VERSION "dbc-export 1 2025.20.8"

NS_ :

BS_:

BU_: ADSP APB APP APS APSB BB BMS CC CMP CMPD CP DAS DI DIF DIR DPB EPAS3P EPAS3S EPASTP EPASTS EPBL EPBR ESP EVSE FC GTW HCML HCMR HVP IBST ICR IDB LS OCS1P PARK PCS PM PMF PMR PNCD PTC RADC RCM RCM2 RCM3 RCU SCCM SCM SCS SDCR TAS TCU TPMS TRCM UI UIS UMC USM VC VCFRONT VCLEFT VCRIGHT VCSEC VEH

BO_ 1294 CP_alertLog: 8 CP
 SG_ CP_alertID M : 0|15@1+ (1,0) [0|32767] "" Vector__XXX
 SG_ CP_alertType : 15|1@1+ (1,0) [0|1] "" Vector__XXX
 SG_ CP_a004_proximityV m4 : 16|16@1+ (0.0001,0) [0|6.5535] "" Vector__XXX
 SG_ CP_a004_cc1Voltage m4 : 32|14@1+ (0.001,0) [0|16.383] "" Vector__XXX
 SG_ CP_a004_cc2Voltage m4 : 48|14@1+ (0.001,0) [0|16.383] "" Vector__XXX
 SG_ CP_a005_cc1Voltage m5 : 16|11@1+ (0.00649731326848,0) [0|13.3000002606] "" Vector__XXX
 SG_ CP_a005_cc2Voltage m5 : 27|9@1+ (0.009784736,0) [0|5.000000096] "" Vector__XXX
 SG_ CP_a005_gbdcState m5 : 36|4@1+ (1,0) [0|15] "" Vector__XXX
 SG_ CP_a005_packCurrent m5 : 40|12@1+ (0.0976801,0) [0|400.0000095] "" Vector__XXX
 SG_ CP_a005_evseCurrent m5 : 52|10@1+ (0.391006857157,0) [0|400.000014872] "" Vector__XXX
 SG_ CP_a005_superchargerConnected m5 : 62|1@1+ (1,0) [0|1] "" Vector__XXX
 SG_ CP_a005_latchEngaged m5 : 63|1@1+ (1,0) [0|1] "" Vector__XXX
 SG_ CP_a006_BMS_FC_limits_MIA m6 : 16|1@1+ (1,0) [0|1] "" Vector__XXX
 SG_ CP_a006_BMS_chargeStatus_MIA m6 : 17|1@1+ (1,0) [0|1] "" Vector__XXX
 SG_ CP_a006_BMS_dcChargeLimits_MIA m6 : 18|1@1+ (1,0) [0|1] "" Vector__XXX
 SG_ CP_a006_BMS_hvPackStatus_MIA m6 : 19|1@1+ (1,0) [0|1] "" Vector__XXX
 SG_ CP_a006_BMS_kwhCounter_MIA m6 : 20|1@1+ (1,0) [0|1] "" Vector__XXX
 SG_ CP_a006_BMS_socStatus_MIA m6 : 21|1@1+ (1,0) [0|1] "" Vector__XXX
 SG_ CP_a008_data1 m8 : 16|16@1+ (1,0) [0|65535] "" Vector__XXX
 SG_ CP_a008_data2 m8 : 32|16@1+ (1,0) [0|65535] "" Vector__XXX
 SG_ CP_a008_FlashWarning m8 : 48|1@1+ (1,0) [0|1] "" Vector__XXX
 SG_ CP_a008_RAMconst_Warning m8 : 49|1@1+ (1,0) [0|1] "" Vector__XXX
 SG_ CP_a008_RAMconst_Fault m8 : 50|1@1+ (1,0) [0|1] "" Vector__XXX
 SG_ CP_a008_AllMemory_warnings m8 : 51|1@1+ (1,0) [0|1] "" Vector__XXX
 SG_ CP_a008_StackAlert m8 : 52|1@1+ (1,0) [0|1] "" Vector__XXX
 SG_ CP_a008_stackUsed m8 : 56|7@1+ (1,0) [0|127] "" Vector__XXX
 SG_ CP_a009_cover1OpenCounts m9 : 16|12@1+ (0.025,0) [0|102.375] "" Vector__XXX
 SG_ CP_a009_cover2OpenCounts m9 : 28|12@1+ (0.025,0) [0|102.375] "" Vector__XXX
 SG_ CP_a009_cover1State m9 : 40|3@1+ (1,0) [0|7] "" Vector__XXX
 SG_ CP_a009_cover2State m9 : 43|3@1+ (1,0) [0|7] "" Vector__XXX
 SG_ CP_a010_periodValid m10 : 16|1@1+ (1,0) [0|1] "" Vector__XXX
 SG_ CP_a010_widthValid m10 : 17|1@1+ (1,0) [0|1] "" Vector__XXX
 SG_ CP_a010_voltageValid m10 : 18|1@1+ (1,0) [0|1] "" Vector__XXX
 SG_ CP_a010_pilotHigh m10 : 19|12@1- (0.008,0) [-16.384|16.376] "" Vector__XXX
 SG_ CP_a010_pilotLow m10 : 32|12@1- (0.008,0) [-16.384|16.376] "" Vector__XXX
 SG_ CP_a010_evseAccept m10 : 44|1@1+ (1,0) [0|1] "" Vector__XXX
 SG_ CP_a010_pilotPWMdetected m10 : 45|1@1+ (1,0) [0|1] "" Vector__XXX
 SG_ CP_a011_eepromErrorType m11 : 16|3@1+ (1,0) [0|7] "" Vector__XXX
 SG_ CP_a015_apsVoltageOV m15 : 16|8@1+ (0.07128516,0) [0|18.1777158] "" Vector__XXX
 SG_ CP_a016_apsVoltageUV m16 : 16|8@1+ (0.07128516,0) [0|18.1777158] "" Vector__XXX
 SG_ CP_a017_5V_VoltageOV m17 : 16|8@1+ (0.02352539,0) [0|5.99897445] "" Vector__XXX
 SG_ CP_a018_5V_VoltageUV m18 : 16|8@1+ (0.02352539,0) [0|5.99897445] "" Vector__XXX
 SG_ CP_a023_stopChargeReason m23 : 16|4@1+ (1,0) [0|15] "" Vector__XXX
 SG_ CP_a023_failureReason m23 : 20|2@1+ (1,0) [0|3] "" Vector__XXX
 SG_ CP_a023_chargeAttempts m23 : 24|3@1+ (1,0) [0|7] "" Vector__XXX
 SG_ CP_a028_canEnable m28 : 16|1@1+ (1,0) [0|1] "" Vector__XXX
 SG_ CP_a028_hardlineEnable m28 : 17|1@1+ (1,0) [0|1] "" Vector__XXX
 SG_ CP_a029_CP_pilot m29 : 16|3@1+ (1,0) [0|7] "" Vector__XXX
 SG_ CP_a029_CP_proximity m29 : 19|2@1+ (1,0) [0|3] "" Vector__XXX
 SG_ CP_a029_CP_chargeDoorOpen m29 : 21|1@1+ (1,0) [0|1] "" Vector__XXX
 SG_ CP_a031_apsVoltage m31 : 16|8@1+ (0.07156863,0) [0|18.25000065] "" Vector__XXX
 SG_ CP_a031_doorCountsFiltered m31 : 24|12@1+ (0.025,0) [0|102.375] "" Vector__XXX
 SG_ CP_a031_inductiveSensorFiltered m31 : 36|18@1+ (82.77924,0) [0|21699998.3113] "" Vector__XXX
 SG_ CP_a031_hallSensorFiltered m31 : 54|10@1+ (0.00488748773932,0) [0|4.99989995732] "" Vector__XXX
 SG_ CP_a032_apsVoltage m32 : 16|8@1+ (0.07156863,0) [0|18.25000065] "" Vector__XXX
 SG_ CP_a032_doorCountsFiltered m32 : 24|12@1+ (0.025,0) [0|102.375] "" Vector__XXX
 SG_ CP_a032_inductiveSensorFiltered m32 : 36|18@1+ (82.77924,0) [0|21699998.3113] "" Vector__XXX
 SG_ CP_a032_hallSensorFiltered m32 : 54|10@1+ (0.00488748773932,0) [0|4.99989995732] "" Vector__XXX
 SG_ CP_a035_latchState m35 : 16|2@1+ (1,0) [0|3] "" Vector__XXX
 SG_ CP_a035_stateLeverMovedFrom m35 : 18|2@1+ (1,0) [0|3] "" Vector__XXX
 SG_ CP_a035_latchOffset m35 : 24|16@1- (0.003051851,0) [-100.003053568|100.000001717] "" Vector__XXX
 SG_ CP_a035_inletID m35 : 40|2@1+ (1,0) [0|3] "" Vector__XXX
 SG_ CP_a036_latchCountsFiltered m36 : 16|16@1+ (0.00152590218931,0) [0|99.9999999764] "" Vector__XXX
 SG_ CP_a036_latchState m36 : 32|2@1+ (1,0) [0|3] "" Vector__XXX
 SG_ CP_a036_CHG_InsertEnable m36 : 34|1@1+ (1,0) [0|1] "" Vector__XXX
 SG_ CP_a036_CP_latchEnableCmd m36 : 35|1@1+ (1,0) [0|1] "" Vector__XXX
 SG_ CP_a036_CP_apsVoltage m36 : 40|8@1+ (0.07156863,0) [0|18.25000065] "" Vector__XXX
 SG_ CP_a036_inletID m36 : 48|2@1+ (1,0) [0|3] "" Vector__XXX
 SG_ CP_a037_latchCountsFiltered m37 : 16|16@1+ (0.00152590218931,0) [0|99.9999999764] "" Vector__XXX
 SG_ CP_a037_latchState m37 : 32|2@1+ (1,0) [0|3] "" Vector__XXX
 SG_ CP_a037_CHG_InsertEnable m37 : 34|1@1+ (1,0) [0|1] "" Vector__XXX
 SG_ CP_a037_CP_latchEnableCmd m37 : 35|1@1+ (1,0) [0|1] "" Vector__XXX
 SG_ CP_a037_CP_apsVoltage m37 : 40|8@1+ (0.07156863,0) [0|18.25000065] "" Vector__XXX
 SG_ CP_a037_inletID m37 : 48|2@1+ (1,0) [0|3] "" Vector__XXX
 SG_ CP_a038_latchCountsFiltered m38 : 16|16@1+ (0.00152590218931,0) [0|99.9999999764] "" Vector__XXX
 SG_ CP_a038_latchState m38 : 32|2@1+ (1,0) [0|3] "" Vector__XXX
 SG_ CP_a038_CHG_InsertEnable m38 : 34|1@1+ (1,0) [0|1] "" Vector__XXX
 SG_ CP_a038_CP_latchEnableCmd m38 : 35|1@1+ (1,0) [0|1] "" Vector__XXX
 SG_ CP_a038_CP_apsVoltage m38 : 40|8@1+ (0.07156863,0) [0|18.25000065] "" Vector__XXX
 SG_ CP_a038_inletID m38 : 48|2@1+ (1,0) [0|3] "" Vector__XXX
 SG_ CP_a041_doorCounts m41 : 16|16@1+ (0.002,0) [0|131.07] "" Vector__XXX
 SG_ CP_a041_inductiveSensorFiltered m41 : 32|18@1+ (82.77924,0) [0|21699998.3113] "" Vector__XXX
 SG_ CP_a041_hallSensorFiltered m41 : 50|10@1+ (0.00488748773932,0) [0|4.99989995732] "" Vector__XXX
 SG_ CP_a042_doorCounts m42 : 16|16@1+ (0.002,0) [0|131.07] "" Vector__XXX
 SG_ CP_a042_inductiveSensorFiltered m42 : 32|18@1+ (82.77924,0) [0|21699998.3113] "" Vector__XXX
 SG_ CP_a042_hallSensorFiltered m42 : 50|10@1+ (0.00488748773932,0) [0|4.99989995732] "" Vector__XXX
 SG_ CP_a043_driftFlag m43 : 16|1@1+ (1,0) [0|1] "" Vector__XXX
 SG_ CP_a043_wrongDirectionFlag m43 : 17|1@1+ (1,0) [0|1] "" Vector__XXX
 SG_ CP_a043_outOfRangeFlag m43 : 18|1@1+ (1,0) [0|1] "" Vector__XXX
 SG_ CP_a043_doorPotFiltered m43 : 19|12@1+ (0.025,0) [0|102.375] "" Vector__XXX
 SG_ CP_a043_doorVelocity m43 : 32|12@1- (0.5,0) [-1024|1023.5] "" Vector__XXX
 SG_ CP_a043_idleDoorPot m43 : 44|12@1+ (0.025,0) [0|102.375] "" Vector__XXX
 SG_ CP_a044_HVP_cpControl_MIA m44 : 16|1@1+ (1,0) [0|1] "" Vector__XXX
 SG_ CP_a045_VCSEC_authentication_MIA m45 : 16|1@1+ (1,0) [0|1] "" Vector__XXX
 SG_ CP_a045_VCSEC_requests_MIA m45 : 17|1@1+ (1,0) [0|1] "" Vector__XXX
 SG_ CP_a046_FC_status_flag m46 : 16|1@1+ (1,0) [0|1] "" Vector__XXX
 SG_ CP_a046_FC_limits_flag m46 : 17|1@1+ (1,0) [0|1] "" Vector__XXX
 SG_ CP_a046_FC_maxLimits_flag m46 : 18|1@1+ (1,0) [0|1] "" Vector__XXX
 SG_ CP_a046_FC_statusHighPower_flag m46 : 19|1@1+ (1,0) [0|1] "" Vector__XXX
 SG_ CP_a046_FC_limitsHighPower_flag m46 : 20|1@1+ (1,0) [0|1] "" Vector__XXX
 SG_ CP_a046_FC_maxLimitsHighPower m46 : 21|1@1+ (1,0) [0|1] "" Vector__XXX
 SG_ CP_a046_CC_chgStatus_flag m46 : 22|1@1+ (1,0) [0|1] "" Vector__XXX
 SG_ CP_a047_okToUseHighPower_MIA m47 : 16|1@1+ (1,0) [0|1] "" Vector__XXX
 SG_ CP_a047_LVPowerState_MIA m47 : 17|1@1+ (1,0) [0|1] "" Vector__XXX
 SG_ CP_a047_sensors_MIA m47 : 18|1@1+ (1,0) [0|1] "" Vector__XXX
 SG_ CP_a047_vehNm_MIA m47 : 19|1@1+ (1,0) [0|1] "" Vector__XXX
 SG_ CP_a048_UI_chargeRequest_MIA m48 : 16|1@1+ (1,0) [0|1] "" Vector__XXX
 SG_ CP_a048_UI_range_MIA m48 : 17|1@1+ (1,0) [0|1] "" Vector__XXX
 SG_ CP_a048_UI_status_MIA m48 : 18|1@1+ (1,0) [0|1] "" Vector__XXX
 SG_ CP_a048_UI_vehicleModes_MIA m48 : 19|1@1+ (1,0) [0|1] "" Vector__XXX
 SG_ CP_a048_UI_hvacRequest_MIA m48 : 20|1@1+ (1,0) [0|1] "" Vector__XXX
 SG_ CP_a048_VEH_billing_MIA m48 : 21|1@1+ (1,0) [0|1] "" Vector__XXX
 SG_ CP_a049_proximity m49 : 16|2@1+ (1,0) [0|3] "" Vector__XXX
 SG_ CP_a050_latch1NotConnected m50 : 16|1@1+ (1,0) [0|1] "" Vector__XXX
 SG_ CP_a050_latch2NotConnected m50 : 17|1@1+ (1,0) [0|1] "" Vector__XXX
 SG_ CP_a051_doorCountsFiltered m51 : 16|12@1+ (0.025,0) [0|102.375] "" Vector__XXX
 SG_ CP_a054_latchCountsFiltered m54 : 16|16@1+ (0.00152590218931,0) [0|99.9999999764] "" Vector__XXX
 SG_ CP_a054_latchState m54 : 32|2@1+ (1,0) [0|3] "" Vector__XXX
 SG_ CP_a054_CHG_InsertEnable m54 : 34|1@1+ (1,0) [0|1] "" Vector__XXX
 SG_ CP_a054_CP_latchEnableCmd m54 : 35|1@1+ (1,0) [0|1] "" Vector__XXX
 SG_ CP_a054_CP_apsVoltage m54 : 40|8@1+ (0.07156863,0) [0|18.25000065] "" Vector__XXX
 SG_ CP_a054_CP_proximity m54 : 48|2@1+ (1,0) [0|3] "" Vector__XXX
 SG_ CP_a054_inletID m54 : 50|2@1+ (1,0) [0|3] "" Vector__XXX
 SG_ CP_a056_latchState m56 : 16|2@1+ (1,0) [0|3] "" Vector__XXX
 SG_ CP_a056_CHG_InsertEnable m56 : 18|1@1+ (1,0) [0|1] "" Vector__XXX
 SG_ CP_a056_CP_latchEnableCmd m56 : 19|1@1+ (1,0) [0|1] "" Vector__XXX
 SG_ CP_a056_CP_proximity m56 : 20|2@1+ (1,0) [0|3] "" Vector__XXX
 SG_ CP_a056_packCurrent m56 : 24|16@1- (0.1,0) [-3276.8|3276.7] "" Vector__XXX
 SG_ CP_a058_CP_pilot m58 : 16|3@1+ (1,0) [0|7] "" Vector__XXX
 SG_ CP_a058_CC_pilot m58 : 19|2@1+ (1,0) [0|3] "" Vector__XXX
 SG_ CP_a058_FC_status m58 : 24|4@1+ (1,0) [0|15] "" Vector__XXX
 SG_ CP_a058_latchState m58 : 28|2@1+ (1,0) [0|3] "" Vector__XXX
 SG_ CP_a058_CP_proximity m58 : 30|2@1+ (1,0) [0|3] "" Vector__XXX
 SG_ CP_a058_acNumRetries m58 : 32|1@1+ (1,0) [0|1] "" Vector__XXX
 SG_ CP_a058_acRetryTimeoutS m58 : 33|15@1+ (1,0) [0|32767] "" Vector__XXX
 SG_ CP_a060_PCS_chgStatus_MIA m60 : 16|1@1+ (1,0) [0|1] "" Vector__XXX
 SG_ CP_a060_PCS_chgLineStatus_MIA m60 : 17|1@1+ (1,0) [0|1] "" Vector__XXX
 SG_ CP_a061_controlState m61 : 16|4@1+ (1,0) [0|15] "" Vector__XXX
 SG_ CP_a061_lastControlState m61 : 20|4@1+ (1,0) [0|15] "" Vector__XXX
 SG_ CP_a061_chipState m61 : 24|3@1+ (1,0) [0|7] "" Vector__XXX
 SG_ CP_a061_timeMsInControlState m61 : 32|16@1+ (1,0) [0|65535] "" Vector__XXX
 SG_ CP_a062_FC_status m62 : 16|4@1+ (1,0) [0|15] "" Vector__XXX
 SG_ CP_a062_FC_type m62 : 20|3@1+ (1,0) [0|7] "" Vector__XXX
 SG_ CP_a063_FC_status m63 : 16|4@1+ (1,0) [0|15] "" Vector__XXX
 SG_ CP_a063_FC_type m63 : 20|3@1+ (1,0) [0|7] "" Vector__XXX
 SG_ CP_a066_pilotHigh m66 : 16|12@1- (0.008,0) [-16.384|16.376] "" Vector__XXX
 SG_ CP_a066_pilotLow m66 : 28|12@1- (0.008,0) [-16.384|16.376] "" Vector__XXX
 SG_ CP_a066_proximity m66 : 40|2@1+ (1,0) [0|3] "" Vector__XXX
 SG_ CP_a067_cc1Voltage m67 : 16|14@1+ (0.001,0) [0|16.383] "" Vector__XXX
 SG_ CP_a067_cc2Voltage m67 : 32|14@1+ (0.001,0) [0|16.383] "" Vector__XXX
 SG_ CP_a068_doorCountsFiltered m68 : 16|12@1+ (0.025,0) [0|102.375] "" Vector__XXX
 SG_ CP_a068_doorClosed m68 : 28|1@1+ (1,0) [0|1] "" Vector__XXX
 SG_ CP_a068_inductiveSensorFiltered m68 : 29|18@1+ (82.77924,0) [0|21699998.3113] "" Vector__XXX
 SG_ CP_a068_hallSensorFiltered m68 : 48|10@1+ (0.00488748773932,0) [0|4.99989995732] "" Vector__XXX
 SG_ CP_a068_doorPresent m68 : 58|1@1+ (1,0) [0|1] "" Vector__XXX
 SG_ CP_a069_inductiveSensor_raw m69 : 16|28@1+ (1,0) [0|268435455] "" Vector__XXX
 SG_ CP_a069_inductiveErrorAmplitude m69 : 44|1@1+ (1,0) [0|1] "" Vector__XXX
 SG_ CP_a069_inductiveErrorWatchdog m69 : 45|1@1+ (1,0) [0|1] "" Vector__XXX
 SG_ CP_a069_inductiveErrorOverRange m69 : 46|1@1+ (1,0) [0|1] "" Vector__XXX
 SG_ CP_a069_inductiveErrorUnderRange m69 : 47|1@1+ (1,0) [0|1] "" Vector__XXX
 SG_ CP_a070_i2cIBCR m70 : 16|8@1+ (1,0) [0|255] "" Vector__XXX
 SG_ CP_a070_i2cIBSR m70 : 24|8@1+ (1,0) [0|255] "" Vector__XXX
 SG_ CP_a071_expectedMessage m71 : 16|4@1+ (1,0) [0|15] "" Vector__XXX
 SG_ CP_a072_currentMessage m72 : 16|4@1+ (1,0) [0|15] "" Vector__XXX
 SG_ CP_a072_readyToChargeExpired m72 : 20|1@1+ (1,0) [0|1] "" Vector__XXX
 SG_ CP_a072_commsSetupExpired m72 : 21|1@1+ (1,0) [0|1] "" Vector__XXX
 SG_ CP_a072_cableCheckExpired m72 : 22|1@1+ (1,0) [0|1] "" Vector__XXX
 SG_ CP_a072_preChargeExpired m72 : 23|1@1+ (1,0) [0|1] "" Vector__XXX
 SG_ CP_a073_ccsManagerState m73 : 16|3@1+ (1,0) [0|7] "" Vector__XXX
 SG_ CP_a073_ccsDcState m73 : 19|4@1+ (1,0) [0|15] "" Vector__XXX
 SG_ CP_a073_ccsShutdownReason m73 : 24|4@1+ (1,0) [0|15] "" Vector__XXX
 SG_ CP_a073_comboHandleNotPresent m73 : 28|1@1+ (1,0) [0|1] "" Vector__XXX
 SG_ CP_a073_commsFault m73 : 29|1@1+ (1,0) [0|1] "" Vector__XXX
 SG_ CP_a073_bmsShutdownRequested m73 : 30|1@1+ (1,0) [0|1] "" Vector__XXX
 SG_ CP_a073_evseShutdownRequested m73 : 31|1@1+ (1,0) [0|1] "" Vector__XXX
 SG_ CP_a073_cpInternalStopChgRequest m73 : 32|1@1+ (1,0) [0|1] "" Vector__XXX
 SG_ CP_a073_v2gCommsEstablished m73 : 33|1@1+ (1,0) [0|1] "" Vector__XXX
 SG_ CP_a073_emergencyShutdown m73 : 34|1@1+ (1,0) [0|1] "" Vector__XXX
 SG_ CP_a073_servicesNotSupported m73 : 35|1@1+ (1,0) [0|1] "" Vector__XXX
 SG_ CP_a073_ccs1AdapterBtnPress m73 : 36|1@1+ (1,0) [0|1] "" Vector__XXX
 SG_ CP_a074_slacState m74 : 16|4@1+ (1,0) [0|15] "" Vector__XXX
 SG_ CP_a074_slacErrorCode m74 : 20|4@1+ (1,0) [0|15] "" Vector__XXX
 SG_ CP_a074_sdpNoDiscoveryResponse m74 : 24|1@1+ (1,0) [0|1] "" Vector__XXX
 SG_ CP_a074_evseMeasuredAtten m74 : 32|8@1+ (1,0) [0|255] "" Vector__XXX
 SG_ CP_a075_evccState m75 : 16|3@1+ (1,0) [0|7] "" Vector__XXX
 SG_ CP_a075_currentMessage m75 : 19|4@1+ (1,0) [0|15] "" Vector__XXX
 SG_ CP_a075_exiUnpackFailed m75 : 23|1@1+ (1,0) [0|1] "" Vector__XXX
 SG_ CP_a075_failedResponseCode m75 : 24|1@1+ (1,0) [0|1] "" Vector__XXX
 SG_ CP_a075_evseMeasuredAtten m75 : 32|8@1+ (1,0) [0|255] "" Vector__XXX
 SG_ CP_a075_evseEmergencyChgEnd m75 : 40|1@1+ (1,0) [0|1] "" Vector__XXX
 SG_ CP_a075_initFailureType m75 : 41|2@1+ (1,0) [0|3] "" Vector__XXX
 SG_ CP_a077_mac1Invalid m77 : 16|1@1+ (1,0) [0|1] "" Vector__XXX
 SG_ CP_a077_mac2Invalid m77 : 17|1@1+ (1,0) [0|1] "" Vector__XXX
 SG_ CP_a077_macsMatching m77 : 18|1@1+ (1,0) [0|1] "" Vector__XXX
 SG_ CP_a078_VC_tempAmbientFiltered m78 : 16|8@1+ (0.5,-40) [-40|87.5] "" Vector__XXX
 SG_ CP_a078_pinTemperature1 m78 : 24|8@1+ (0.8039216,-55) [-55|150.000008] "" Vector__XXX
 SG_ CP_a078_pinTemperature2 m78 : 32|8@1+ (0.8039216,-55) [-55|150.000008] "" Vector__XXX
 SG_ CP_a078_pinTemperature3 m78 : 40|8@1+ (0.8039216,-55) [-55|150.000008] "" Vector__XXX
 SG_ CP_a079_VC_tempAmbientFiltered m79 : 16|8@1+ (0.5,-40) [-40|87.5] "" Vector__XXX
 SG_ CP_a079_pinTemperature1 m79 : 24|8@1+ (0.8039216,-55) [-55|150.000008] "" Vector__XXX
 SG_ CP_a079_pinTemperature2 m79 : 32|8@1+ (0.8039216,-55) [-55|150.000008] "" Vector__XXX
 SG_ CP_a079_pinTemperature3 m79 : 40|8@1+ (0.8039216,-55) [-55|150.000008] "" Vector__XXX
 SG_ CP_a084_proximityV m84 : 16|16@1+ (0.0001,0) [0|6.5535] "" Vector__XXX
 SG_ CP_a084_cc1Voltage m84 : 32|14@1+ (0.001,0) [0|16.383] "" Vector__XXX
 SG_ CP_a084_cc2Voltage m84 : 48|14@1+ (0.001,0) [0|16.383] "" Vector__XXX
 SG_ CP_a085_absoluteTempFault m85 : 16|1@1+ (1,0) [0|1] "" Vector__XXX
 SG_ CP_a085_dcPinTemp m85 : 24|8@1+ (0.8039216,-55) [-55|150.000008] "" Vector__XXX
 SG_ CP_a086_dcPinTemp m86 : 16|8@1+ (0.8039216,-55) [-55|150.000008] "" Vector__XXX
 SG_ CP_a089_gtwPlcSupportType m89 : 16|2@1+ (1,0) [0|3] "" Vector__XXX
 SG_ CP_a089_plcModemPopulated m89 : 18|1@1+ (1,0) [0|1] "" Vector__XXX
 SG_ CP_a090_evseIsoStatus m90 : 16|3@1+ (1,0) [0|7] "" Vector__XXX
 SG_ CP_a090_ccsDcState m90 : 19|4@1+ (1,0) [0|15] "" Vector__XXX
 SG_ CP_a091_fcType m91 : 16|3@1+ (1,0) [0|7] "" Vector__XXX
 SG_ CP_a093_appLoadingNumRetries m93 : 16|3@1+ (1,0) [0|7] "" Vector__XXX
 SG_ CP_a093_interruptCauseRegError m93 : 19|1@1+ (1,0) [0|1] "" Vector__XXX
 SG_ CP_a094_faultResetCount m94 : 16|8@1+ (1,0) [0|255] "" Vector__XXX
 SG_ CP_a095_packCurrent m95 : 16|13@1- (1,0) [-4096|4095] "" Vector__XXX
 SG_ CP_a095_dcOutputCurrent m95 : 32|13@1- (1,0) [-4096|4095] "" Vector__XXX
 SG_ CP_a095_ambientTemp m95 : 48|8@1+ (0.8039216,-55) [-55|150.000008] "" Vector__XXX
 SG_ CP_a095_fcType m95 : 56|3@1+ (1,0) [0|7] "" Vector__XXX
 SG_ CP_a095_fcBrand m95 : 59|1@1+ (1,0) [0|1] "" Vector__XXX
 SG_ CP_a099_proximity m99 : 16|2@1+ (1,0) [0|3] "" Vector__XXX
 SG_ CP_a099_pilot m99 : 18|3@1+ (1,0) [0|7] "" Vector__XXX
 SG_ CP_a103_proximityV m103 : 16|16@1+ (0.0001,0) [0|6.5535] "" Vector__XXX
 SG_ CP_a109_thermistorId m109 : 16|3@1+ (1,0) [0|7] "" Vector__XXX
 SG_ CP_a109_thermistorTemp m109 : 24|8@1+ (0.8039216,-55) [-55|150.000008] "" Vector__XXX
 SG_ CP_a110_thermistorId m110 : 16|3@1+ (1,0) [0|7] "" Vector__XXX
 SG_ CP_a110_thermistorTemp m110 : 24|8@1+ (0.8039216,-55) [-55|150.000008] "" Vector__XXX
 SG_ CP_a110_thermalVelocity m110 : 32|10@1- (0.15748,0) [-80.62976|80.47228] "" Vector__XXX
 SG_ CP_a111_heaterTemperature m111 : 16|8@1+ (0.8039216,-55) [-55|150.000008] "" Vector__XXX
 SG_ CP_a111_VC_tempAmbientFiltered m111 : 24|8@1+ (0.5,-40) [-40|87.5] "" Vector__XXX
 SG_ CP_a112_heaterTemperature m112 : 16|8@1+ (0.8039216,-55) [-55|150.000008] "" Vector__XXX
 SG_ CP_a113_heaterTemperature m113 : 16|8@1+ (0.8039216,-55) [-55|150.000008] "" Vector__XXX
 SG_ CP_a113_heaterCurrent m113 : 24|12@1+ (0.0025,0) [0|10.2375] "" Vector__XXX
 SG_ CP_a116_hvCoverDetected m116 : 16|1@1+ (1,0) [0|1] "" Vector__XXX
 SG_ CP_a116_heaterDetected m116 : 17|1@1+ (1,0) [0|1] "" Vector__XXX
 SG_ CP_a116_temperatureSensorMismatc m116 : 18|1@1+ (1,0) [0|1] "" Vector__XXX
 SG_ CP_a116_thermistorsOpenCircuit m116 : 19|1@1+ (1,0) [0|1] "" Vector__XXX
 SG_ CP_a117_heaterTemperature m117 : 16|8@1+ (0.8039216,-55) [-55|150.000008] "" Vector__XXX
 SG_ CP_a117_averageError m117 : 24|8@1+ (0.8039216,-55) [-55|150.000008] "" Vector__XXX
 SG_ CP_a120_oldProximtyV m120 : 16|10@1+ (0.00488758552819,0) [0|4.99999999534] "" Vector__XXX
 SG_ CP_a120_newProximtyV m120 : 26|10@1+ (0.00488758552819,0) [0|4.99999999534] "" Vector__XXX
 SG_ CP_a120_chargeVoltage m120 : 36|10@1+ (1.171875,0) [0|1198.828125] "" Vector__XXX
 SG_ CP_a120_chargeCurrent m120 : 46|10@1+ (1.7578125,0) [0|1798.2421875] "" Vector__XXX
 SG_ CP_a120_dcPinTemp m120 : 56|8@1+ (0.8039216,-55) [-55|150.000008] "" Vector__XXX
 SG_ CP_a121_CP_status_MIA m121 : 16|1@1+ (1,0) [0|1] "" Vector__XXX
 SG_ CP_a124_ivledState m124 : 16|2@1+ (1,0) [0|3] "" Vector__XXX
 SG_ CP_a124_ivledVoltage m124 : 24|8@1+ (0.01968504,0) [0|5.0196852] "" Vector__XXX
 SG_ CP_a125_okToUseHighPower m125 : 16|1@1+ (1,0) [0|1] "" Vector__XXX
 SG_ CP_a127_HVLINK_cpControl_MIA m127 : 16|1@1+ (1,0) [0|1] "" Vector__XXX
 SG_ CP_a129_bldcDriverState m129 : 16|2@1+ (1,0) [0|3] "" Vector__XXX
 SG_ CP_a130_retryCount m130 : 16|8@1+ (1,0) [0|255] "" Vector__XXX
 SG_ CP_a131_chargeProtocol m131 : 16|3@1+ (1,0) [0|7] "" Vector__XXX
 SG_ CP_a135_sdpErr m135 : 16|3@1+ (1,0) [0|7] "" Vector__XXX
 SG_ CP_a135_pilotState m135 : 19|3@1+ (1,0) [0|7] "" Vector__XXX
 SG_ CP_a135_evseMeasuredAtten m135 : 24|8@1+ (1,0) [0|255] "" Vector__XXX
 SG_ CP_a138_FC_type m138 : 16|3@1+ (1,0) [0|7] "" Vector__XXX
 SG_ CP_a138_latchState m138 : 19|2@1+ (1,0) [0|3] "" Vector__XXX
 SG_ CP_a138_CP_proximity m138 : 21|2@1+ (1,0) [0|3] "" Vector__XXX
 SG_ CP_a139_latchState m139 : 16|2@1+ (1,0) [0|3] "" Vector__XXX
 SG_ CP_a139_CP_proximity m139 : 18|2@1+ (1,0) [0|3] "" Vector__XXX
 SG_ CP_a140_latchState m140 : 16|2@1+ (1,0) [0|3] "" Vector__XXX
 SG_ CP_a140_CP_proximity m140 : 18|2@1+ (1,0) [0|3] "" Vector__XXX
 SG_ CP_a141_latchState m141 : 16|2@1+ (1,0) [0|3] "" Vector__XXX
 SG_ CP_a141_CP_proximity m141 : 18|2@1+ (1,0) [0|3] "" Vector__XXX
 SG_ CP_a142_cc1Voltage m142 : 16|14@1+ (0.001,0) [0|16.383] "" Vector__XXX
 SG_ CP_a142_cc2Voltage m142 : 32|14@1+ (0.001,0) [0|16.383] "" Vector__XXX
 SG_ CP_a143_versionDetected m143 : 16|3@1+ (1,0) [0|7] "" Vector__XXX
 SG_ CP_a146_v2gMessage m146 : 16|4@1+ (1,0) [0|15] "" Vector__XXX
 SG_ CP_a151_pilotHighMin m151 : 16|12@1+ (0.00354090356268,0) [0|14.5000000892] "" Vector__XXX
 SG_ CP_a151_pilotHighMax m151 : 28|12@1+ (0.00354090356268,0) [0|14.5000000892] "" Vector__XXX
 SG_ CP_a151_pilotLowMin m151 : 40|12@1- (0.0105031756684,-5.745237) [-27.2557407689|15.7547635932] "" Vector__XXX
 SG_ CP_a151_pilotLowMax m151 : 52|12@1- (0.0105031756684,-5.745237) [-27.2557407689|15.7547635932] "" Vector__XXX
 SG_ CP_a152_swcanHighMismatchCount m152 : 16|5@1+ (1,0) [0|31] "" Vector__XXX
 SG_ CP_a152_swcanLowMismatchCount m152 : 21|5@1+ (1,0) [0|31] "" Vector__XXX
 SG_ CP_a152_maxPilotSwcanHigh m152 : 26|9@1+ (0.0283757336438,0) [0|14.499999892] "" Vector__XXX
 SG_ CP_a152_minPilotSwcanHigh m152 : 35|9@1+ (0.0283757336438,0) [0|14.499999892] "" Vector__XXX
 SG_ CP_a152_maxPilotSwcanLow m152 : 44|9@1+ (0.0283757336438,0) [0|14.499999892] "" Vector__XXX
 SG_ CP_a152_minPilotSwcanLow m152 : 53|9@1+ (0.0283757336438,0) [0|14.499999892] "" Vector__XXX
 SG_ CP_a153_acPinTempVelocity m153 : 16|10@1- (0.15748,0) [-80.62976|80.47228] "" Vector__XXX
 SG_ CP_a153_acPinTemp1 m153 : 26|8@1+ (0.8039216,-55) [-55|150.000008] "" Vector__XXX
 SG_ CP_a153_acPinTemp2 m153 : 34|8@1+ (0.8039216,-55) [-55|150.000008] "" Vector__XXX
 SG_ CP_a153_ambientTemp m153 : 42|8@1+ (0.8039216,-55) [-55|150.000008] "" Vector__XXX
 SG_ CP_a153_pcsLineChargeCurrent m153 : 50|9@1+ (0.1,0) [0|51.1] "" Vector__XXX
 SG_ CP_a154_acPinTempVelocity m154 : 16|10@1- (0.15748,0) [-80.62976|80.47228] "" Vector__XXX
 SG_ CP_a154_acPinTemp1 m154 : 26|8@1+ (0.8039216,-55) [-55|150.000008] "" Vector__XXX
 SG_ CP_a154_acPinTemp2 m154 : 34|8@1+ (0.8039216,-55) [-55|150.000008] "" Vector__XXX
 SG_ CP_a154_ambientTemp m154 : 42|8@1+ (0.8039216,-55) [-55|150.000008] "" Vector__XXX
 SG_ CP_a154_pcsLineChargeCurrent m154 : 50|9@1+ (0.1,0) [0|51.1] "" Vector__XXX
 SG_ CP_a155_hallSensorVoltage m155 : 16|10@1+ (0.00488758552819,0) [0|4.99999999534] "" Vector__XXX
 SG_ CP_a161_pilotHighMin m161 : 16|12@1+ (0.00354090356268,0) [0|14.5000000892] "" Vector__XXX
 SG_ CP_a161_pilotHighMax m161 : 28|12@1+ (0.00354090356268,0) [0|14.5000000892] "" Vector__XXX
 SG_ CP_a161_pilotLowMin m161 : 40|12@1- (0.0105031756684,-5.745237) [-27.2557407689|15.7547635932] "" Vector__XXX
 SG_ CP_a161_pilotLowMax m161 : 52|12@1- (0.0105031756684,-5.745237) [-27.2557407689|15.7547635932] "" Vector__XXX
 SG_ CP_a162_swcanHighMismatchCount m162 : 16|5@1+ (1,0) [0|31] "" Vector__XXX
 SG_ CP_a162_swcanLowMismatchCount m162 : 21|5@1+ (1,0) [0|31] "" Vector__XXX
 SG_ CP_a162_maxPilotSwcanHigh m162 : 26|9@1+ (0.0283757336438,0) [0|14.499999892] "" Vector__XXX
 SG_ CP_a162_minPilotSwcanHigh m162 : 35|9@1+ (0.0283757336438,0) [0|14.499999892] "" Vector__XXX
 SG_ CP_a162_maxPilotSwcanLow m162 : 44|9@1+ (0.0283757336438,0) [0|14.499999892] "" Vector__XXX
 SG_ CP_a162_minPilotSwcanLow m162 : 53|9@1+ (0.0283757336438,0) [0|14.499999892] "" Vector__XXX
 SG_ CP_a163_cover1OpenCounts m163 : 16|12@1+ (0.025,0) [0|102.375] "" Vector__XXX
 SG_ CP_a163_cover2OpenCounts m163 : 28|12@1+ (0.025,0) [0|102.375] "" Vector__XXX
 SG_ CP_a163_cover1State m163 : 40|3@1+ (1,0) [0|7] "" Vector__XXX
 SG_ CP_a163_cover2State m163 : 43|3@1+ (1,0) [0|7] "" Vector__XXX
 SG_ CP_a164_VC_tempAmbientFiltered m164 : 16|8@1+ (0.5,-40) [-40|87.5] "" Vector__XXX
 SG_ CP_a164_minInternalPinTemp m164 : 24|8@1+ (0.8039216,-55) [-55|150.000008] "" Vector__XXX
 SG_ CP_a173_cover1OpenCounts m173 : 16|12@1+ (0.025,0) [0|102.375] "" Vector__XXX
 SG_ CP_a173_cover2OpenCounts m173 : 28|12@1+ (0.025,0) [0|102.375] "" Vector__XXX
 SG_ CP_a173_cover1State m173 : 40|3@1+ (1,0) [0|7] "" Vector__XXX
 SG_ CP_a173_cover2State m173 : 43|3@1+ (1,0) [0|7] "" Vector__XXX

BO_ 798 CP_alertMatrix: 8 CP
 SG_ CP_matrixIndex M : 0|4@1+ (1,0) [0|15] "" Vector__XXX
 SG_ CP_a001_canRx m0 : 4|1@1+ (1,0) [0|1] "" Vector__XXX
 SG_ CP_a002_canTx m0 : 5|1@1+ (1,0) [0|1] "" Vector__XXX
 SG_ CP_a003_canError m0 : 6|1@1+ (1,0) [0|1] "" Vector__XXX
 SG_ CP_a004_proximityRationality m0 : 7|1@1+ (1,0) [0|1] "" Vector__XXX
 SG_ CP_a005_gbdcLiveDisconnect m0 : 8|1@1+ (1,0) [0|1] "" Vector__XXX
 SG_ CP_a006_lostCommsBMS m0 : 9|1@1+ (1,0) [0|1] "" Vector__XXX
 SG_ CP_a007_watchdog m0 : 10|1@1+ (1,0) [0|1] "" Vector__XXX
 SG_ CP_a008_memoryError m0 : 11|1@1+ (1,0) [0|1] "" Vector__XXX
 SG_ CP_a009_coverOpenAllChgBlocked m0 : 12|1@1+ (1,0) [0|1] "" Vector__XXX
 SG_ CP_a010_pilotRationality m0 : 13|1@1+ (1,0) [0|1] "" Vector__XXX
 SG_ CP_a011_eeprom m0 : 14|1@1+ (1,0) [0|1] "" Vector__XXX
 SG_ CP_a012_ledDriver m0 : 15|1@1+ (1,0) [0|1] "" Vector__XXX
 SG_ CP_a013_lostCommsGTW m0 : 16|1@1+ (1,0) [0|1] "" Vector__XXX
 SG_ CP_a014_lostCommsCHG m0 : 17|1@1+ (1,0) [0|1] "" Vector__XXX
 SG_ CP_a015_apsVov m0 : 18|1@1+ (1,0) [0|1] "" Vector__XXX
 SG_ CP_a016_apsVuv m0 : 19|1@1+ (1,0) [0|1] "" Vector__XXX
 SG_ CP_a017_fiveVov m0 : 20|1@1+ (1,0) [0|1] "" Vector__XXX
 SG_ CP_a018_fiveVuv m0 : 21|1@1+ (1,0) [0|1] "" Vector__XXX
 SG_ CP_a019_threeVov m0 : 22|1@1+ (1,0) [0|1] "" Vector__XXX
 SG_ CP_a020_threeVuv m0 : 23|1@1+ (1,0) [0|1] "" Vector__XXX
 SG_ CP_a021_zeroVov m0 : 24|1@1+ (1,0) [0|1] "" Vector__XXX
 SG_ CP_a022_zeroVuv m0 : 25|1@1+ (1,0) [0|1] "" Vector__XXX
 SG_ CP_a023_gbdcSessionFailed m0 : 26|1@1+ (1,0) [0|1] "" Vector__XXX
 SG_ CP_a024_ledsUC m0 : 27|1@1+ (1,0) [0|1] "" Vector__XXX
 SG_ CP_a025_ledsOC m0 : 28|1@1+ (1,0) [0|1] "" Vector__XXX
 SG_ CP_a026_networkManagement m0 : 29|1@1+ (1,0) [0|1] "" Vector__XXX
 SG_ CP_a027_doorSensorOutOfSpec m0 : 30|1@1+ (1,0) [0|1] "" Vector__XXX
 SG_ CP_a028_insertEnableMismatch m0 : 31|1@1+ (1,0) [0|1] "" Vector__XXX
 SG_ CP_a029_doorClosedProxPilot m0 : 32|1@1+ (1,0) [0|1] "" Vector__XXX
 SG_ CP_a030_busOff m0 : 33|1@1+ (1,0) [0|1] "" Vector__XXX
 SG_ CP_a031_doorClosedCommandedOpen m0 : 34|1@1+ (1,0) [0|1] "" Vector__XXX
 SG_ CP_a032_doorOpenExpectedClosed m0 : 35|1@1+ (1,0) [0|1] "" Vector__XXX
 SG_ CP_a033_spiOpen m0 : 36|1@1+ (1,0) [0|1] "" Vector__XXX
 SG_ CP_a034_calibrationIncomplete m0 : 37|1@1+ (1,0) [0|1] "" Vector__XXX
 SG_ CP_a035_latchMovement_1 m0 : 38|1@1+ (1,0) [0|1] "" Vector__XXX
 SG_ CP_a036_latchNotDisengaged m0 : 39|1@1+ (1,0) [0|1] "" Vector__XXX
 SG_ CP_a037_latchNotEngaged m0 : 40|1@1+ (1,0) [0|1] "" Vector__XXX
 SG_ CP_a038_latchNotBlocking m0 : 41|1@1+ (1,0) [0|1] "" Vector__XXX
 SG_ CP_a039_latchMovement_2 m0 : 42|1@1+ (1,0) [0|1] "" Vector__XXX
 SG_ CP_a040_doNotUse m0 : 43|1@1+ (1,0) [0|1] "" Vector__XXX
 SG_ CP_a041_doorSensorUnplugged m0 : 44|1@1+ (1,0) [0|1] "" Vector__XXX
 SG_ CP_a042_doorAssemblyBroken m0 : 45|1@1+ (1,0) [0|1] "" Vector__XXX
 SG_ CP_a043_doorPotIrrational m0 : 46|1@1+ (1,0) [0|1] "" Vector__XXX
 SG_ CP_a044_lostCommsHVP m0 : 47|1@1+ (1,0) [0|1] "" Vector__XXX
 SG_ CP_a045_lostCommsVCSEC m0 : 48|1@1+ (1,0) [0|1] "" Vector__XXX
 SG_ CP_a046_lostCommsEVSE m0 : 49|1@1+ (1,0) [0|1] "" Vector__XXX
 SG_ CP_a047_lostCommsVCFRONT m0 : 50|1@1+ (1,0) [0|1] "" Vector__XXX
 SG_ CP_a048_lostCommsUI m0 : 51|1@1+ (1,0) [0|1] "" Vector__XXX
 SG_ CP_a049_multipleCablesDetected m0 : 52|1@1+ (1,0) [0|1] "" Vector__XXX
 SG_ CP_a050_latchNotConnected m0 : 53|1@1+ (1,0) [0|1] "" Vector__XXX
 SG_ CP_a051_doorInductiveSensorMIA m0 : 54|1@1+ (1,0) [0|1] "" Vector__XXX
 SG_ CP_a052_chademoNotSupported m0 : 55|1@1+ (1,0) [0|1] "" Vector__XXX
 SG_ CP_a053_proxLatchedNoPilot m0 : 56|1@1+ (1,0) [0|1] "" Vector__XXX
 SG_ CP_a054_cableNotSecured m0 : 57|1@1+ (1,0) [0|1] "" Vector__XXX
 SG_ CP_a055_chargeStoppedNoPilot m0 : 58|1@1+ (1,0) [0|1] "" Vector__XXX
 SG_ CP_a056_proxDisconnected m0 : 59|1@1+ (1,0) [0|1] "" Vector__XXX
 SG_ CP_a057_ccs1AdapterBtnPress m0 : 60|1@1+ (1,0) [0|1] "" Vector__XXX
 SG_ CP_a058_acChargeRetryPending m0 : 61|1@1+ (1,0) [0|1] "" Vector__XXX
 SG_ CP_a059_swcanError m0 : 62|1@1+ (1,0) [0|1] "" Vector__XXX
 SG_ CP_a060_lostCommsPCS m0 : 63|1@1+ (1,0) [0|1] "" Vector__XXX
 SG_ CP_a061_uhfReceiverMIA m1 : 4|1@1+ (1,0) [0|1] "" Vector__XXX
 SG_ CP_a062_scOutOfService m1 : 5|1@1+ (1,0) [0|1] "" Vector__XXX
 SG_ CP_a063_scUpdateInProgress m1 : 6|1@1+ (1,0) [0|1] "" Vector__XXX
 SG_ CP_a064_superchargingBlocked m1 : 7|1@1+ (1,0) [0|1] "" Vector__XXX
 SG_ CP_a065_selfTestFailed m1 : 8|1@1+ (1,0) [0|1] "" Vector__XXX
 SG_ CP_a066_proxLatchedIdlePilot m1 : 9|1@1+ (1,0) [0|1] "" Vector__XXX
 SG_ CP_a067_gbdcConnFault m1 : 10|1@1+ (1,0) [0|1] "" Vector__XXX
 SG_ CP_a068_doorSensorMismatch m1 : 11|1@1+ (1,0) [0|1] "" Vector__XXX
 SG_ CP_a069_doorInductiveSensorError m1 : 12|1@1+ (1,0) [0|1] "" Vector__XXX
 SG_ CP_a070_doorInductiveSensorReset m1 : 13|1@1+ (1,0) [0|1] "" Vector__XXX
 SG_ CP_a071_exiDecodeFailure m1 : 14|1@1+ (1,0) [0|1] "" Vector__XXX
 SG_ CP_a072_v2gEvccTimeout m1 : 15|1@1+ (1,0) [0|1] "" Vector__XXX
 SG_ CP_a073_iecComboShutdown m1 : 16|1@1+ (1,0) [0|1] "" Vector__XXX
 SG_ CP_a074_failedToEstablishV2gComm m1 : 17|1@1+ (1,0) [0|1] "" Vector__XXX
 SG_ CP_a075_v2gCommsFailure m1 : 18|1@1+ (1,0) [0|1] "" Vector__XXX
 SG_ CP_a076_LDC1612errorWatchdog m1 : 19|1@1+ (1,0) [0|1] "" Vector__XXX
 SG_ CP_a077_invalidMacAddress m1 : 20|1@1+ (1,0) [0|1] "" Vector__XXX
 SG_ CP_a078_latchNotDisengagedCold m1 : 21|1@1+ (1,0) [0|1] "" Vector__XXX
 SG_ CP_a079_cableNotSecuredCold m1 : 22|1@1+ (1,0) [0|1] "" Vector__XXX
 SG_ CP_a080_taskStackOverflow m1 : 23|1@1+ (1,0) [0|1] "" Vector__XXX
 SG_ CP_a081_swException m1 : 24|1@1+ (1,0) [0|1] "" Vector__XXX
 SG_ CP_a082_powerOnReset m1 : 25|1@1+ (1,0) [0|1] "" Vector__XXX
 SG_ CP_a083_watchdogTraceData m1 : 26|1@1+ (1,0) [0|1] "" Vector__XXX
 SG_ CP_a084_proxPeDisconnected_gb m1 : 27|1@1+ (1,0) [0|1] "" Vector__XXX
 SG_ CP_a085_dcPinTempFaulted m1 : 28|1@1+ (1,0) [0|1] "" Vector__XXX
 SG_ CP_a086_dcPinTempIrrational m1 : 29|1@1+ (1,0) [0|1] "" Vector__XXX
 SG_ CP_a087_dcTempModelFault m1 : 30|1@1+ (1,0) [0|1] "" Vector__XXX
 SG_ CP_a088_dcTempModelDeviation m1 : 31|1@1+ (1,0) [0|1] "" Vector__XXX
 SG_ CP_a089_plcConfigMismatch m1 : 32|1@1+ (1,0) [0|1] "" Vector__XXX
 SG_ CP_a090_ccsEvseLowIso m1 : 33|1@1+ (1,0) [0|1] "" Vector__XXX
 SG_ CP_a091_wrongSuperchargerHandle m1 : 34|1@1+ (1,0) [0|1] "" Vector__XXX
 SG_ CP_a092_modemAppLoadFailed m1 : 35|1@1+ (1,0) [0|1] "" Vector__XXX
 SG_ CP_a093_modemLoadedWithReset m1 : 36|1@1+ (1,0) [0|1] "" Vector__XXX
 SG_ CP_a094_inductiveResetSuccessful m1 : 37|1@1+ (1,0) [0|1] "" Vector__XXX
 SG_ CP_a095_thermalDcLimitActive m1 : 38|1@1+ (1,0) [0|1] "" Vector__XXX
 SG_ CP_a096_pilotWake m1 : 39|1@1+ (1,0) [0|1] "" Vector__XXX
 SG_ CP_a097_modeTransitionFailure m1 : 40|1@1+ (1,0) [0|1] "" Vector__XXX
 SG_ CP_a098_proximityWake m1 : 41|1@1+ (1,0) [0|1] "" Vector__XXX
 SG_ CP_a099_cableStateUnknown m1 : 42|1@1+ (1,0) [0|1] "" Vector__XXX
 SG_ CP_a100_inletHarnessIdIrrational m1 : 43|1@1+ (1,0) [0|1] "" Vector__XXX
 SG_ CP_a101_wcFoldbackActive m1 : 44|1@1+ (1,0) [0|1] "" Vector__XXX
 SG_ CP_a102_wcOvertempFault m1 : 45|1@1+ (1,0) [0|1] "" Vector__XXX
 SG_ CP_a103_proximityPeDisconnected m1 : 46|1@1+ (1,0) [0|1] "" Vector__XXX
 SG_ CP_a104_uhfResetSuccessful m1 : 47|1@1+ (1,0) [0|1] "" Vector__XXX
 SG_ CP_a105_hwUnableToSleep m1 : 48|1@1+ (1,0) [0|1] "" Vector__XXX
 SG_ CP_a106_uhfReceiverReset m1 : 49|1@1+ (1,0) [0|1] "" Vector__XXX
 SG_ CP_a107_chademoFoldbackActive m1 : 50|1@1+ (1,0) [0|1] "" Vector__XXX
 SG_ CP_a108_chademoOvertempFault m1 : 51|1@1+ (1,0) [0|1] "" Vector__XXX
 SG_ CP_a109_thermistorIrrational m1 : 52|1@1+ (1,0) [0|1] "" Vector__XXX
 SG_ CP_a110_thermalVelocityHigh m1 : 53|1@1+ (1,0) [0|1] "" Vector__XXX
 SG_ CP_a111_inletHeaterUnableToHeat m1 : 54|1@1+ (1,0) [0|1] "" Vector__XXX
 SG_ CP_a112_inletHeaterIrrationalTem m1 : 55|1@1+ (1,0) [0|1] "" Vector__XXX
 SG_ CP_a113_inletHeaterShortCircuit m1 : 56|1@1+ (1,0) [0|1] "" Vector__XXX
 SG_ CP_a114_ccsEvseFailed m1 : 57|1@1+ (1,0) [0|1] "" Vector__XXX
 SG_ CP_a115_unexpectedTcan1145State m1 : 58|1@1+ (1,0) [0|1] "" Vector__XXX
 SG_ CP_a116_misconfigurationDetected m1 : 59|1@1+ (1,0) [0|1] "" Vector__XXX
 SG_ CP_a117_inletHeaterUnableToRegul m1 : 60|1@1+ (1,0) [0|1] "" Vector__XXX
 SG_ CP_a118_iecComboLockUp m1 : 61|1@1+ (1,0) [0|1] "" Vector__XXX
 SG_ CP_a119_plcTransmitFailure m1 : 62|1@1+ (1,0) [0|1] "" Vector__XXX
 SG_ CP_a120_comboAdapterFoldback m1 : 63|1@1+ (1,0) [0|1] "" Vector__XXX
 SG_ CP_a121_PLCRLY_lostCommsCP m2 : 4|1@1+ (1,0) [0|1] "" Vector__XXX
 SG_ CP_a122_plcModemFailure m2 : 5|1@1+ (1,0) [0|1] "" Vector__XXX
 SG_ CP_a123_latchPotIrrational m2 : 6|1@1+ (1,0) [0|1] "" Vector__XXX
 SG_ CP_a124_ivledFault m2 : 7|1@1+ (1,0) [0|1] "" Vector__XXX
 SG_ CP_a125_unexpectedLVJuiceState m2 : 8|1@1+ (1,0) [0|1] "" Vector__XXX
 SG_ CP_a126_wakeOnUhfFault m2 : 9|1@1+ (1,0) [0|1] "" Vector__XXX
 SG_ CP_a127_lostCommsHVLINK m2 : 10|1@1+ (1,0) [0|1] "" Vector__XXX
 SG_ CP_a128_lostCommsVC m2 : 11|1@1+ (1,0) [0|1] "" Vector__XXX
 SG_ CP_a129_bldcDriverCommsFailed m2 : 12|1@1+ (1,0) [0|1] "" Vector__XXX
 SG_ CP_a130_bldcDriverCommsRecovered m2 : 13|1@1+ (1,0) [0|1] "" Vector__XXX
 SG_ CP_a131_evseCommTimeout m2 : 14|1@1+ (1,0) [0|1] "" Vector__XXX
 SG_ CP_a132_contractAuthTimeout m2 : 15|1@1+ (1,0) [0|1] "" Vector__XXX
 SG_ CP_a133_proxNeverLatched m2 : 16|1@1+ (1,0) [0|1] "" Vector__XXX
 SG_ CP_a134_plcModemNotExpected m2 : 17|1@1+ (1,0) [0|1] "" Vector__XXX
 SG_ CP_a135_sdpAttemptsFailed m2 : 18|1@1+ (1,0) [0|1] "" Vector__XXX
 SG_ CP_a136_sdpSideReqFailed m2 : 19|1@1+ (1,0) [0|1] "" Vector__XXX
 SG_ CP_a137_plcForwardError m2 : 20|1@1+ (1,0) [0|1] "" Vector__XXX
 SG_ CP_a138_swcanCommsAcEvseFaulted m2 : 21|1@1+ (1,0) [0|1] "" Vector__XXX
 SG_ CP_a139_pilotFaulted m2 : 22|1@1+ (1,0) [0|1] "" Vector__XXX
 SG_ CP_a140_superchargerFaulted m2 : 23|1@1+ (1,0) [0|1] "" Vector__XXX
 SG_ CP_a141_chademoAdapterFault m2 : 24|1@1+ (1,0) [0|1] "" Vector__XXX
 SG_ CP_a142_gbdcScConnFault m2 : 25|1@1+ (1,0) [0|1] "" Vector__XXX
 SG_ CP_a143_unsupportedChargeAdapter m2 : 26|1@1+ (1,0) [0|1] "" Vector__XXX
 SG_ CP_a144_nvmInitFailed m2 : 27|1@1+ (1,0) [0|1] "" Vector__XXX
 SG_ CP_a145_modemAppLoadFailedNA m2 : 28|1@1+ (1,0) [0|1] "" Vector__XXX
 SG_ CP_a146_ccsEvseMalfunction m2 : 29|1@1+ (1,0) [0|1] "" Vector__XXX
 SG_ CP_a147_inductiveRecoveredMia m2 : 30|1@1+ (1,0) [0|1] "" Vector__XXX
 SG_ CP_a148_bldcTachFeedbackMia m2 : 31|1@1+ (1,0) [0|1] "" Vector__XXX
 SG_ CP_a149_pilotPeriodInvalid m2 : 32|1@1+ (1,0) [0|1] "" Vector__XXX
 SG_ CP_a150_railToggleTimeout m2 : 33|1@1+ (1,0) [0|1] "" Vector__XXX
 SG_ CP_a151_badPilotDiodeDetected m2 : 34|1@1+ (1,0) [0|1] "" Vector__XXX
 SG_ CP_a152_pilotEdgeDetectionFailed m2 : 35|1@1+ (1,0) [0|1] "" Vector__XXX
 SG_ CP_a153_thermalAcLimitActive m2 : 36|1@1+ (1,0) [0|1] "" Vector__XXX
 SG_ CP_a154_acChargingStoppedOT m2 : 37|1@1+ (1,0) [0|1] "" Vector__XXX
 SG_ CP_a155_hallPresenceRationality m2 : 38|1@1+ (1,0) [0|1] "" Vector__XXX
 SG_ CP_a156_gbdcPrechargingConcern m2 : 39|1@1+ (1,0) [0|1] "" Vector__XXX
 SG_ CP_a157_doorOpenRateLimiter m2 : 40|1@1+ (1,0) [0|1] "" Vector__XXX
 SG_ CP_a158_doorCloseRateLimiter m2 : 41|1@1+ (1,0) [0|1] "" Vector__XXX
 SG_ CP_a159_swcanHealthCheckFailed m2 : 42|1@1+ (1,0) [0|1] "" Vector__XXX
 SG_ CP_a160_latchDisengageInDcCharge m2 : 43|1@1+ (1,0) [0|1] "" Vector__XXX
 SG_ CP_a161_badPilotDiodeDetectedCN m2 : 44|1@1+ (1,0) [0|1] "" Vector__XXX
 SG_ CP_a162_pilotEdgeDetectionFailed m2 : 45|1@1+ (1,0) [0|1] "" Vector__XXX
 SG_ CP_a163_coverOpenDcChgBlocked m2 : 46|1@1+ (1,0) [0|1] "" Vector__XXX
 SG_ CP_a164_latchRedisengageRequeste m2 : 47|1@1+ (1,0) [0|1] "" Vector__XXX
 SG_ CP_a165_proxWiggleDetected m2 : 48|1@1+ (1,0) [0|1] "" Vector__XXX
 SG_ CP_a166_faultLineMismatchDetecte m2 : 49|1@1+ (1,0) [0|1] "" Vector__XXX
 SG_ CP_a167_doorIdIrrational m2 : 50|1@1+ (1,0) [0|1] "" Vector__XXX
 SG_ CP_a172_triggerOdin m2 : 55|1@1+ (1,0) [0|1] "" Vector__XXX
 SG_ CP_a173_coverOpenAcChgBlocked m2 : 56|1@1+ (1,0) [0|1] "" Vector__XXX
 SG_ CP_a174_fwdedMsgLoadWarning m2 : 57|1@1+ (1,0) [0|1] "" Vector__XXX
 SG_ CP_a175_fwdedMsgDropped m2 : 58|1@1+ (1,0) [0|1] "" Vector__XXX
 SG_ CP_a177_incompatibleV2lDeviceDet m2 : 60|1@1+ (1,0) [0|1] "" Vector__XXX
 SG_ CP_a179_evseCommsTlsError m2 : 62|1@1+ (1,0) [0|1] "" Vector__XXX
 SG_ CP_a182_pncdCommsError m3 : 5|1@1+ (1,0) [0|1] "" Vector__XXX
 SG_ CP_a183_certManagerError m3 : 6|1@1+ (1,0) [0|1] "" Vector__XXX
 SG_ CP_a184_certChangeEvent m3 : 7|1@1+ (1,0) [0|1] "" Vector__XXX
 SG_ CP_a185_pncAuthRejection m3 : 8|1@1+ (1,0) [0|1] "" Vector__XXX
 SG_ CP_a186_spiDmaFailure m3 : 9|1@1+ (1,0) [0|1] "" Vector__XXX
 SG_ CP_a187_highStackUsage m3 : 10|1@1+ (1,0) [0|1] "" Vector__XXX

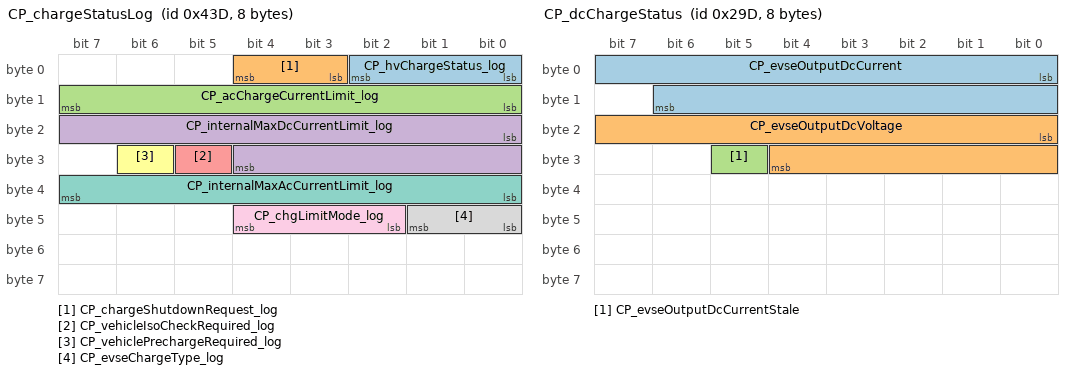
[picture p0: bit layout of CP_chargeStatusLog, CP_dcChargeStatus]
BO_ 1085 CP_chargeStatusLog: 8 CP
 SG_ CP_hvChargeStatus_log : 0|3@1+ (1,0) [0|7] "" Vector__XXX
 SG_ CP_chargeShutdownRequest_log : 3|2@1+ (1,0) [0|3] "" Vector__XXX
 SG_ CP_acChargeCurrentLimit_log : 8|8@1+ (0.5,0) [0|127.5] "" Vector__XXX
 SG_ CP_internalMaxDcCurrentLimit_log : 16|13@1+ (0.25,0) [0|2047.75] "" Vector__XXX
 SG_ CP_vehicleIsoCheckRequired_log : 29|1@1+ (1,0) [0|1] "" Vector__XXX
 SG_ CP_vehiclePrechargeRequired_log : 30|1@1+ (1,0) [0|1] "" Vector__XXX
 SG_ CP_internalMaxAcCurrentLimit_log : 32|8@1+ (0.5,0) [0|127.5] "" Vector__XXX
 SG_ CP_evseChargeType_log : 40|2@1+ (1,0) [0|3] "" Vector__XXX
 SG_ CP_chgLimitMode_log : 42|3@1+ (1,0) [0|7] "" Vector__XXX

BO_ 669 CP_dcChargeStatus: 8 CP
 SG_ CP_evseOutputDcCurrent : 0|15@1- (0.125,0) [-2048|2047.875] "A" Vector__XXX
 SG_ CP_evseOutputDcVoltage : 16|13@1+ (0.07324219,0) [0|599.92675822] "V" Vector__XXX
 SG_ CP_evseOutputDcCurrentStale : 29|1@1+ (1,0) [0|1] "" Vector__XXX

BO_ 541 CP_evseStatus: 8 CP
 SG_ CP_evseAccept : 0|1@1+ (1,0) [0|1] "" Vector__XXX
 SG_ CP_evseRequest : 1|1@1+ (1,0) [0|1] "" Vector__XXX
 SG_ CP_proximity : 2|2@1+ (1,0) [0|3] "" Vector__XXX
 SG_ CP_pilot : 4|3@1+ (1,0) [0|7] "" Vector__XXX
 SG_ CP_digitalCommsEstablished : 7|1@1+ (1,0) [0|1] "" Vector__XXX
 SG_ CP_pilotCurrent : 8|8@1+ (0.5,0) [0|127.5] "A" Vector__XXX
 SG_ CP_cableType : 16|3@1+ (1,0) [0|7] "" Vector__XXX
 SG_ CP_iecPilotState : 19|4@1+ (1,0) [0|15] "" Vector__XXX
 SG_ CP_plcSupported : 23|1@1+ (1,0) [0|1] "" Vector__XXX
 SG_ CP_cableCurrentLimit : 24|7@1+ (1,0) [0|127] "A" Vector__XXX
 SG_ CP_teslaSwcanState : 34|4@1+ (1,0) [0|15] "" Vector__XXX
 SG_ CP_evseChargeType_UI : 38|2@1+ (1,0) [0|3] "" Vector__XXX
 SG_ CP_gbState : 40|4@1+ (1,0) [0|15] "" Vector__XXX
 SG_ CP_gbdcStopChargeReason : 44|4@1+ (1,0) [0|15] "" Vector__XXX
 SG_ CP_gbdcFailureReason : 48|2@1+ (1,0) [0|3] "" Vector__XXX
 SG_ CP_gbdcChargeAttempts : 50|2@1+ (1,0) [0|3] "" Vector__XXX
 SG_ CP_acChargeState : 52|3@1+ (1,0) [0|7] "" Vector__XXX
 SG_ CP_teslaDcState : 56|4@1+ (1,0) [0|15] "" Vector__XXX

BO_ 1342 CP_info: 8 CP
 SG_ CP_infoIndex M : 0|8@1+ (1,0) [0|255] "" Vector__XXX
 SG_ CP_buildType m10 : 8|3@1+ (1,0) [0|7] "" Vector__XXX
 SG_ CP_buildConfigId m10 : 16|16@1+ (1,0) [0|65535] "" Vector__XXX
 SG_ CP_hardwareId m10 : 32|16@1+ (1,0) [0|65535] "" Vector__XXX
 SG_ CP_componentId m10 : 48|16@1+ (1,0) [0|65535] "" Vector__XXX
 SG_ CP_pcbaId m11 : 16|8@1+ (1,0) [0|255] "" Vector__XXX
 SG_ CP_assemblyId m11 : 24|8@1+ (1,0) [0|255] "" Vector__XXX
 SG_ CP_usageId m11 : 32|16@1+ (1,0) [0|65535] "" Vector__XXX
 SG_ CP_subUsageId m11 : 48|16@1+ (1,0) [0|65535] "" Vector__XXX
 SG_ CP_platformType m13 : 8|8@1+ (1,0) [0|255] "" Vector__XXX
 SG_ CP_appCrc m13 : 32|32@1+ (1,0) [0|4294967295] "" Vector__XXX
 SG_ CP_appGitHash m17 : 8|56@1+ (1,0) [0|7.20575940379e+16] "" Vector__XXX
 SG_ CP_bootGitHash m18 : 8|56@1+ (1,0) [0|7.20575940379e+16] "" Vector__XXX
 SG_ CP_bootUdsProtoVersion m20 : 8|8@1+ (1,0) [0|255] "" Vector__XXX
 SG_ CP_bootCrc m20 : 32|32@1+ (1,0) [0|4294967295] "" Vector__XXX

BO_ 1885 CP_loggingFast: 8 CP
 SG_ CP_loggingFastSelect M : 0|4@1+ (1,0) [0|15] "" Vector__XXX
 SG_ CP_inductiveSensor_raw m0 : 4|28@1+ (1,0) [0|268435455] "" Vector__XXX
 SG_ CP_doorOpenActuationTime m0 : 32|14@1+ (1,0) [0|16383] "ms" Vector__XXX
 SG_ CP_doorCloseActuationTime m0 : 46|14@1+ (1,0) [0|16383] "ms" Vector__XXX
 SG_ CP_chargeCableSecured m0 : 60|1@1+ (1,0) [0|1] "" Vector__XXX
 SG_ CP_chargeCablePresent m0 : 61|1@1+ (1,0) [0|1] "" Vector__XXX
 SG_ CP_latchCheckAvailable m0 : 62|1@1+ (1,0) [0|1] "" Vector__XXX
 SG_ CP_UHF_controlState m2 : 4|4@1+ (1,0) [0|15] "" Vector__XXX
 SG_ CP_proximityV m2 : 8|16@1+ (0.0001,0) [0|6.5535] "V" Vector__XXX
 SG_ CP_proximityV_GBCC1 m2 : 24|14@1+ (0.001,0) [0|13.3] "V" Vector__XXX
 SG_ CP_proximityV_GBCC2 m2 : 38|14@1+ (0.001,0) [0|13.3] "V" Vector__XXX
 SG_ CP_doorPot m2 : 52|12@1+ (0.025,0) [0|100] "%" Vector__XXX
 SG_ CP_doorPresenceHallSensorV m3 : 4|12@1+ (0.001221,0) [0|4.999995] "" Vector__XXX
 SG_ CP_doorOpenRequest m3 : 16|4@1+ (1,0) [0|15] "" Vector__XXX
 SG_ CP_doorOpenEndOfDriveReason m3 : 20|3@1+ (1,0) [0|7] "" Vector__XXX
 SG_ CP_coverClosed m3 : 23|1@1+ (1,0) [0|1] "" Vector__XXX
 SG_ CP_doorCloseEndOfDriveReason m3 : 24|3@1+ (1,0) [0|7] "" Vector__XXX
 SG_ CP_doorCloseRequest m3 : 27|5@1+ (1,0) [0|31] "" Vector__XXX
 SG_ CP_latchDisengagingTime m3 : 32|10@1+ (1,0) [0|1023] "ms" Vector__XXX
 SG_ CP_latchEngagingTime m3 : 42|10@1+ (1,0) [0|1023] "ms" Vector__XXX
 SG_ CP_latchDisengagingStopReason m3 : 52|3@1+ (1,0) [0|7] "" Vector__XXX
 SG_ CP_latchEngagingStopReason m3 : 56|3@1+ (1,0) [0|7] "" Vector__XXX
 SG_ CP_doorIdDetectionState m3 : 59|2@1+ (1,0) [0|3] "" Vector__XXX
 SG_ CP_doorIdDetectedBin m3 : 61|2@1+ (1,0) [0|3] "" Vector__XXX

BO_ 2042 CP_loggingSlow: 8 CP
 SG_ CP_loggingSlowSelect M : 0|4@1+ (1,0) [0|15] "" Vector__XXX
 SG_ CP_UHF_chipState m3 : 4|3@1+ (1,0) [0|7] "" Vector__XXX
 SG_ CP_UHF_rssi m3 : 8|8@1+ (1,0) [0|255] "" Vector__XXX
 SG_ CP_UHF_rxOverflow m3 : 16|1@1+ (1,0) [0|1] "" Vector__XXX
 SG_ CP_UHF_rxNumBytes m3 : 17|8@1+ (1,0) [0|255] "" Vector__XXX
 SG_ CP_UHF_selfTestRssi m3 : 25|8@1+ (1,0) [0|255] "" Vector__XXX
 SG_ CP_latchI m3 : 33|12@1+ (0.0025,0) [0|10.2375] "A" Vector__XXX
 SG_ CP_inlet1HarnessIdState m3 : 45|2@1+ (1,0) [0|3] "" Vector__XXX
 SG_ CP_inlet1HarnessIdValue m3 : 47|3@1+ (1,0) [0|7] "" Vector__XXX
 SG_ CP_inlet2HarnessIdState m3 : 50|2@1+ (1,0) [0|3] "" Vector__XXX
 SG_ CP_inlet2HarnessIdValue m3 : 52|3@1+ (1,0) [0|7] "" Vector__XXX
 SG_ CP_inletHeaterState m3 : 55|2@1+ (1,0) [0|3] "" Vector__XXX
 SG_ CP_inletHeaterDuty m3 : 57|7@1+ (1,0) [0|100] "%" Vector__XXX
 SG_ CP_nvm_dataValid m5 : 4|1@1+ (1,0) [0|1] "" Vector__XXX
 SG_ CP_nvm_doorOpenCycles m5 : 8|16@1+ (1,0) [0|65535] "" Vector__XXX
 SG_ CP_nvm_doorCloseCycles m5 : 24|16@1+ (1,0) [0|65535] "" Vector__XXX
 SG_ CP_nvm_doorOpen m5 : 40|1@1+ (1,0) [0|1] "" Vector__XXX
 SG_ CP_nvm_doorPresent m5 : 41|1@1+ (1,0) [0|1] "" Vector__XXX
 SG_ CP_nvm_doorPresentValid m5 : 42|1@1+ (1,0) [0|1] "" Vector__XXX
 SG_ CP_nvm_badPilotDiodeDetected m5 : 43|1@1+ (1,0) [0|1] "" Vector__XXX
 SG_ CP_nvm_pilotDiodeFaultCount m5 : 44|3@1+ (1,0) [0|7] "" Vector__XXX
 SG_ CP_doorOpenLimiterMaxCount m5 : 47|4@1+ (1,0) [0|15] "counts" Vector__XXX
 SG_ CP_doorOpenLimiterMaxRequestType m5 : 51|4@1+ (1,0) [0|15] "" Vector__XXX
 SG_ CP_doorCloseLimiterMaxCount m5 : 55|4@1+ (1,0) [0|15] "counts" Vector__XXX
 SG_ CP_doorCloseLimiterMaxRequestTyp m5 : 59|5@1+ (1,0) [0|31] "" Vector__XXX

BO_ 528 CP_status: 8 CP
 SG_ CP_type : 0|2@1+ (1,0) [0|3] "" Vector__XXX
 SG_ CP_insertEnableLine : 2|1@1+ (1,0) [0|1] "" Vector__XXX
 SG_ CP_latchState : 3|2@1+ (1,0) [0|3] "" Vector__XXX
 SG_ CP_permanentPowerRequest : 5|1@1+ (1,0) [0|1] "" Vector__XXX
 SG_ CP_chargeDoorOpen : 6|1@1+ (1,0) [0|1] "" Vector__XXX
 SG_ CP_doorControlState : 8|3@1+ (1,0) [0|7] "" Vector__XXX
 SG_ CP_doorButtonPressed : 11|1@1+ (1,0) [0|1] "" Vector__XXX
 SG_ CP_swcanRelayClosed : 12|1@1+ (1,0) [0|1] "" Vector__XXX
 SG_ CP_inhibitOta : 13|1@1+ (1,0) [0|1] "" Vector__XXX
 SG_ CP_chargeCableState : 14|2@1+ (1,0) [0|3] "" Vector__XXX
 SG_ CP_latchControlState : 16|3@1+ (1,0) [0|7] "" Vector__XXX
 SG_ CP_ledColor : 19|4@1+ (1,0) [0|15] "" Vector__XXX
 SG_ CP_UHF_handleFound : 23|1@1+ (1,0) [0|1] "" Vector__XXX
 SG_ CP_faultLineSensed : 24|1@1+ (1,0) [0|1] "" Vector__XXX
 SG_ CP_doorPresenceState : 25|3@1+ (1,0) [0|7] "" Vector__XXX
 SG_ CP_inductiveSensorState : 28|3@1+ (1,0) [0|7] "" Vector__XXX
 SG_ CP_chargeDoorOpenUI : 31|1@1+ (1,0) [0|1] "" Vector__XXX
 SG_ CP_vehicleUnlockRequest : 32|1@1+ (1,0) [0|1] "" Vector__XXX
 SG_ CP_coldWeatherMode : 33|1@1+ (1,0) [0|1] "" Vector__XXX
 SG_ CP_hvInletExposed : 34|1@1+ (1,0) [0|1] "" Vector__XXX
 SG_ CP_latchEngaged : 35|1@1+ (1,0) [0|1] "" Vector__XXX
 SG_ CP_inletHeaterUiState : 40|3@1+ (1,0) [0|7] "" Vector__XXX

BO_ 893 CP_thermalStatus: 8 CP
 SG_ CP_thermalStatusSelect M : 0|1@1+ (1,0) [0|1] "" Vector__XXX
 SG_ CP_pinTemperature1 m1 : 8|8@1+ (0.8039216,-55) [-55|149.99] "C" Vector__XXX
 SG_ CP_pinTemperature2 m1 : 16|8@1+ (0.8039216,-55) [-55|149.99] "C" Vector__XXX
 SG_ CP_pinTemperature3 m1 : 24|8@1+ (0.8039216,-55) [-55|149.99] "C" Vector__XXX

BO_ 1465 DAS_alertLog: 8 DAS
 SG_ DAS_alertID M : 0|15@1+ (1,0) [0|32767] "" Vector__XXX
 SG_ DAS_alertState : 15|1@1+ (1,0) [0|1] "" Vector__XXX
 SG_ DAS_sw073_escalateLDWs m73 : 16|1@1+ (1,0) [0|1] "" Vector__XXX
 SG_ DAS_sw073_silentEscalatedLDW m73 : 17|1@1+ (1,0) [0|1] "" Vector__XXX
 SG_ DAS_sw073_escalateLDWreason m73 : 18|3@1+ (1,0) [0|7] "" Vector__XXX
 SG_ DAS_sw073_rawMobileyeLDW m73 : 21|2@1+ (1,0) [0|3] "" Vector__XXX
 SG_ DAS_sw073_freespaceLDW m73 : 24|2@1+ (1,0) [0|3] "" Vector__XXX
 SG_ DAS_sw073_freespaceLeftC0 m73 : 26|7@1+ (0.2,-12.8) [-12.8|12.6] "" Vector__XXX
 SG_ DAS_sw073_freespaceRightC0 m73 : 33|7@1+ (0.2,-12.8) [-12.8|12.6] "" Vector__XXX
 SG_ DAS_sw073_freespaceLeftC1 m73 : 40|8@1+ (0.0016,-0.2) [-0.2|0.208] "" Vector__XXX
 SG_ DAS_sw073_freespaceRightC1 m73 : 48|8@1+ (0.0016,-0.2) [-0.2|0.208] "" Vector__XXX
 SG_ DAS_sw073_freespaceLeftFarZ m73 : 56|4@1+ (4,0) [0|60] "" Vector__XXX
 SG_ DAS_sw073_freespaceRightFarZ m73 : 60|4@1+ (4,0) [0|60] "" Vector__XXX
 SG_ DAS_sw230_sensor1Blocked m230 : 16|1@1+ (1,0) [0|1] "" Vector__XXX
 SG_ DAS_sw230_sensor2Blocked m230 : 17|1@1+ (1,0) [0|1] "" Vector__XXX
 SG_ DAS_sw230_sensor3Blocked m230 : 18|1@1+ (1,0) [0|1] "" Vector__XXX
 SG_ DAS_sw230_sensor4Blocked m230 : 19|1@1+ (1,0) [0|1] "" Vector__XXX
 SG_ DAS_sw230_sensor5Blocked m230 : 20|1@1+ (1,0) [0|1] "" Vector__XXX
 SG_ DAS_sw230_sensor6Blocked m230 : 21|1@1+ (1,0) [0|1] "" Vector__XXX
 SG_ DAS_sw230_sensor7Blocked m230 : 22|1@1+ (1,0) [0|1] "" Vector__XXX
 SG_ DAS_sw230_sensor8Blocked m230 : 23|1@1+ (1,0) [0|1] "" Vector__XXX
 SG_ DAS_sw230_sensor9Blocked m230 : 24|1@1+ (1,0) [0|1] "" Vector__XXX
 SG_ DAS_sw230_sensor10Blocked m230 : 25|1@1+ (1,0) [0|1] "" Vector__XXX
 SG_ DAS_sw230_sensor11Blocked m230 : 26|1@1+ (1,0) [0|1] "" Vector__XXX
 SG_ DAS_sw230_sensor12Blocked m230 : 27|1@1+ (1,0) [0|1] "" Vector__XXX

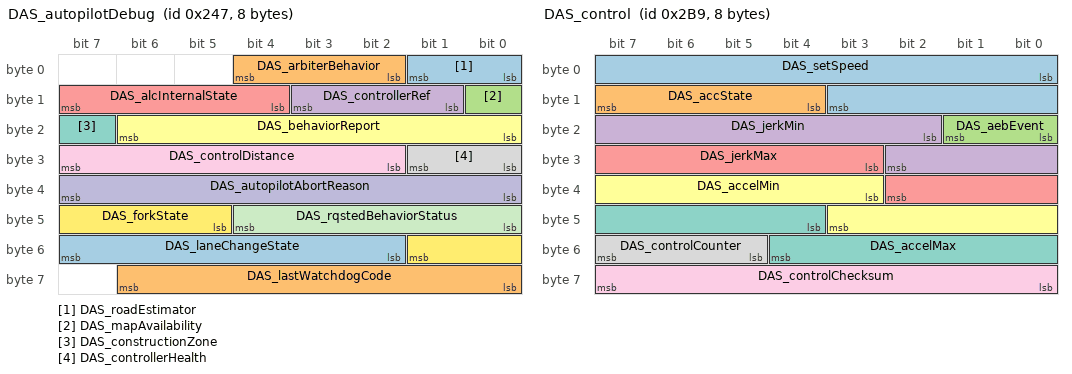
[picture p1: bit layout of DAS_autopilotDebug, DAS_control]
BO_ 583 DAS_autopilotDebug: 8 DAS
 SG_ DAS_roadEstimator : 0|2@1+ (1,0) [0|3] "" Vector__XXX
 SG_ DAS_arbiterBehavior : 2|3@1+ (1,0) [0|7] "" Vector__XXX
 SG_ DAS_mapAvailability : 8|1@1+ (1,0) [0|1] "" Vector__XXX
 SG_ DAS_controllerRef : 9|3@1+ (1,0) [0|7] "" Vector__XXX
 SG_ DAS_alcInternalState : 12|4@1+ (1,0) [0|15] "" Vector__XXX
 SG_ DAS_behaviorReport : 16|7@1+ (1,0) [0|127] "" Vector__XXX
 SG_ DAS_constructionZone : 23|1@1+ (1,0) [0|1] "" Vector__XXX
 SG_ DAS_controllerHealth : 24|2@1+ (1,0) [0|3] "" Vector__XXX
 SG_ DAS_controlDistance : 26|6@1+ (2,0) [0|126] "m" Vector__XXX
 SG_ DAS_autopilotAbortReason : 32|8@1+ (1,0) [0|255] "" Vector__XXX
 SG_ DAS_rqstedBehaviorStatus : 40|5@1+ (1,0) [0|31] "" Vector__XXX
 SG_ DAS_forkState : 45|5@1+ (1,0) [0|31] "" Vector__XXX
 SG_ DAS_laneChangeState : 50|6@1+ (1,0) [0|63] "" Vector__XXX
 SG_ DAS_lastWatchdogCode : 56|7@1+ (1,0) [0|127] "" Vector__XXX

BO_ 1001 DAS_bodyControls: 8 DAS
 SG_ DAS_headlightRequest : 0|2@1+ (1,0) [0|3] "" Vector__XXX
 SG_ DAS_hazardLightRequest : 2|2@1+ (1,0) [0|3] "" Vector__XXX
 SG_ DAS_wiperSpeed : 4|4@1+ (1,0) [0|15] "" Vector__XXX
 SG_ DAS_turnIndicatorRequest : 8|3@1+ (1,0) [0|7] "" Vector__XXX
 SG_ DAS_highLowBeamDecision : 11|2@1+ (1,0) [0|3] "" Vector__XXX
 SG_ DAS_heaterRequest : 13|2@1+ (1,0) [0|3] "" Vector__XXX
 SG_ DAS_highLowBeamOffReason : 15|3@1+ (1,0) [0|7] "" Vector__XXX
 SG_ DAS_forwardCamHeaterDutyCycle : 18|4@1+ (0.06666667,0) [0|1] "-" Vector__XXX
 SG_ DAS_dynamicBrakeLightRequest : 22|1@1+ (1,0) [0|1] "" Vector__XXX
 SG_ DAS_radarHeaterRequest : 23|1@1+ (1,0) [0|1] "" Vector__XXX
 SG_ DAS_ahlbOverride : 24|1@1+ (1,0) [0|1] "" Vector__XXX
 SG_ DAS_mirrorFoldRequest : 25|2@1+ (1,0) [0|3] "" Vector__XXX
 SG_ DAS_wiperWashRequest : 27|1@1+ (1,0) [0|1] "" Vector__XXX
 SG_ DAS_ulcConfirmationRequestActive : 28|1@1+ (1,0) [0|1] "" Vector__XXX
 SG_ DAS_overrideWiperSetting : 29|1@1+ (1,0) [0|1] "" Vector__XXX
 SG_ DAS_autoWiperState : 30|3@1+ (1,0) [0|7] "" Vector__XXX
 SG_ DAS_turnIndicatorRequestReason : 33|5@1+ (1,0) [0|31] "" Vector__XXX
 SG_ DAS_forwardRadarPowerRequest : 38|1@1+ (1,0) [0|1] "" Vector__XXX
 SG_ DAS_driverDomeLightRequest : 39|1@1+ (1,0) [0|1] "" Vector__XXX
 SG_ DAS_drivePowerStateRequest : 43|1@1+ (1,0) [0|1] "" Vector__XXX
 SG_ DAS_enableIcrDataCollection : 44|1@1+ (1,0) [0|1] "" Vector__XXX
 SG_ DAS_rPillarCamHeaterDutyCycle : 45|4@1+ (0.06666667,0) [0|1] "-" Vector__XXX
 SG_ DAS_adaptiveHighBeamIsFaulted : 49|1@1+ (1,0) [0|1] "" Vector__XXX
 SG_ DAS_restrictDoorReleaseLeft : 50|1@1+ (1,0) [0|1] "" Vector__XXX
 SG_ DAS_restrictDoorReleaseRight : 51|1@1+ (1,0) [0|1] "" Vector__XXX
 SG_ DAS_bodyControlsCounter : 52|4@1+ (1,0) [0|15] "" Vector__XXX
 SG_ DAS_bodyControlsChecksum : 56|8@1+ (1,0) [0|255] "" Vector__XXX

BO_ 1497 DAS_carLog: 8 DAS
 SG_ DAS_carLogMultiplexer M : 0|4@1+ (1,0) [0|15] "" Vector__XXX
 SG_ DAS_radarTarget5_dx m1 : 4|12@1+ (0.0625,0) [0|255.9375] "m" Vector__XXX
 SG_ DAS_radarTarget1_dx m1 : 24|12@1+ (0.0625,0) [0|255.9375] "m" Vector__XXX
 SG_ DAS_radarTarget1_VxRel m1 : 36|8@1+ (0.2,-25.6) [-25.6|25.4] "m/s" Vector__XXX
 SG_ DAS_mobileyeVehAebFlag m2 : 4|1@1+ (1,0) [0|1] "" Vector__XXX
 SG_ DAS_mobileyePedAebFlag m2 : 5|1@1+ (1,0) [0|1] "" Vector__XXX
 SG_ DAS_mobileyeIPSOapproved m2 : 6|1@1+ (1,0) [0|1] "" Vector__XXX
 SG_ DAS_fcmSteeringOverride m2 : 7|1@1+ (1,0) [0|1] "" Vector__XXX
 SG_ DAS_fcmCollisionStage3Checks m2 : 8|8@1+ (1,0) [0|255] "" Vector__XXX
 SG_ DAS_fcmThreatAssesmentMode m2 : 16|3@1+ (1,0) [0|7] "" Vector__XXX
 SG_ DAS_constructionArea m2 : 19|2@1+ (1,0) [0|3] "" Vector__XXX
 SG_ DAS_restrictionLowSpeedTraffic m2 : 21|1@1+ (1,0) [0|1] "" Vector__XXX
 SG_ DAS_associated_rad_object m2 : 22|2@1+ (1,0) [0|3] "" Vector__XXX
 SG_ DAS_LC_handsOnReason m2 : 24|6@1+ (1,0) [0|63] "" Vector__XXX
 SG_ DAS_ACC_camStatus m2 : 30|2@1+ (1,0) [0|3] "" Vector__XXX
 SG_ DAS_aeb_not_activating_reason m2 : 32|5@1+ (1,0) [0|31] "" Vector__XXX
 SG_ DAS_handsOnDetected m2 : 38|2@1+ (1,0) [0|3] "" Vector__XXX
 SG_ DAS_driveOnNavUnavailableReason m2 : 40|5@1+ (1,0) [0|31] "" Vector__XXX
 SG_ DAS_accUnavailableReason m2 : 46|7@1+ (1,0) [0|127] "" Vector__XXX
 SG_ DAS_pmmNotActivatingReason m2 : 53|5@1+ (1,0) [0|31] "" Vector__XXX
 SG_ DAS_desiredTarget_dx m3 : 16|8@1+ (0.5,0) [0|127] "m" Vector__XXX
 SG_ DAS_radarTarget2_dx m3 : 24|12@1+ (0.0625,0) [0|255.9375] "m" Vector__XXX
 SG_ DAS_radarTarget3_dx m3 : 36|12@1+ (0.0625,0) [0|255.9375] "m" Vector__XXX
 SG_ DAS_radarTarget4_dx m3 : 48|12@1+ (0.0625,0) [0|255.9375] "m" Vector__XXX
 SG_ DAS_closestInLaneTargetDx m4 : 4|12@1+ (0.0625,0) [0|255.9375] "m" Vector__XXX
 SG_ DAS_secondInLaneTargetDx m4 : 16|12@1+ (0.0625,0) [0|255.9375] "m" Vector__XXX
 SG_ DAS_closestLeftLaneTargetDx m4 : 28|12@1+ (0.0625,0) [0|255.9375] "m" Vector__XXX
 SG_ DAS_closestRightLaneTargetDx m4 : 40|12@1+ (0.0625,0) [0|255.9375] "m" Vector__XXX
 SG_ DAS_closestInLaneTargetVxRel m4 : 52|10@1+ (0.1,-51.1) [-51.1|51.2] "m/s" Vector__XXX

BO_ 697 DAS_control: 8 DAS
 SG_ DAS_setSpeed : 0|12@1+ (0.1,0) [0|409.4] "kph" Vector__XXX
 SG_ DAS_accState : 12|4@1+ (1,0) [0|15] "" Vector__XXX
 SG_ DAS_aebEvent : 16|2@1+ (1,0) [0|3] "" Vector__XXX
 SG_ DAS_jerkMin : 18|9@1+ (0.03,-15.232) [-15.232|0.098] "m/s^3" Vector__XXX
 SG_ DAS_jerkMax : 27|8@1+ (0.059,0) [0|15.045] "m/s^3" Vector__XXX
 SG_ DAS_accelMin : 35|9@1+ (0.04,-15) [-15|5.44] "m/s^2" Vector__XXX
 SG_ DAS_accelMax : 44|9@1+ (0.04,-15) [-15|5.44] "m/s^2" Vector__XXX
 SG_ DAS_controlCounter : 53|3@1+ (1,0) [0|7] "" Vector__XXX
 SG_ DAS_controlChecksum : 56|8@1+ (1,0) [0|255] "" Vector__XXX

BO_ 2041 DAS_gpsStatus: 8 DAS
 SG_ DAS_gpsStatusMultiplexer M : 0|4@1+ (1,0) [0|15] "" Vector__XXX
 SG_ DAS_gpsTransportModeState m0 : 4|1@1+ (1,0) [0|1] "" Vector__XXX
 SG_ DAS_gpsSatsInUseHardware m0 : 5|4@1+ (1,0) [0|15] "" Vector__XXX
 SG_ DAS_gpsWheeltickCounter m0 : 9|16@1+ (1,0) [0|65535] "" Vector__XXX
 SG_ DAS_gpsWheeltickPulsePeriod m0 : 25|32@1+ (1,0) [0|4294967295] "" Vector__XXX
 SG_ DAS_gpsRejectingSatData m0 : 57|1@1+ (1,0) [0|1] "" Vector__XXX
 SG_ DAS_gpsWheelsOffMotionDetected m0 : 58|1@1+ (1,0) [0|1] "" Vector__XXX
 SG_ DAS_gpsFixTypeHardware m0 : 59|3@1+ (1,0) [0|7] "" Vector__XXX
 SG_ DAS_gpsRawxEnabled m0 : 62|1@1+ (1,0) [0|1] "" Vector__XXX
 SG_ DAS_gpsRxmRawxMia m1 : 4|1@1+ (1,0) [0|1] "" Vector__XXX
 SG_ DAS_gpsRxmSfrbxMia m1 : 5|1@1+ (1,0) [0|1] "" Vector__XXX
 SG_ DAS_gpsEsfMeasMia m1 : 6|1@1+ (1,0) [0|1] "" Vector__XXX
 SG_ DAS_gpsEsfRawMia m1 : 7|1@1+ (1,0) [0|1] "" Vector__XXX
 SG_ DAS_gpsNavStatusMia m1 : 8|1@1+ (1,0) [0|1] "" Vector__XXX
 SG_ DAS_gpsSoftwareConfigured m1 : 9|1@1+ (1,0) [0|1] "" Vector__XXX
 SG_ DAS_gpsSoftwareUsed m1 : 10|1@1+ (1,0) [0|1] "" Vector__XXX
 SG_ DAS_gpsSoftwareFastStartReady m1 : 11|1@1+ (1,0) [0|1] "" Vector__XXX
 SG_ DAS_gpsSatsInUseSoftware m1 : 12|4@1+ (1,0) [0|15] "" Vector__XXX
 SG_ DAS_gpsFixTypeSoftware m1 : 16|3@1+ (1,0) [0|7] "" Vector__XXX
 SG_ DAS_gpsCWJammingInidcator m1 : 19|5@1+ (8,0) [0|248] "-" Vector__XXX
 SG_ DAS_gpsJammingState m1 : 24|2@1+ (1,0) [0|3] "" Vector__XXX
 SG_ DAS_gpsSpoofDetectorState m1 : 26|2@1+ (1,0) [0|3] "" Vector__XXX
 SG_ DAS_gpsInvalidMsgPercentage m1 : 28|4@1+ (6,0) [0|90] "%" Vector__XXX
 SG_ DAS_gnssConstellationsState m1 : 32|2@1+ (1,0) [0|3] "" Vector__XXX
 SG_ DAS_gpsReceiverNoiseLevel m1 : 34|6@1+ (8,0) [0|504] "-" Vector__XXX
 SG_ DAS_gpsAutomaticGainControl m1 : 40|8@1+ (32,0) [0|8160] "-" Vector__XXX
 SG_ DAS_gpsPreviousPositionDeltaHw m1 : 48|6@1+ (3,0) [0|189] "m" Vector__XXX
 SG_ DAS_gpsPreviousPositionDeltaSw m1 : 54|6@1+ (3,0) [0|189] "m" Vector__XXX
 SG_ DAS_gpsNmeaDispatchFailureCount m1 : 60|4@1+ (5,0) [0|75] "-" Vector__XXX
 SG_ DAS_gnssMaxInstantaneousCnorGps m2 : 4|6@1+ (1,0) [0|63] "" Vector__XXX
 SG_ DAS_gnssMaxInstantaneousCnorGal m2 : 10|6@1+ (1,0) [0|63] "" Vector__XXX
 SG_ DAS_gnssMaxInstantaneousCnorBds m2 : 16|6@1+ (1,0) [0|63] "" Vector__XXX
 SG_ DAS_gpsResetReason m2 : 22|4@1+ (1,0) [0|15] "" Vector__XXX
 SG_ DAS_gpsAccuracyHorizontal m2 : 26|6@1+ (1,0) [0|63] "m" Vector__XXX
 SG_ DAS_gpsAccuracyVertical m2 : 32|6@1+ (1,0) [0|63] "m" Vector__XXX
 SG_ DAS_gpsSolutionFallback m2 : 38|1@1+ (1,0) [0|1] "" Vector__XXX
 SG_ DAS_gpsToMcuSource m2 : 39|3@1+ (1,0) [0|7] "" Vector__XXX
 SG_ DAS_gpsSolutionSoc m2 : 42|2@1+ (1,0) [0|3] "" Vector__XXX
 SG_ DAS_gpsRedundancyActive m2 : 44|1@1+ (1,0) [0|1] "" Vector__XXX
 SG_ DAS_gpsFixTypeSoftwareSocB m2 : 45|3@1+ (1,0) [0|7] "" Vector__XXX
 SG_ DAS_gpsSatsInUseSoftwareSocB m2 : 48|4@1+ (1,0) [0|15] "" Vector__XXX
 SG_ DAS_gnssNumSatsGps m3 : 4|4@1+ (1,0) [0|15] "" Vector__XXX
 SG_ DAS_gnssNumSatsGal m3 : 8|4@1+ (1,0) [0|15] "" Vector__XXX
 SG_ DAS_gnssNumSatsBds m3 : 12|4@1+ (1,0) [0|15] "" Vector__XXX
 SG_ DAS_gnssAvgInstantaneousCnorGps m3 : 16|6@1+ (1,0) [0|63] "" Vector__XXX
 SG_ DAS_gnssAvgInstantaneousCnorGal m3 : 22|6@1+ (1,0) [0|63] "" Vector__XXX
 SG_ DAS_gnssAvgInstantaneousCnorBds m3 : 28|6@1+ (1,0) [0|63] "" Vector__XXX
 SG_ DAS_gnssAvgInstantCnorGpsSocB m3 : 34|6@1+ (1,0) [0|63] "" Vector__XXX
 SG_ DAS_gnssAvgInstantCnorBdsSocB m3 : 40|6@1+ (1,0) [0|63] "" Vector__XXX
 SG_ DAS_gnssAvgInstantaneousCnorGpsL m3 : 46|6@1+ (1,0) [0|63] "" Vector__XXX
 SG_ DAS_gnssAvgInstantaneousCnorGalL m3 : 52|6@1+ (1,0) [0|63] "" Vector__XXX
 SG_ DAS_gnssAvgInstantaneousCnorBdsL m3 : 58|6@1+ (1,0) [0|63] "" Vector__XXX

BO_ 1337 DAS_info: 8 DAS
 SG_ DAS_infoIndex M : 0|8@1+ (1,0) [0|255] "" Vector__XXX
 SG_ DAS_infoBuildType m10 : 8|8@1+ (1,0) [0|255] "" Vector__XXX
 SG_ DAS_infoBuildConfigID m10 : 16|16@1+ (1,0) [0|65535] "" Vector__XXX
 SG_ DAS_infoHardwareID m10 : 32|16@1+ (1,0) [0|65535] "" Vector__XXX
 SG_ DAS_infoComponentID m10 : 48|16@1+ (1,0) [0|65535] "" Vector__XXX
 SG_ DAS_infoPcbaID m11 : 16|8@1+ (1,0) [0|255] "" Vector__XXX
 SG_ DAS_infoAssemblyID m11 : 24|8@1+ (1,0) [0|255] "" Vector__XXX
 SG_ DAS_infoUsageID m11 : 32|16@1+ (1,0) [0|65535] "" Vector__XXX
 SG_ DAS_infoSubUsageID m11 : 48|16@1+ (1,0) [0|65535] "" Vector__XXX
 SG_ DAS_infoApplicationCRC m13 : 32|32@1+ (1,0) [0|4294967295] "" Vector__XXX
 SG_ DAS_infoAppGitHashBytes m17 : 8|56@1+ (1,0) [0|7.20575940379e+16] "" Vector__XXX
 SG_ DAS_infoBootGitHashBytes m18 : 8|56@1+ (1,0) [0|7.20575940379e+16] "" Vector__XXX

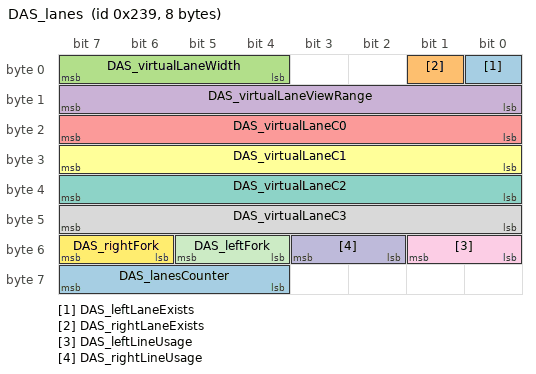
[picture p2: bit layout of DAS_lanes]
BO_ 569 DAS_lanes: 8 DAS
 SG_ DAS_leftLaneExists : 0|1@1+ (1,0) [0|1] "" Vector__XXX
 SG_ DAS_rightLaneExists : 1|1@1+ (1,0) [0|1] "" Vector__XXX
 SG_ DAS_virtualLaneWidth : 4|4@1+ (0.3125,2) [2|6.6875] "m" Vector__XXX
 SG_ DAS_virtualLaneViewRange : 8|8@1+ (1,0) [0|160] "m" Vector__XXX
 SG_ DAS_virtualLaneC0 : 16|8@1+ (0.035,-3.5) [-3.5|3.5] "m" Vector__XXX
 SG_ DAS_virtualLaneC1 : 24|8@1+ (0.0016,-0.2) [-0.2|0.2] "rad" Vector__XXX
 SG_ DAS_virtualLaneC2 : 32|8@1+ (2.0e-05,-0.0025) [-0.0025|0.0025] "m-1" Vector__XXX
 SG_ DAS_virtualLaneC3 : 40|8@1+ (2.4e-07,-3.0e-05) [-3.0e-05|3.0e-05] "m-2" Vector__XXX
 SG_ DAS_leftLineUsage : 48|2@1+ (1,0) [0|3] "" Vector__XXX
 SG_ DAS_rightLineUsage : 50|2@1+ (1,0) [0|3] "" Vector__XXX
 SG_ DAS_leftFork : 52|2@1+ (1,0) [0|3] "" Vector__XXX
 SG_ DAS_rightFork : 54|2@1+ (1,0) [0|3] "" Vector__XXX
 SG_ DAS_lanesCounter : 60|4@1+ (1,0) [0|15] "" Vector__XXX

BO_ 777 DAS_object: 8 DAS
 SG_ DAS_objectId M : 0|3@1+ (1,0) [0|7] "" Vector__XXX
 SG_ DAS_leadVehType m0 : 3|3@1+ (1,0) [0|7] "" Vector__XXX
 SG_ DAS_leadVehRelevantForControl m0 : 7|1@1+ (1,0) [0|1] "" Vector__XXX
 SG_ DAS_leadVehDx m0 : 8|8@1+ (0.5,0) [0|127] "m" Vector__XXX
 SG_ DAS_leadVehVxRel m0 : 16|4@1+ (4,-30) [-30|26] "m/s" Vector__XXX
 SG_ DAS_leadVehDy m0 : 20|7@1+ (0.35,-22.05) [-22.05|22.4] "m" Vector__XXX
 SG_ DAS_leadVehId m0 : 27|7@1+ (1,0) [0|127] "" Vector__XXX
 SG_ DAS_leadVeh2Type m0 : 34|3@1+ (1,0) [0|7] "" Vector__XXX
 SG_ DAS_leadVeh2RelevantForControl m0 : 38|1@1+ (1,0) [0|1] "" Vector__XXX
 SG_ DAS_leadVeh2Dx m0 : 39|8@1+ (0.5,0) [0|127] "m" Vector__XXX
 SG_ DAS_leadVeh2VxRel m0 : 47|4@1+ (4,-30) [-30|26] "m/s" Vector__XXX
 SG_ DAS_leadVeh2Dy m0 : 51|7@1+ (0.35,-22.05) [-22.05|22.4] "m" Vector__XXX
 SG_ DAS_leadVeh2Id m0 : 58|6@1+ (1,0) [0|63] "" Vector__XXX
 SG_ DAS_leftVehType m1 : 3|3@1+ (1,0) [0|7] "" Vector__XXX
 SG_ DAS_leftVehRelevantForControl m1 : 7|1@1+ (1,0) [0|1] "" Vector__XXX
 SG_ DAS_leftVehDx m1 : 8|8@1+ (0.5,0) [0|127] "m" Vector__XXX
 SG_ DAS_leftVehVxRel m1 : 16|4@1+ (4,-30) [-30|26] "m/s" Vector__XXX
 SG_ DAS_leftVehDy m1 : 20|7@1+ (0.35,-22.05) [-22.05|22.4] "m" Vector__XXX
 SG_ DAS_leftVehId m1 : 27|7@1+ (1,0) [0|127] "" Vector__XXX
 SG_ DAS_leftVeh2Type m1 : 34|3@1+ (1,0) [0|7] "" Vector__XXX
 SG_ DAS_leftVeh2RelevantForControl m1 : 38|1@1+ (1,0) [0|1] "" Vector__XXX
 SG_ DAS_leftVeh2Dx m1 : 39|8@1+ (0.5,0) [0|127] "m" Vector__XXX
 SG_ DAS_leftVeh2VxRel m1 : 47|4@1+ (4,-30) [-30|26] "m/s" Vector__XXX
 SG_ DAS_leftVeh2Dy m1 : 51|7@1+ (0.35,-22.05) [-22.05|22.4] "m" Vector__XXX
 SG_ DAS_leftVeh2Id m1 : 58|6@1+ (1,0) [0|63] "" Vector__XXX
 SG_ DAS_rightVehType m2 : 3|3@1+ (1,0) [0|7] "" Vector__XXX
 SG_ DAS_rightVehRelevantForControl m2 : 7|1@1+ (1,0) [0|1] "" Vector__XXX
 SG_ DAS_rightVehDx m2 : 8|8@1+ (0.5,0) [0|127] "m" Vector__XXX
 SG_ DAS_rightVehVxRel m2 : 16|4@1+ (4,-30) [-30|26] "m/s" Vector__XXX
 SG_ DAS_rightVehDy m2 : 20|7@1+ (0.35,-22.05) [-22.05|22.4] "m" Vector__XXX
 SG_ DAS_rightVehId m2 : 27|7@1+ (1,0) [0|127] "" Vector__XXX
 SG_ DAS_rightVeh2Type m2 : 34|3@1+ (1,0) [0|7] "" Vector__XXX
 SG_ DAS_rightVeh2RelevantForControl m2 : 38|1@1+ (1,0) [0|1] "" Vector__XXX
 SG_ DAS_rightVeh2Dx m2 : 39|8@1+ (0.5,0) [0|127] "m" Vector__XXX
 SG_ DAS_rightVeh2VxRel m2 : 47|4@1+ (4,-30) [-30|26] "m/s" Vector__XXX
 SG_ DAS_rightVeh2Dy m2 : 51|7@1+ (0.35,-22.05) [-22.05|22.4] "m" Vector__XXX
 SG_ DAS_rightVeh2Id m2 : 58|6@1+ (1,0) [0|63] "" Vector__XXX
 SG_ DAS_cutinVehType m3 : 3|3@1+ (1,0) [0|7] "" Vector__XXX
 SG_ DAS_cutinVehRelevantForControl m3 : 7|1@1+ (1,0) [0|1] "" Vector__XXX
 SG_ DAS_cutinVehDx m3 : 8|8@1+ (0.5,0) [0|127] "m" Vector__XXX
 SG_ DAS_cutinVehVxRel m3 : 16|4@1+ (4,-30) [-30|26] "m/s" Vector__XXX
 SG_ DAS_cutinVehDy m3 : 20|7@1+ (0.35,-22.05) [-22.05|22.4] "m" Vector__XXX
 SG_ DAS_cutinVehId m3 : 27|7@1+ (1,0) [0|127] "" Vector__XXX
 SG_ DAS_roadSignColor m4 : 3|3@1+ (1,0) [0|7] "" Vector__XXX
 SG_ DAS_roadSignId m4 : 6|8@1+ (1,0) [0|255] "" Vector__XXX
 SG_ DAS_roadSignStopLineDist m4 : 14|10@1+ (0.2,-20) [-20|184.4] "m" Vector__XXX
 SG_ DAS_roadSignControlActive m4 : 24|1@1+ (1,0) [0|1] "" Vector__XXX
 SG_ DAS_roadSignSource m4 : 25|2@1+ (1,0) [0|3] "" Vector__XXX
 SG_ DAS_roadSignArrow m4 : 27|3@1+ (1,0) [0|7] "" Vector__XXX
 SG_ DAS_roadSignOrientation m4 : 30|2@1+ (1,0) [0|3] "" Vector__XXX

CM_ BO_ 1294 "Charge port controller message: alert log";
CM_ SG_ 1294 CP_alertID "Charge port controller: alert ID";
CM_ SG_ 1294 CP_alertType "Charge port controller: alert type";
CM_ SG_ 1294 CP_a004_proximityV "Charge port controller: a004 proximity v";
CM_ SG_ 1294 CP_a004_cc1Voltage "Charge port controller: a004 cc1 voltage";
CM_ SG_ 1294 CP_a004_cc2Voltage "Charge port controller: a004 cc2 voltage";
CM_ SG_ 1294 CP_a005_cc1Voltage "Charge port controller: a005 cc1 voltage";
CM_ SG_ 1294 CP_a005_cc2Voltage "Charge port controller: a005 cc2 voltage";
CM_ SG_ 1294 CP_a005_gbdcState "Charge port controller: a005 gbdc state";
CM_ SG_ 1294 CP_a005_packCurrent "Charge port controller: a005 pack current";
CM_ SG_ 1294 CP_a005_evseCurrent "Charge port controller: a005 evse current";
CM_ SG_ 1294 CP_a005_superchargerConnected "Charge port controller: a005 supercharger connected";
CM_ SG_ 1294 CP_a005_latchEngaged "Charge port controller: a005 latch engaged";
CM_ SG_ 1294 CP_a006_BMS_FC_limits_MIA "Charge port controller: a006 BMS FC limits MIA";
CM_ SG_ 1294 CP_a006_BMS_chargeStatus_MIA "Charge port controller: a006 BMS charge status MIA";
CM_ SG_ 1294 CP_a006_BMS_dcChargeLimits_MIA "Charge port controller: a006 BMS dc charge limits MIA";
CM_ SG_ 1294 CP_a006_BMS_hvPackStatus_MIA "Charge port controller: a006 BMS hv pack status MIA";
CM_ SG_ 1294 CP_a006_BMS_kwhCounter_MIA "Charge port controller: a006 BMS kwh counter MIA";
CM_ SG_ 1294 CP_a006_BMS_socStatus_MIA "Charge port controller: a006 BMS soc status MIA";
CM_ SG_ 1294 CP_a008_data1 "Charge port controller: a008 data1";
CM_ SG_ 1294 CP_a008_data2 "Charge port controller: a008 data2";
CM_ SG_ 1294 CP_a008_FlashWarning "Charge port controller: a008 flash warning";
CM_ SG_ 1294 CP_a008_RAMconst_Warning "Charge port controller: a008 RA mconst warning";
CM_ SG_ 1294 CP_a008_RAMconst_Fault "Charge port controller: a008 RA mconst fault";
CM_ SG_ 1294 CP_a008_AllMemory_warnings "Charge port controller: a008 all memory warnings";
CM_ SG_ 1294 CP_a008_StackAlert "Charge port controller: a008 stack alert";
CM_ SG_ 1294 CP_a008_stackUsed "Charge port controller: a008 stack used";
CM_ SG_ 1294 CP_a009_cover1OpenCounts "Charge port controller: a009 cover1 open counts";
CM_ SG_ 1294 CP_a009_cover2OpenCounts "Charge port controller: a009 cover2 open counts";
CM_ SG_ 1294 CP_a009_cover1State "Charge port controller: a009 cover1 state";
CM_ SG_ 1294 CP_a009_cover2State "Charge port controller: a009 cover2 state";
CM_ SG_ 1294 CP_a010_periodValid "Charge port controller: a010 period valid";
CM_ SG_ 1294 CP_a010_widthValid "Charge port controller: a010 width valid";
CM_ SG_ 1294 CP_a010_voltageValid "Charge port controller: a010 voltage valid";
CM_ SG_ 1294 CP_a010_pilotHigh "Charge port controller: a010 pilot high";
CM_ SG_ 1294 CP_a010_pilotLow "Charge port controller: a010 pilot low";
CM_ SG_ 1294 CP_a010_evseAccept "Charge port controller: a010 evse accept";
CM_ SG_ 1294 CP_a010_pilotPWMdetected "Charge port controller: a010 pilot PW mdetected";
CM_ SG_ 1294 CP_a011_eepromErrorType "Charge port controller: a011 eeprom error type";
CM_ SG_ 1294 CP_a015_apsVoltageOV "Charge port controller: a015 aps voltage OV";
CM_ SG_ 1294 CP_a016_apsVoltageUV "Charge port controller: a016 aps voltage UV";
CM_ SG_ 1294 CP_a017_5V_VoltageOV "Charge port controller: a017 5 v voltage OV";
CM_ SG_ 1294 CP_a018_5V_VoltageUV "Charge port controller: a018 5 v voltage UV";
CM_ SG_ 1294 CP_a023_stopChargeReason "Charge port controller: a023 stop charge reason";
CM_ SG_ 1294 CP_a023_failureReason "Charge port controller: a023 failure reason";
CM_ SG_ 1294 CP_a023_chargeAttempts "Charge port controller: a023 charge attempts";
CM_ SG_ 1294 CP_a028_canEnable "Charge port controller: a028 can enable";
CM_ SG_ 1294 CP_a028_hardlineEnable "Charge port controller: a028 hardline enable";
CM_ SG_ 1294 CP_a029_CP_pilot "Charge port controller: a029 CP pilot";
CM_ SG_ 1294 CP_a029_CP_proximity "Charge port controller: a029 CP proximity";
CM_ SG_ 1294 CP_a029_CP_chargeDoorOpen "Charge port controller: a029 CP charge door open";
CM_ SG_ 1294 CP_a031_apsVoltage "Charge port controller: a031 aps voltage";
CM_ SG_ 1294 CP_a031_doorCountsFiltered "Charge port controller: a031 door counts filtered";
CM_ SG_ 1294 CP_a031_inductiveSensorFiltered "Charge port controller: a031 inductive sensor filtered";
CM_ SG_ 1294 CP_a031_hallSensorFiltered "Charge port controller: a031 hall sensor filtered";
CM_ SG_ 1294 CP_a032_apsVoltage "Charge port controller: a032 aps voltage";
CM_ SG_ 1294 CP_a032_doorCountsFiltered "Charge port controller: a032 door counts filtered";
CM_ SG_ 1294 CP_a032_inductiveSensorFiltered "Charge port controller: a032 inductive sensor filtered";
CM_ SG_ 1294 CP_a032_hallSensorFiltered "Charge port controller: a032 hall sensor filtered";
CM_ SG_ 1294 CP_a035_latchState "Charge port controller: a035 latch state";
CM_ SG_ 1294 CP_a035_stateLeverMovedFrom "Charge port controller: a035 state lever moved from";
CM_ SG_ 1294 CP_a035_latchOffset "Charge port controller: a035 latch offset";
CM_ SG_ 1294 CP_a035_inletID "Charge port controller: a035 inlet ID";
CM_ SG_ 1294 CP_a036_latchCountsFiltered "Charge port controller: a036 latch counts filtered";
CM_ SG_ 1294 CP_a036_latchState "Charge port controller: a036 latch state";
CM_ SG_ 1294 CP_a036_CHG_InsertEnable "Charge port controller: a036 CHG insert enable";
CM_ SG_ 1294 CP_a036_CP_latchEnableCmd "Charge port controller: a036 CP latch enable cmd";
CM_ SG_ 1294 CP_a036_CP_apsVoltage "Charge port controller: a036 CP aps voltage";
CM_ SG_ 1294 CP_a036_inletID "Charge port controller: a036 inlet ID";
CM_ SG_ 1294 CP_a037_latchCountsFiltered "Charge port controller: a037 latch counts filtered";
CM_ SG_ 1294 CP_a037_latchState "Charge port controller: a037 latch state";
CM_ SG_ 1294 CP_a037_CHG_InsertEnable "Charge port controller: a037 CHG insert enable";
CM_ SG_ 1294 CP_a037_CP_latchEnableCmd "Charge port controller: a037 CP latch enable cmd";
CM_ SG_ 1294 CP_a037_CP_apsVoltage "Charge port controller: a037 CP aps voltage";
CM_ SG_ 1294 CP_a037_inletID "Charge port controller: a037 inlet ID";
CM_ SG_ 1294 CP_a038_latchCountsFiltered "Charge port controller: a038 latch counts filtered";
CM_ SG_ 1294 CP_a038_latchState "Charge port controller: a038 latch state";
CM_ SG_ 1294 CP_a038_CHG_InsertEnable "Charge port controller: a038 CHG insert enable";
CM_ SG_ 1294 CP_a038_CP_latchEnableCmd "Charge port controller: a038 CP latch enable cmd";
CM_ SG_ 1294 CP_a038_CP_apsVoltage "Charge port controller: a038 CP aps voltage";
CM_ SG_ 1294 CP_a038_inletID "Charge port controller: a038 inlet ID";
CM_ SG_ 1294 CP_a041_doorCounts "Charge port controller: a041 door counts";
CM_ SG_ 1294 CP_a041_inductiveSensorFiltered "Charge port controller: a041 inductive sensor filtered";
CM_ SG_ 1294 CP_a041_hallSensorFiltered "Charge port controller: a041 hall sensor filtered";
CM_ SG_ 1294 CP_a042_doorCounts "Charge port controller: a042 door counts";
CM_ SG_ 1294 CP_a042_inductiveSensorFiltered "Charge port controller: a042 inductive sensor filtered";
CM_ SG_ 1294 CP_a042_hallSensorFiltered "Charge port controller: a042 hall sensor filtered";
CM_ SG_ 1294 CP_a043_driftFlag "Charge port controller: a043 drift flag";
CM_ SG_ 1294 CP_a043_wrongDirectionFlag "Charge port controller: a043 wrong direction flag";
CM_ SG_ 1294 CP_a043_outOfRangeFlag "Charge port controller: a043 out of range flag";
CM_ SG_ 1294 CP_a043_doorPotFiltered "Charge port controller: a043 door pot filtered";
CM_ SG_ 1294 CP_a043_doorVelocity "Charge port controller: a043 door velocity";
CM_ SG_ 1294 CP_a043_idleDoorPot "Charge port controller: a043 idle door pot";
CM_ SG_ 1294 CP_a044_HVP_cpControl_MIA "Charge port controller: a044 HVP cp control MIA";
CM_ SG_ 1294 CP_a045_VCSEC_authentication_MIA "Charge port controller: a045 VCSEC authentication MIA";
CM_ SG_ 1294 CP_a045_VCSEC_requests_MIA "Charge port controller: a045 VCSEC requests MIA";
CM_ SG_ 1294 CP_a046_FC_status_flag "Charge port controller: a046 FC status flag";
CM_ SG_ 1294 CP_a046_FC_limits_flag "Charge port controller: a046 FC limits flag";
CM_ SG_ 1294 CP_a046_FC_maxLimits_flag "Charge port controller: a046 FC max limits flag";
CM_ SG_ 1294 CP_a046_FC_statusHighPower_flag "Charge port controller: a046 FC status high power flag";
CM_ SG_ 1294 CP_a046_FC_limitsHighPower_flag "Charge port controller: a046 FC limits high power flag";
CM_ SG_ 1294 CP_a046_FC_maxLimitsHighPower "Charge port controller: a046 FC max limits high power";
CM_ SG_ 1294 CP_a046_CC_chgStatus_flag "Charge port controller: a046 CC chg status flag";
CM_ SG_ 1294 CP_a047_okToUseHighPower_MIA "Charge port controller: a047 ok to use high power MIA";
CM_ SG_ 1294 CP_a047_LVPowerState_MIA "Charge port controller: a047 LV power state MIA";
CM_ SG_ 1294 CP_a047_sensors_MIA "Charge port controller: a047 sensors MIA";
CM_ SG_ 1294 CP_a047_vehNm_MIA "Charge port controller: a047 veh nm MIA";
CM_ SG_ 1294 CP_a048_UI_chargeRequest_MIA "Charge port controller: a048 UI charge request MIA";
CM_ SG_ 1294 CP_a048_UI_range_MIA "Charge port controller: a048 UI range MIA";
CM_ SG_ 1294 CP_a048_UI_status_MIA "Charge port controller: a048 UI status MIA";
CM_ SG_ 1294 CP_a048_UI_vehicleModes_MIA "Charge port controller: a048 UI vehicle modes MIA";
CM_ SG_ 1294 CP_a048_UI_hvacRequest_MIA "Charge port controller: a048 UI hvac request MIA";
CM_ SG_ 1294 CP_a048_VEH_billing_MIA "Charge port controller: a048 VEH billing MIA";
CM_ SG_ 1294 CP_a049_proximity "Charge port controller: a049 proximity";
CM_ SG_ 1294 CP_a050_latch1NotConnected "Charge port controller: a050 latch1 not connected";
CM_ SG_ 1294 CP_a050_latch2NotConnected "Charge port controller: a050 latch2 not connected";
CM_ SG_ 1294 CP_a051_doorCountsFiltered "Charge port controller: a051 door counts filtered";
CM_ SG_ 1294 CP_a054_latchCountsFiltered "Charge port controller: a054 latch counts filtered";
CM_ SG_ 1294 CP_a054_latchState "Charge port controller: a054 latch state";
CM_ SG_ 1294 CP_a054_CHG_InsertEnable "Charge port controller: a054 CHG insert enable";
CM_ SG_ 1294 CP_a054_CP_latchEnableCmd "Charge port controller: a054 CP latch enable cmd";
CM_ SG_ 1294 CP_a054_CP_apsVoltage "Charge port controller: a054 CP aps voltage";
CM_ SG_ 1294 CP_a054_CP_proximity "Charge port controller: a054 CP proximity";
CM_ SG_ 1294 CP_a054_inletID "Charge port controller: a054 inlet ID";
CM_ SG_ 1294 CP_a056_latchState "Charge port controller: a056 latch state";
CM_ SG_ 1294 CP_a056_CHG_InsertEnable "Charge port controller: a056 CHG insert enable";
CM_ SG_ 1294 CP_a056_CP_latchEnableCmd "Charge port controller: a056 CP latch enable cmd";
CM_ SG_ 1294 CP_a056_CP_proximity "Charge port controller: a056 CP proximity";
CM_ SG_ 1294 CP_a056_packCurrent "Charge port controller: a056 pack current";
CM_ SG_ 1294 CP_a058_CP_pilot "Charge port controller: a058 CP pilot";
CM_ SG_ 1294 CP_a058_CC_pilot "Charge port controller: a058 CC pilot";
CM_ SG_ 1294 CP_a058_FC_status "Charge port controller: a058 FC status";
CM_ SG_ 1294 CP_a058_latchState "Charge port controller: a058 latch state";
CM_ SG_ 1294 CP_a058_CP_proximity "Charge port controller: a058 CP proximity";
CM_ SG_ 1294 CP_a058_acNumRetries "Charge port controller: a058 ac num retries";
CM_ SG_ 1294 CP_a058_acRetryTimeoutS "Charge port controller: a058 ac retry timeout s";
CM_ SG_ 1294 CP_a060_PCS_chgStatus_MIA "Charge port controller: a060 PCS chg status MIA";
CM_ SG_ 1294 CP_a060_PCS_chgLineStatus_MIA "Charge port controller: a060 PCS chg line status MIA";
CM_ SG_ 1294 CP_a061_controlState "Charge port controller: a061 control state";
CM_ SG_ 1294 CP_a061_lastControlState "Charge port controller: a061 last control state";
CM_ SG_ 1294 CP_a061_chipState "Charge port controller: a061 chip state";
CM_ SG_ 1294 CP_a061_timeMsInControlState "Charge port controller: a061 time ms in control state";
CM_ SG_ 1294 CP_a062_FC_status "Charge port controller: a062 FC status";
CM_ SG_ 1294 CP_a062_FC_type "Charge port controller: a062 FC type";
CM_ SG_ 1294 CP_a063_FC_status "Charge port controller: a063 FC status";
CM_ SG_ 1294 CP_a063_FC_type "Charge port controller: a063 FC type";
CM_ SG_ 1294 CP_a066_pilotHigh "Charge port controller: a066 pilot high";
CM_ SG_ 1294 CP_a066_pilotLow "Charge port controller: a066 pilot low";
CM_ SG_ 1294 CP_a066_proximity "Charge port controller: a066 proximity";
CM_ SG_ 1294 CP_a067_cc1Voltage "Charge port controller: a067 cc1 voltage";
CM_ SG_ 1294 CP_a067_cc2Voltage "Charge port controller: a067 cc2 voltage";
CM_ SG_ 1294 CP_a068_doorCountsFiltered "Charge port controller: a068 door counts filtered";
CM_ SG_ 1294 CP_a068_doorClosed "Charge port controller: a068 door closed";
CM_ SG_ 1294 CP_a068_inductiveSensorFiltered "Charge port controller: a068 inductive sensor filtered";
CM_ SG_ 1294 CP_a068_hallSensorFiltered "Charge port controller: a068 hall sensor filtered";
CM_ SG_ 1294 CP_a068_doorPresent "Charge port controller: a068 door present";
CM_ SG_ 1294 CP_a069_inductiveSensor_raw "Charge port controller: a069 inductive sensor raw";
CM_ SG_ 1294 CP_a069_inductiveErrorAmplitude "Charge port controller: a069 inductive error amplitude";
CM_ SG_ 1294 CP_a069_inductiveErrorWatchdog "Charge port controller: a069 inductive error watchdog";
CM_ SG_ 1294 CP_a069_inductiveErrorOverRange "Charge port controller: a069 inductive error over range";
CM_ SG_ 1294 CP_a069_inductiveErrorUnderRange "Charge port controller: a069 inductive error under range";
CM_ SG_ 1294 CP_a070_i2cIBCR "Charge port controller: a070 i2c IBCR";
CM_ SG_ 1294 CP_a070_i2cIBSR "Charge port controller: a070 i2c IBSR";
CM_ SG_ 1294 CP_a071_expectedMessage "Charge port controller: a071 expected message";
CM_ SG_ 1294 CP_a072_currentMessage "Charge port controller: a072 current message";
CM_ SG_ 1294 CP_a072_readyToChargeExpired "Charge port controller: a072 ready to charge expired";
CM_ SG_ 1294 CP_a072_commsSetupExpired "Charge port controller: a072 comms setup expired";
CM_ SG_ 1294 CP_a072_cableCheckExpired "Charge port controller: a072 cable check expired";
CM_ SG_ 1294 CP_a072_preChargeExpired "Charge port controller: a072 pre charge expired";
CM_ SG_ 1294 CP_a073_ccsManagerState "Charge port controller: a073 ccs manager state";
CM_ SG_ 1294 CP_a073_ccsDcState "Charge port controller: a073 ccs dc state";
CM_ SG_ 1294 CP_a073_ccsShutdownReason "Charge port controller: a073 ccs shutdown reason";
CM_ SG_ 1294 CP_a073_comboHandleNotPresent "Charge port controller: a073 combo handle not present";
CM_ SG_ 1294 CP_a073_commsFault "Charge port controller: a073 comms fault";
CM_ SG_ 1294 CP_a073_bmsShutdownRequested "Charge port controller: a073 bms shutdown requested";
CM_ SG_ 1294 CP_a073_evseShutdownRequested "Charge port controller: a073 evse shutdown requested";
CM_ SG_ 1294 CP_a073_cpInternalStopChgRequest "Charge port controller: a073 cp internal stop chg request";
CM_ SG_ 1294 CP_a073_v2gCommsEstablished "Charge port controller: a073 v2g comms established";
CM_ SG_ 1294 CP_a073_emergencyShutdown "Charge port controller: a073 emergency shutdown";
CM_ SG_ 1294 CP_a073_servicesNotSupported "Charge port controller: a073 services not supported";
CM_ SG_ 1294 CP_a073_ccs1AdapterBtnPress "Charge port controller: a073 ccs1 adapter btn press";
CM_ SG_ 1294 CP_a074_slacState "Charge port controller: a074 slac state";
CM_ SG_ 1294 CP_a074_slacErrorCode "Charge port controller: a074 slac error code";
CM_ SG_ 1294 CP_a074_sdpNoDiscoveryResponse "Charge port controller: a074 sdp no discovery response";
CM_ SG_ 1294 CP_a074_evseMeasuredAtten "Charge port controller: a074 evse measured atten";
CM_ SG_ 1294 CP_a075_evccState "Charge port controller: a075 evcc state";
CM_ SG_ 1294 CP_a075_currentMessage "Charge port controller: a075 current message";
CM_ SG_ 1294 CP_a075_exiUnpackFailed "Charge port controller: a075 exi unpack failed";
CM_ SG_ 1294 CP_a075_failedResponseCode "Charge port controller: a075 failed response code";
CM_ SG_ 1294 CP_a075_evseMeasuredAtten "Charge port controller: a075 evse measured atten";
CM_ SG_ 1294 CP_a075_evseEmergencyChgEnd "Charge port controller: a075 evse emergency chg end";
CM_ SG_ 1294 CP_a075_initFailureType "Charge port controller: a075 init failure type";
CM_ SG_ 1294 CP_a077_mac1Invalid "Charge port controller: a077 mac1 invalid";
CM_ SG_ 1294 CP_a077_mac2Invalid "Charge port controller: a077 mac2 invalid";
CM_ SG_ 1294 CP_a077_macsMatching "Charge port controller: a077 macs matching";
CM_ SG_ 1294 CP_a078_VC_tempAmbientFiltered "Charge port controller: a078 VC temp ambient filtered";
CM_ SG_ 1294 CP_a078_pinTemperature1 "Charge port controller: a078 pin temperature1";
CM_ SG_ 1294 CP_a078_pinTemperature2 "Charge port controller: a078 pin temperature2";
CM_ SG_ 1294 CP_a078_pinTemperature3 "Charge port controller: a078 pin temperature3";
CM_ SG_ 1294 CP_a079_VC_tempAmbientFiltered "Charge port controller: a079 VC temp ambient filtered";
CM_ SG_ 1294 CP_a079_pinTemperature1 "Charge port controller: a079 pin temperature1";
CM_ SG_ 1294 CP_a079_pinTemperature2 "Charge port controller: a079 pin temperature2";
CM_ SG_ 1294 CP_a079_pinTemperature3 "Charge port controller: a079 pin temperature3";
CM_ SG_ 1294 CP_a084_proximityV "Charge port controller: a084 proximity v";
CM_ SG_ 1294 CP_a084_cc1Voltage "Charge port controller: a084 cc1 voltage";
CM_ SG_ 1294 CP_a084_cc2Voltage "Charge port controller: a084 cc2 voltage";
CM_ SG_ 1294 CP_a085_absoluteTempFault "Charge port controller: a085 absolute temp fault";
CM_ SG_ 1294 CP_a085_dcPinTemp "Charge port controller: a085 dc pin temp";
CM_ SG_ 1294 CP_a086_dcPinTemp "Charge port controller: a086 dc pin temp";
CM_ SG_ 1294 CP_a089_gtwPlcSupportType "Charge port controller: a089 gtw plc support type";
CM_ SG_ 1294 CP_a089_plcModemPopulated "Charge port controller: a089 plc modem populated";
CM_ SG_ 1294 CP_a090_evseIsoStatus "Charge port controller: a090 evse iso status";
CM_ SG_ 1294 CP_a090_ccsDcState "Charge port controller: a090 ccs dc state";
CM_ SG_ 1294 CP_a091_fcType "Charge port controller: a091 fc type";
CM_ SG_ 1294 CP_a093_appLoadingNumRetries "Charge port controller: a093 app loading num retries";
CM_ SG_ 1294 CP_a093_interruptCauseRegError "Charge port controller: a093 interrupt cause reg error";
CM_ SG_ 1294 CP_a094_faultResetCount "Charge port controller: a094 fault reset count";
CM_ SG_ 1294 CP_a095_packCurrent "Charge port controller: a095 pack current";
CM_ SG_ 1294 CP_a095_dcOutputCurrent "Charge port controller: a095 dc output current";
CM_ SG_ 1294 CP_a095_ambientTemp "Charge port controller: a095 ambient temp";
CM_ SG_ 1294 CP_a095_fcType "Charge port controller: a095 fc type";
CM_ SG_ 1294 CP_a095_fcBrand "Charge port controller: a095 fc brand";
CM_ SG_ 1294 CP_a099_proximity "Charge port controller: a099 proximity";
CM_ SG_ 1294 CP_a099_pilot "Charge port controller: a099 pilot";
CM_ SG_ 1294 CP_a103_proximityV "Charge port controller: a103 proximity v";
CM_ SG_ 1294 CP_a109_thermistorId "Charge port controller: a109 thermistor id";
CM_ SG_ 1294 CP_a109_thermistorTemp "Charge port controller: a109 thermistor temp";
CM_ SG_ 1294 CP_a110_thermistorId "Charge port controller: a110 thermistor id";
CM_ SG_ 1294 CP_a110_thermistorTemp "Charge port controller: a110 thermistor temp";
CM_ SG_ 1294 CP_a110_thermalVelocity "Charge port controller: a110 thermal velocity";
CM_ SG_ 1294 CP_a111_heaterTemperature "Charge port controller: a111 heater temperature";
CM_ SG_ 1294 CP_a111_VC_tempAmbientFiltered "Charge port controller: a111 VC temp ambient filtered";
CM_ SG_ 1294 CP_a112_heaterTemperature "Charge port controller: a112 heater temperature";
CM_ SG_ 1294 CP_a113_heaterTemperature "Charge port controller: a113 heater temperature";
CM_ SG_ 1294 CP_a113_heaterCurrent "Charge port controller: a113 heater current";
CM_ SG_ 1294 CP_a116_hvCoverDetected "Charge port controller: a116 hv cover detected";
CM_ SG_ 1294 CP_a116_heaterDetected "Charge port controller: a116 heater detected";
CM_ SG_ 1294 CP_a116_temperatureSensorMismatc "Charge port controller: a116 temperature sensor mismatch";
CM_ SG_ 1294 CP_a116_thermistorsOpenCircuit "Charge port controller: a116 thermistors open circuit";
CM_ SG_ 1294 CP_a117_heaterTemperature "Charge port controller: a117 heater temperature";
CM_ SG_ 1294 CP_a117_averageError "Charge port controller: a117 average error";
CM_ SG_ 1294 CP_a120_oldProximtyV "Charge port controller: a120 old proximty v";
CM_ SG_ 1294 CP_a120_newProximtyV "Charge port controller: a120 new proximty v";
CM_ SG_ 1294 CP_a120_chargeVoltage "Charge port controller: a120 charge voltage";
CM_ SG_ 1294 CP_a120_chargeCurrent "Charge port controller: a120 charge current";
CM_ SG_ 1294 CP_a120_dcPinTemp "Charge port controller: a120 dc pin temp";
CM_ SG_ 1294 CP_a121_CP_status_MIA "Charge port controller: a121 CP status MIA";
CM_ SG_ 1294 CP_a124_ivledState "Charge port controller: a124 ivled state";
CM_ SG_ 1294 CP_a124_ivledVoltage "Charge port controller: a124 ivled voltage";
CM_ SG_ 1294 CP_a125_okToUseHighPower "Charge port controller: a125 ok to use high power";
CM_ SG_ 1294 CP_a127_HVLINK_cpControl_MIA "Charge port controller: a127 HVLINK cp control MIA";
CM_ SG_ 1294 CP_a129_bldcDriverState "Charge port controller: a129 bldc driver state";
CM_ SG_ 1294 CP_a130_retryCount "Charge port controller: a130 retry count";
CM_ SG_ 1294 CP_a131_chargeProtocol "Charge port controller: a131 charge protocol";
CM_ SG_ 1294 CP_a135_sdpErr "Charge port controller: a135 sdp err";
CM_ SG_ 1294 CP_a135_pilotState "Charge port controller: a135 pilot state";
CM_ SG_ 1294 CP_a135_evseMeasuredAtten "Charge port controller: a135 evse measured atten";
CM_ SG_ 1294 CP_a138_FC_type "Charge port controller: a138 FC type";
CM_ SG_ 1294 CP_a138_latchState "Charge port controller: a138 latch state";
CM_ SG_ 1294 CP_a138_CP_proximity "Charge port controller: a138 CP proximity";
CM_ SG_ 1294 CP_a139_latchState "Charge port controller: a139 latch state";
CM_ SG_ 1294 CP_a139_CP_proximity "Charge port controller: a139 CP proximity";
CM_ SG_ 1294 CP_a140_latchState "Charge port controller: a140 latch state";
CM_ SG_ 1294 CP_a140_CP_proximity "Charge port controller: a140 CP proximity";
CM_ SG_ 1294 CP_a141_latchState "Charge port controller: a141 latch state";
CM_ SG_ 1294 CP_a141_CP_proximity "Charge port controller: a141 CP proximity";
CM_ SG_ 1294 CP_a142_cc1Voltage "Charge port controller: a142 cc1 voltage";
CM_ SG_ 1294 CP_a142_cc2Voltage "Charge port controller: a142 cc2 voltage";
CM_ SG_ 1294 CP_a143_versionDetected "Charge port controller: a143 version detected";
CM_ SG_ 1294 CP_a146_v2gMessage "Charge port controller: a146 v2g message";
CM_ SG_ 1294 CP_a151_pilotHighMin "Charge port controller: a151 pilot high min";
CM_ SG_ 1294 CP_a151_pilotHighMax "Charge port controller: a151 pilot high max";
CM_ SG_ 1294 CP_a151_pilotLowMin "Charge port controller: a151 pilot low min";
CM_ SG_ 1294 CP_a151_pilotLowMax "Charge port controller: a151 pilot low max";
CM_ SG_ 1294 CP_a152_swcanHighMismatchCount "Charge port controller: a152 swcan high mismatch count";
CM_ SG_ 1294 CP_a152_swcanLowMismatchCount "Charge port controller: a152 swcan low mismatch count";
CM_ SG_ 1294 CP_a152_maxPilotSwcanHigh "Charge port controller: a152 max pilot swcan high";
CM_ SG_ 1294 CP_a152_minPilotSwcanHigh "Charge port controller: a152 min pilot swcan high";
CM_ SG_ 1294 CP_a152_maxPilotSwcanLow "Charge port controller: a152 max pilot swcan low";
CM_ SG_ 1294 CP_a152_minPilotSwcanLow "Charge port controller: a152 min pilot swcan low";
CM_ SG_ 1294 CP_a153_acPinTempVelocity "Charge port controller: a153 ac pin temp velocity";
CM_ SG_ 1294 CP_a153_acPinTemp1 "Charge port controller: a153 ac pin temp1";
CM_ SG_ 1294 CP_a153_acPinTemp2 "Charge port controller: a153 ac pin temp2";
CM_ SG_ 1294 CP_a153_ambientTemp "Charge port controller: a153 ambient temp";
CM_ SG_ 1294 CP_a153_pcsLineChargeCurrent "Charge port controller: a153 pcs line charge current";
CM_ SG_ 1294 CP_a154_acPinTempVelocity "Charge port controller: a154 ac pin temp velocity";
CM_ SG_ 1294 CP_a154_acPinTemp1 "Charge port controller: a154 ac pin temp1";
CM_ SG_ 1294 CP_a154_acPinTemp2 "Charge port controller: a154 ac pin temp2";
CM_ SG_ 1294 CP_a154_ambientTemp "Charge port controller: a154 ambient temp";
CM_ SG_ 1294 CP_a154_pcsLineChargeCurrent "Charge port controller: a154 pcs line charge current";
CM_ SG_ 1294 CP_a155_hallSensorVoltage "Charge port controller: a155 hall sensor voltage";
CM_ SG_ 1294 CP_a161_pilotHighMin "Charge port controller: a161 pilot high min";
CM_ SG_ 1294 CP_a161_pilotHighMax "Charge port controller: a161 pilot high max";
CM_ SG_ 1294 CP_a161_pilotLowMin "Charge port controller: a161 pilot low min";
CM_ SG_ 1294 CP_a161_pilotLowMax "Charge port controller: a161 pilot low max";
CM_ SG_ 1294 CP_a162_swcanHighMismatchCount "Charge port controller: a162 swcan high mismatch count";
CM_ SG_ 1294 CP_a162_swcanLowMismatchCount "Charge port controller: a162 swcan low mismatch count";
CM_ SG_ 1294 CP_a162_maxPilotSwcanHigh "Charge port controller: a162 max pilot swcan high";
CM_ SG_ 1294 CP_a162_minPilotSwcanHigh "Charge port controller: a162 min pilot swcan high";
CM_ SG_ 1294 CP_a162_maxPilotSwcanLow "Charge port controller: a162 max pilot swcan low";
CM_ SG_ 1294 CP_a162_minPilotSwcanLow "Charge port controller: a162 min pilot swcan low";
CM_ SG_ 1294 CP_a163_cover1OpenCounts "Charge port controller: a163 cover1 open counts";
CM_ SG_ 1294 CP_a163_cover2OpenCounts "Charge port controller: a163 cover2 open counts";
CM_ SG_ 1294 CP_a163_cover1State "Charge port controller: a163 cover1 state";
CM_ SG_ 1294 CP_a163_cover2State "Charge port controller: a163 cover2 state";
CM_ SG_ 1294 CP_a164_VC_tempAmbientFiltered "Charge port controller: a164 VC temp ambient filtered";
CM_ SG_ 1294 CP_a164_minInternalPinTemp "Charge port controller: a164 min internal pin temp";
CM_ SG_ 1294 CP_a173_cover1OpenCounts "Charge port controller: a173 cover1 open counts";
CM_ SG_ 1294 CP_a173_cover2OpenCounts "Charge port controller: a173 cover2 open counts";
CM_ SG_ 1294 CP_a173_cover1State "Charge port controller: a173 cover1 state";
CM_ SG_ 1294 CP_a173_cover2State "Charge port controller: a173 cover2 state";
CM_ BO_ 798 "Charge port controller message: alert matrix";
CM_ SG_ 798 CP_matrixIndex "Charge port controller: matrix index";
CM_ SG_ 798 CP_a001_canRx "Charge port controller: a001 can rx";
CM_ SG_ 798 CP_a002_canTx "Charge port controller: a002 can tx";
CM_ SG_ 798 CP_a003_canError "Charge port controller: a003 can error";
CM_ SG_ 798 CP_a004_proximityRationality "Charge port controller: a004 proximity rationality";
CM_ SG_ 798 CP_a005_gbdcLiveDisconnect "Charge port controller: a005 gbdc live disconnect";
CM_ SG_ 798 CP_a006_lostCommsBMS "Charge port controller: a006 lost comms BMS";
CM_ SG_ 798 CP_a007_watchdog "Charge port controller: a007 watchdog";
CM_ SG_ 798 CP_a008_memoryError "Charge port controller: a008 memory error";
CM_ SG_ 798 CP_a009_coverOpenAllChgBlocked "Charge port controller: a009 cover open all chg blocked";
CM_ SG_ 798 CP_a010_pilotRationality "Charge port controller: a010 pilot rationality";
CM_ SG_ 798 CP_a011_eeprom "Charge port controller: a011 eeprom";
CM_ SG_ 798 CP_a012_ledDriver "Charge port controller: a012 led driver";
CM_ SG_ 798 CP_a013_lostCommsGTW "Charge port controller: a013 lost comms GTW";
CM_ SG_ 798 CP_a014_lostCommsCHG "Charge port controller: a014 lost comms CHG";
CM_ SG_ 798 CP_a015_apsVov "Charge port controller: a015 aps vov";
CM_ SG_ 798 CP_a016_apsVuv "Charge port controller: a016 aps vuv";
CM_ SG_ 798 CP_a017_fiveVov "Charge port controller: a017 five vov";
CM_ SG_ 798 CP_a018_fiveVuv "Charge port controller: a018 five vuv";
CM_ SG_ 798 CP_a019_threeVov "Charge port controller: a019 three vov";
CM_ SG_ 798 CP_a020_threeVuv "Charge port controller: a020 three vuv";
CM_ SG_ 798 CP_a021_zeroVov "Charge port controller: a021 zero vov";
CM_ SG_ 798 CP_a022_zeroVuv "Charge port controller: a022 zero vuv";
CM_ SG_ 798 CP_a023_gbdcSessionFailed "Charge port controller: a023 gbdc session failed";
CM_ SG_ 798 CP_a024_ledsUC "Charge port controller: a024 leds UC";
CM_ SG_ 798 CP_a025_ledsOC "Charge port controller: a025 leds OC";
CM_ SG_ 798 CP_a026_networkManagement "Charge port controller: a026 network management";
CM_ SG_ 798 CP_a027_doorSensorOutOfSpec "Charge port controller: a027 door sensor out of spec";
CM_ SG_ 798 CP_a028_insertEnableMismatch "Charge port controller: a028 insert enable mismatch";
CM_ SG_ 798 CP_a029_doorClosedProxPilot "Charge port controller: a029 door closed prox pilot";
CM_ SG_ 798 CP_a030_busOff "Charge port controller: a030 bus off";
CM_ SG_ 798 CP_a031_doorClosedCommandedOpen "Charge port controller: a031 door closed commanded open";
CM_ SG_ 798 CP_a032_doorOpenExpectedClosed "Charge port controller: a032 door open expected closed";
CM_ SG_ 798 CP_a033_spiOpen "Charge port controller: a033 spi open";
CM_ SG_ 798 CP_a034_calibrationIncomplete "Charge port controller: a034 calibration incomplete";
CM_ SG_ 798 CP_a035_latchMovement_1 "Charge port controller: a035 latch movement 1";
CM_ SG_ 798 CP_a036_latchNotDisengaged "Charge port controller: a036 latch not disengaged";
CM_ SG_ 798 CP_a037_latchNotEngaged "Charge port controller: a037 latch not engaged";
CM_ SG_ 798 CP_a038_latchNotBlocking "Charge port controller: a038 latch not blocking";
CM_ SG_ 798 CP_a039_latchMovement_2 "Charge port controller: a039 latch movement 2";
CM_ SG_ 798 CP_a040_doNotUse "Charge port controller: a040 do not use";
CM_ SG_ 798 CP_a041_doorSensorUnplugged "Charge port controller: a041 door sensor unplugged";
CM_ SG_ 798 CP_a042_doorAssemblyBroken "Charge port controller: a042 door assembly broken";
CM_ SG_ 798 CP_a043_doorPotIrrational "Charge port controller: a043 door pot irrational";
CM_ SG_ 798 CP_a044_lostCommsHVP "Charge port controller: a044 lost comms HVP";
CM_ SG_ 798 CP_a045_lostCommsVCSEC "Charge port controller: a045 lost comms VCSEC";
CM_ SG_ 798 CP_a046_lostCommsEVSE "Charge port controller: a046 lost comms EVSE";
CM_ SG_ 798 CP_a047_lostCommsVCFRONT "Charge port controller: a047 lost comms VCFRONT";
CM_ SG_ 798 CP_a048_lostCommsUI "Charge port controller: a048 lost comms UI";
CM_ SG_ 798 CP_a049_multipleCablesDetected "Charge port controller: a049 multiple cables detected";
CM_ SG_ 798 CP_a050_latchNotConnected "Charge port controller: a050 latch not connected";
CM_ SG_ 798 CP_a051_doorInductiveSensorMIA "Charge port controller: a051 door inductive sensor MIA";
CM_ SG_ 798 CP_a052_chademoNotSupported "Charge port controller: a052 chademo not supported";
CM_ SG_ 798 CP_a053_proxLatchedNoPilot "Charge port controller: a053 prox latched no pilot";
CM_ SG_ 798 CP_a054_cableNotSecured "Charge port controller: a054 cable not secured";
CM_ SG_ 798 CP_a055_chargeStoppedNoPilot "Charge port controller: a055 charge stopped no pilot";
CM_ SG_ 798 CP_a056_proxDisconnected "Charge port controller: a056 prox disconnected";
CM_ SG_ 798 CP_a057_ccs1AdapterBtnPress "Charge port controller: a057 ccs1 adapter btn press";
CM_ SG_ 798 CP_a058_acChargeRetryPending "Charge port controller: a058 ac charge retry pending";
CM_ SG_ 798 CP_a059_swcanError "Charge port controller: a059 swcan error";
CM_ SG_ 798 CP_a060_lostCommsPCS "Charge port controller: a060 lost comms PCS";
CM_ SG_ 798 CP_a061_uhfReceiverMIA "Charge port controller: a061 uhf receiver MIA";
CM_ SG_ 798 CP_a062_scOutOfService "Charge port controller: a062 sc out of service";
CM_ SG_ 798 CP_a063_scUpdateInProgress "Charge port controller: a063 sc update in progress";
CM_ SG_ 798 CP_a064_superchargingBlocked "Charge port controller: a064 supercharging blocked";
CM_ SG_ 798 CP_a065_selfTestFailed "Charge port controller: a065 self test failed";
CM_ SG_ 798 CP_a066_proxLatchedIdlePilot "Charge port controller: a066 prox latched idle pilot";
CM_ SG_ 798 CP_a067_gbdcConnFault "Charge port controller: a067 gbdc conn fault";
CM_ SG_ 798 CP_a068_doorSensorMismatch "Charge port controller: a068 door sensor mismatch";
CM_ SG_ 798 CP_a069_doorInductiveSensorError "Charge port controller: a069 door inductive sensor error";
CM_ SG_ 798 CP_a070_doorInductiveSensorReset "Charge port controller: a070 door inductive sensor reset";
CM_ SG_ 798 CP_a071_exiDecodeFailure "Charge port controller: a071 exi decode failure";
CM_ SG_ 798 CP_a072_v2gEvccTimeout "Charge port controller: a072 v2g evcc timeout";
CM_ SG_ 798 CP_a073_iecComboShutdown "Charge port controller: a073 iec combo shutdown";
CM_ SG_ 798 CP_a074_failedToEstablishV2gComm "Charge port controller: a074 failed to establish v2g comm";
CM_ SG_ 798 CP_a075_v2gCommsFailure "Charge port controller: a075 v2g comms failure";
CM_ SG_ 798 CP_a076_LDC1612errorWatchdog "Charge port controller: a076 ldc1612error watchdog";
CM_ SG_ 798 CP_a077_invalidMacAddress "Charge port controller: a077 invalid mac address";
CM_ SG_ 798 CP_a078_latchNotDisengagedCold "Charge port controller: a078 latch not disengaged cold";
CM_ SG_ 798 CP_a079_cableNotSecuredCold "Charge port controller: a079 cable not secured cold";
CM_ SG_ 798 CP_a080_taskStackOverflow "Charge port controller: a080 task stack overflow";
CM_ SG_ 798 CP_a081_swException "Charge port controller: a081 sw exception";
CM_ SG_ 798 CP_a082_powerOnReset "Charge port controller: a082 power on reset";
CM_ SG_ 798 CP_a083_watchdogTraceData "Charge port controller: a083 watchdog trace data";
CM_ SG_ 798 CP_a084_proxPeDisconnected_gb "Charge port controller: a084 prox pe disconnected gb";
CM_ SG_ 798 CP_a085_dcPinTempFaulted "Charge port controller: a085 dc pin temp faulted";
CM_ SG_ 798 CP_a086_dcPinTempIrrational "Charge port controller: a086 dc pin temp irrational";
CM_ SG_ 798 CP_a087_dcTempModelFault "Charge port controller: a087 dc temp model fault";
CM_ SG_ 798 CP_a088_dcTempModelDeviation "Charge port controller: a088 dc temp model deviation";
CM_ SG_ 798 CP_a089_plcConfigMismatch "Charge port controller: a089 plc config mismatch";
CM_ SG_ 798 CP_a090_ccsEvseLowIso "Charge port controller: a090 ccs evse low iso";
CM_ SG_ 798 CP_a091_wrongSuperchargerHandle "Charge port controller: a091 wrong supercharger handle";
CM_ SG_ 798 CP_a092_modemAppLoadFailed "Charge port controller: a092 modem app load failed";
CM_ SG_ 798 CP_a093_modemLoadedWithReset "Charge port controller: a093 modem loaded with reset";
CM_ SG_ 798 CP_a094_inductiveResetSuccessful "Charge port controller: a094 inductive reset successful";
CM_ SG_ 798 CP_a095_thermalDcLimitActive "Charge port controller: a095 thermal dc limit active";
CM_ SG_ 798 CP_a096_pilotWake "Charge port controller: a096 pilot wake";
CM_ SG_ 798 CP_a097_modeTransitionFailure "Charge port controller: a097 mode transition failure";
CM_ SG_ 798 CP_a098_proximityWake "Charge port controller: a098 proximity wake";
CM_ SG_ 798 CP_a099_cableStateUnknown "Charge port controller: a099 cable state unknown";
CM_ SG_ 798 CP_a100_inletHarnessIdIrrational "Charge port controller: a100 inlet harness id irrational";
CM_ SG_ 798 CP_a101_wcFoldbackActive "Charge port controller: a101 wc foldback active";
CM_ SG_ 798 CP_a102_wcOvertempFault "Charge port controller: a102 wc overtemp fault";
CM_ SG_ 798 CP_a103_proximityPeDisconnected "Charge port controller: a103 proximity pe disconnected";
CM_ SG_ 798 CP_a104_uhfResetSuccessful "Charge port controller: a104 uhf reset successful";
CM_ SG_ 798 CP_a105_hwUnableToSleep "Charge port controller: a105 hw unable to sleep";
CM_ SG_ 798 CP_a106_uhfReceiverReset "Charge port controller: a106 uhf receiver reset";
CM_ SG_ 798 CP_a107_chademoFoldbackActive "Charge port controller: a107 chademo foldback active";
CM_ SG_ 798 CP_a108_chademoOvertempFault "Charge port controller: a108 chademo overtemp fault";
CM_ SG_ 798 CP_a109_thermistorIrrational "Charge port controller: a109 thermistor irrational";
CM_ SG_ 798 CP_a110_thermalVelocityHigh "Charge port controller: a110 thermal velocity high";
CM_ SG_ 798 CP_a111_inletHeaterUnableToHeat "Charge port controller: a111 inlet heater unable to heat";
CM_ SG_ 798 CP_a112_inletHeaterIrrationalTem "Charge port controller: a112 inlet heater irrational temperature";
CM_ SG_ 798 CP_a113_inletHeaterShortCircuit "Charge port controller: a113 inlet heater short circuit";
CM_ SG_ 798 CP_a114_ccsEvseFailed "Charge port controller: a114 ccs evse failed";
CM_ SG_ 798 CP_a115_unexpectedTcan1145State "Charge port controller: a115 unexpected tcan1145 state";
CM_ SG_ 798 CP_a116_misconfigurationDetected "Charge port controller: a116 misconfiguration detected";
CM_ SG_ 798 CP_a117_inletHeaterUnableToRegul "Charge port controller: a117 inlet heater unable to regulate";
CM_ SG_ 798 CP_a118_iecComboLockUp "Charge port controller: a118 iec combo lock up";
CM_ SG_ 798 CP_a119_plcTransmitFailure "Charge port controller: a119 plc transmit failure";
CM_ SG_ 798 CP_a120_comboAdapterFoldback "Charge port controller: a120 combo adapter foldback";
CM_ SG_ 798 CP_a121_PLCRLY_lostCommsCP "Charge port controller: a121 PLCRLY lost comms CP";
CM_ SG_ 798 CP_a122_plcModemFailure "Charge port controller: a122 plc modem failure";
CM_ SG_ 798 CP_a123_latchPotIrrational "Charge port controller: a123 latch pot irrational";
CM_ SG_ 798 CP_a124_ivledFault "Charge port controller: a124 ivled fault";
CM_ SG_ 798 CP_a125_unexpectedLVJuiceState "Charge port controller: a125 unexpected LV juice state";
CM_ SG_ 798 CP_a126_wakeOnUhfFault "Charge port controller: a126 wake on uhf fault";
CM_ SG_ 798 CP_a127_lostCommsHVLINK "Charge port controller: a127 lost comms HVLINK";
CM_ SG_ 798 CP_a128_lostCommsVC "Charge port controller: a128 lost comms VC";
CM_ SG_ 798 CP_a129_bldcDriverCommsFailed "Charge port controller: a129 bldc driver comms failed";
CM_ SG_ 798 CP_a130_bldcDriverCommsRecovered "Charge port controller: a130 bldc driver comms recovered";
CM_ SG_ 798 CP_a131_evseCommTimeout "Charge port controller: a131 evse comm timeout";
CM_ SG_ 798 CP_a132_contractAuthTimeout "Charge port controller: a132 contract auth timeout";
CM_ SG_ 798 CP_a133_proxNeverLatched "Charge port controller: a133 prox never latched";
CM_ SG_ 798 CP_a134_plcModemNotExpected "Charge port controller: a134 plc modem not expected";
CM_ SG_ 798 CP_a135_sdpAttemptsFailed "Charge port controller: a135 sdp attempts failed";
CM_ SG_ 798 CP_a136_sdpSideReqFailed "Charge port controller: a136 sdp side req failed";
CM_ SG_ 798 CP_a137_plcForwardError "Charge port controller: a137 plc forward error";
CM_ SG_ 798 CP_a138_swcanCommsAcEvseFaulted "Charge port controller: a138 swcan comms ac evse faulted";
CM_ SG_ 798 CP_a139_pilotFaulted "Charge port controller: a139 pilot faulted";
CM_ SG_ 798 CP_a140_superchargerFaulted "Charge port controller: a140 supercharger faulted";
CM_ SG_ 798 CP_a141_chademoAdapterFault "Charge port controller: a141 chademo adapter fault";
CM_ SG_ 798 CP_a142_gbdcScConnFault "Charge port controller: a142 gbdc sc conn fault";
CM_ SG_ 798 CP_a143_unsupportedChargeAdapter "Charge port controller: a143 unsupported charge adapter";
CM_ SG_ 798 CP_a144_nvmInitFailed "Charge port controller: a144 nvm init failed";
CM_ SG_ 798 CP_a145_modemAppLoadFailedNA "Charge port controller: a145 modem app load failed NA";
CM_ SG_ 798 CP_a146_ccsEvseMalfunction "Charge port controller: a146 ccs evse malfunction";
CM_ SG_ 798 CP_a147_inductiveRecoveredMia "Charge port controller: a147 inductive recovered mia";
CM_ SG_ 798 CP_a148_bldcTachFeedbackMia "Charge port controller: a148 bldc tach feedback mia";
CM_ SG_ 798 CP_a149_pilotPeriodInvalid "Charge port controller: a149 pilot period invalid";
CM_ SG_ 798 CP_a150_railToggleTimeout "Charge port controller: a150 rail toggle timeout";
CM_ SG_ 798 CP_a151_badPilotDiodeDetected "Charge port controller: a151 bad pilot diode detected";
CM_ SG_ 798 CP_a152_pilotEdgeDetectionFailed "Charge port controller: a152 pilot edge detection failed";
CM_ SG_ 798 CP_a153_thermalAcLimitActive "Charge port controller: a153 thermal ac limit active";
CM_ SG_ 798 CP_a154_acChargingStoppedOT "Charge port controller: a154 ac charging stopped OT";
CM_ SG_ 798 CP_a155_hallPresenceRationality "Charge port controller: a155 hall presence rationality";
CM_ SG_ 798 CP_a156_gbdcPrechargingConcern "Charge port controller: a156 gbdc precharging concern";
CM_ SG_ 798 CP_a157_doorOpenRateLimiter "Charge port controller: a157 door open rate limiter";
CM_ SG_ 798 CP_a158_doorCloseRateLimiter "Charge port controller: a158 door close rate limiter";
CM_ SG_ 798 CP_a159_swcanHealthCheckFailed "Charge port controller: a159 swcan health check failed";
CM_ SG_ 798 CP_a160_latchDisengageInDcCharge "Charge port controller: a160 latch disengage in dc charge";
CM_ SG_ 798 CP_a161_badPilotDiodeDetectedCN "Charge port controller: a161 bad pilot diode detected CN";
CM_ SG_ 798 CP_a162_pilotEdgeDetectionFailed "Charge port controller: a162 pilot edge detection failed CN";
CM_ SG_ 798 CP_a163_coverOpenDcChgBlocked "Charge port controller: a163 cover open dc chg blocked";
CM_ SG_ 798 CP_a164_latchRedisengageRequeste "Charge port controller: a164 latch redisengage requested";
CM_ SG_ 798 CP_a165_proxWiggleDetected "Charge port controller: a165 prox wiggle detected";
CM_ SG_ 798 CP_a166_faultLineMismatchDetecte "Charge port controller: a166 fault line mismatch detected";
CM_ SG_ 798 CP_a167_doorIdIrrational "Charge port controller: a167 door id irrational";
CM_ SG_ 798 CP_a172_triggerOdin "Signal reported by Charge port controller";
CM_ SG_ 798 CP_a173_coverOpenAcChgBlocked "Charge port controller: a173 cover open ac chg blocked";
CM_ SG_ 798 CP_a174_fwdedMsgLoadWarning "Charge port controller: a174 fwded msg load warning";
CM_ SG_ 798 CP_a175_fwdedMsgDropped "Charge port controller: a175 fwded msg dropped";
CM_ SG_ 798 CP_a177_incompatibleV2lDeviceDet "Charge port controller: a177 incompatible v2l device detected";
CM_ SG_ 798 CP_a179_evseCommsTlsError "Charge port controller: a179 evse comms tls error";
CM_ SG_ 798 CP_a182_pncdCommsError "Charge port controller: a182 pncd comms error";
CM_ SG_ 798 CP_a183_certManagerError "Charge port controller: a183 cert manager error";
CM_ SG_ 798 CP_a184_certChangeEvent "Charge port controller: a184 cert change event";
CM_ SG_ 798 CP_a185_pncAuthRejection "Charge port controller: a185 pnc auth rejection";
CM_ SG_ 798 CP_a186_spiDmaFailure "Charge port controller: a186 spi dma failure";
CM_ SG_ 798 CP_a187_highStackUsage "Charge port controller: a187 high stack usage";
CM_ BO_ 1085 "Charge port controller message: charge status log";
CM_ SG_ 1085 CP_hvChargeStatus_log "Charge port controller: hv charge status log";
CM_ SG_ 1085 CP_chargeShutdownRequest_log "Charge port controller: charge shutdown request log";
CM_ SG_ 1085 CP_acChargeCurrentLimit_log "Charge port controller: ac charge current limit log";
CM_ SG_ 1085 CP_internalMaxDcCurrentLimit_log "Charge port controller: internal max dc current limit log";
CM_ SG_ 1085 CP_vehicleIsoCheckRequired_log "Charge port controller: vehicle iso check required log";
CM_ SG_ 1085 CP_vehiclePrechargeRequired_log "Charge port controller: vehicle precharge required log";
CM_ SG_ 1085 CP_internalMaxAcCurrentLimit_log "Charge port controller: internal max ac current limit log";
CM_ SG_ 1085 CP_evseChargeType_log "Charge port controller: evse charge type log";
CM_ SG_ 1085 CP_chgLimitMode_log "Charge port controller: chg limit mode log";
CM_ BO_ 669 "Charge port controller message: dc charge status";
CM_ SG_ 669 CP_evseOutputDcCurrent "The DC EVSE's measured output current";
CM_ SG_ 669 CP_evseOutputDcVoltage "The DC EVSE's measured output voltage";
CM_ SG_ 669 CP_evseOutputDcCurrentStale "Indicates whether the data in CP_evseOutputDcCurrent has not been updated with new info from the DC EVSE recently";
CM_ BO_ 541 "Charge port controller message: evse status";
CM_ SG_ 541 CP_evseAccept "State of pilot EVSE accept state";
CM_ SG_ 541 CP_evseRequest "Request to close AC EVSE relays, used when digital communications have been established";
CM_ SG_ 541 CP_proximity "Sensed state of proximity for all inlets";
CM_ SG_ 541 CP_pilot "State of EVSE pilot signal sensed by the charge port";
CM_ SG_ 541 CP_digitalCommsEstablished "Indicates whether digital communications have been established with an EVSE";
CM_ SG_ 541 CP_pilotCurrent "Line current limit detected from pilot signal";
CM_ SG_ 541 CP_cableType "Type of charge cable detected";
CM_ SG_ 541 CP_iecPilotState "State of the control pilot as defined in IEC-61851-1";
CM_ SG_ 541 CP_plcSupported "Indicates whether PLC hardware is populated for CCS charging support";
CM_ SG_ 541 CP_cableCurrentLimit "Charge port controller: cable current limit";
CM_ SG_ 541 CP_teslaSwcanState "Charge port controller: tesla swcan state";
CM_ SG_ 541 CP_evseChargeType_UI "Reports the type of Electric Vehicle Supply Equipment (EVSE) connected.";
CM_ SG_ 541 CP_gbState "State of GB DC charging";
CM_ SG_ 541 CP_gbdcStopChargeReason "Reason for stopping GB DC charging";
CM_ SG_ 541 CP_gbdcFailureReason "Reason for failure of GB DC charging";
CM_ SG_ 541 CP_gbdcChargeAttempts "Number of GB DC charging retries used";
CM_ SG_ 541 CP_acChargeState "Charge port controller: ac charge state";
CM_ SG_ 541 CP_teslaDcState "Reports the state of the Tesla direct current (DC) state machine.";
CM_ BO_ 1342 "Charge port controller message: info";
CM_ SG_ 1342 CP_infoIndex "Charge port controller: info index";
CM_ SG_ 1342 CP_buildType "Charge port controller: build type";
CM_ SG_ 1342 CP_buildConfigId "Charge port controller: build config id";
CM_ SG_ 1342 CP_hardwareId "Charge port controller: hardware id";
CM_ SG_ 1342 CP_componentId "Charge port controller: component id";
CM_ SG_ 1342 CP_pcbaId "Charge port controller: pcba id";
CM_ SG_ 1342 CP_assemblyId "Charge port controller: assembly id";
CM_ SG_ 1342 CP_usageId "Charge port controller: usage id";
CM_ SG_ 1342 CP_subUsageId "Charge port controller: sub usage id";
CM_ SG_ 1342 CP_platformType "Charge port controller: platform type";
CM_ SG_ 1342 CP_appCrc "Charge port controller: app crc";
CM_ SG_ 1342 CP_appGitHash "Charge port controller: app git hash";
CM_ SG_ 1342 CP_bootGitHash "Charge port controller: boot git hash";
CM_ SG_ 1342 CP_bootUdsProtoVersion "Charge port controller: boot uds proto version";
CM_ SG_ 1342 CP_bootCrc "Charge port controller: boot crc";
CM_ BO_ 1885 "Charge port controller message: logging fast";
CM_ SG_ 1885 CP_loggingFastSelect "Charge port controller: logging fast select";
CM_ SG_ 1885 CP_inductiveSensor_raw "Charge port controller: inductive sensor raw";
CM_ SG_ 1885 CP_doorOpenActuationTime "Charge port controller: door open actuation time";
CM_ SG_ 1885 CP_doorCloseActuationTime "Charge port controller: door close actuation time";
CM_ SG_ 1885 CP_chargeCableSecured "Indicates whether a charge cable is secured in any inlet";
CM_ SG_ 1885 CP_chargeCablePresent "Indicates whether a charge cable is present in any inlet";
CM_ SG_ 1885 CP_latchCheckAvailable "Charge port controller: latch check available";
CM_ SG_ 1885 CP_UHF_controlState "Control state of UHF receiver";
CM_ SG_ 1885 CP_proximityV "Charge port controller: proximity v";
CM_ SG_ 1885 CP_proximityV_GBCC1 "Sensed voltage of GB DC inlet CC1 connection";
CM_ SG_ 1885 CP_proximityV_GBCC2 "Sensed voltage of GB DC inlet CC2 connection";
CM_ SG_ 1885 CP_doorPot "Position of the charge port door potentiometer";
CM_ SG_ 1885 CP_doorPresenceHallSensorV "Charge port controller: door presence hall sensor v";
CM_ SG_ 1885 CP_doorOpenRequest "Door open request trigger";
CM_ SG_ 1885 CP_doorOpenEndOfDriveReason "Reason why the door stopped moving in the open direction";
CM_ SG_ 1885 CP_coverClosed "Charge port controller: cover closed";
CM_ SG_ 1885 CP_doorCloseEndOfDriveReason "Reason why the door stopped moving in the closing direction";
CM_ SG_ 1885 CP_doorCloseRequest "Door close request trigger";
CM_ SG_ 1885 CP_latchDisengagingTime "Charge port controller: latch disengaging time";
CM_ SG_ 1885 CP_latchEngagingTime "Charge port controller: latch engaging time";
CM_ SG_ 1885 CP_latchDisengagingStopReason "Reason why the latch stopped moving in the engaged direction";
CM_ SG_ 1885 CP_latchEngagingStopReason "Reason why the latch stopped moving in the engaged direction";
CM_ SG_ 1885 CP_doorIdDetectionState "Charge port controller: door id detection state";
CM_ SG_ 1885 CP_doorIdDetectedBin "Charge port controller: door id detected bin";
CM_ BO_ 2042 "Charge port controller message: logging slow";
CM_ SG_ 2042 CP_loggingSlowSelect "Charge port controller: logging slow select";
CM_ SG_ 2042 CP_UHF_chipState "Charge port controller: UHF chip state";
CM_ SG_ 2042 CP_UHF_rssi "Signal strength of received UHF signal";
CM_ SG_ 2042 CP_UHF_rxOverflow "Charge port controller: UHF rx overflow";
CM_ SG_ 2042 CP_UHF_rxNumBytes "Charge port controller: UHF rx num bytes";
CM_ SG_ 2042 CP_UHF_selfTestRssi "Signal strength of received self-test UHF signal";
CM_ SG_ 2042 CP_latchI "Charge port controller: latch i";
CM_ SG_ 2042 CP_inlet1HarnessIdState "State of the CP's inlet 1 harness pedigree";
CM_ SG_ 2042 CP_inlet1HarnessIdValue "Pedigree of the CP's inlet 1 harness";
CM_ SG_ 2042 CP_inlet2HarnessIdState "State of the CP's inlet 2 harness pedigree";
CM_ SG_ 2042 CP_inlet2HarnessIdValue "Pedigree of the CP's inlet 2 harness";
CM_ SG_ 2042 CP_inletHeaterState "Reports the present state of the inlet heater.";
CM_ SG_ 2042 CP_inletHeaterDuty "Inlet heater PWM duty cycle";
CM_ SG_ 2042 CP_nvm_dataValid "Charge port controller: nvm data valid";
CM_ SG_ 2042 CP_nvm_doorOpenCycles "Charge port controller: nvm door open cycles";
CM_ SG_ 2042 CP_nvm_doorCloseCycles "Charge port controller: nvm door close cycles";
CM_ SG_ 2042 CP_nvm_doorOpen "Charge port controller: nvm door open";
CM_ SG_ 2042 CP_nvm_doorPresent "Charge port controller: nvm door present";
CM_ SG_ 2042 CP_nvm_doorPresentValid "Charge port controller: nvm door present valid";
CM_ SG_ 2042 CP_nvm_badPilotDiodeDetected "Charge port controller: nvm bad pilot diode detected";
CM_ SG_ 2042 CP_nvm_pilotDiodeFaultCount "Charge port controller: nvm pilot diode fault count";
CM_ SG_ 2042 CP_doorOpenLimiterMaxCount "Charge port controller: door open limiter max count";
CM_ SG_ 2042 CP_doorOpenLimiterMaxRequestType "Charge port controller: door open limiter max request type";
CM_ SG_ 2042 CP_doorCloseLimiterMaxCount "Charge port controller: door close limiter max count";
CM_ SG_ 2042 CP_doorCloseLimiterMaxRequestTyp "Charge port controller: door close limiter max request type";
CM_ BO_ 528 "Charge port controller message: status";
CM_ SG_ 528 CP_type "Charge port controller: type";
CM_ SG_ 528 CP_insertEnableLine "Sensed state of the charge port latch drive enable hardline";
CM_ SG_ 528 CP_latchState "Sensed state of the charge port latch";
CM_ SG_ 528 CP_permanentPowerRequest "Charge port controller: permanent power request";
CM_ SG_ 528 CP_chargeDoorOpen "Indicates whether the charge port door is open based on all door sensors";
CM_ SG_ 528 CP_doorControlState "State of the charge port door controller";
CM_ SG_ 528 CP_doorButtonPressed "Indicates whether the charge door button has been pressed";
CM_ SG_ 528 CP_swcanRelayClosed "Indicates whether the single wire CAN relay is closed";
CM_ SG_ 528 CP_inhibitOta "Reports the charge port's request to prevent scheduled Over-The-Air (OTA) updates during critical charging operations.";
CM_ SG_ 528 CP_chargeCableState "Charge cable connection state";
CM_ SG_ 528 CP_latchControlState "Control state of the charge port latch";
CM_ SG_ 528 CP_ledColor "Color of the charge port LED";
CM_ SG_ 528 CP_UHF_handleFound "Indicates whether a charge handle has been found with UHF";
CM_ SG_ 528 CP_faultLineSensed "A signal indicating the set / cleared state of the CP-HVP bi-directional fault line, as sensed by the CP";
CM_ SG_ 528 CP_doorPresenceState "State of door as detected by the presence sensor";
CM_ SG_ 528 CP_inductiveSensorState "State of inductive door sensor";
CM_ SG_ 528 CP_chargeDoorOpenUI "Indicates whether the charge port door is open based only on the door poteniometer";
CM_ SG_ 528 CP_vehicleUnlockRequest "Request to unlock the vehicle";
CM_ SG_ 528 CP_coldWeatherMode "Indicates whether the charge port is in cold weather mode";
CM_ SG_ 528 CP_hvInletExposed "Charge port controller: hv inlet exposed";
CM_ SG_ 528 CP_latchEngaged "Charge port controller: latch engaged";
CM_ SG_ 528 CP_inletHeaterUiState "Reports to the User Interface (UI) the state of the inlet heater.";
CM_ BO_ 893 "Charge port controller message: thermal status";
CM_ SG_ 893 CP_thermalStatusSelect "Charge port controller: thermal status select";
CM_ SG_ 893 CP_pinTemperature1 "Sensed temperature of the charge port inlet pins";
CM_ SG_ 893 CP_pinTemperature2 "Sensed temperature of the charge port inlet pins";
CM_ SG_ 893 CP_pinTemperature3 "Sensed temperature of the charge port inlet pins";
CM_ BO_ 1465 "Driver assistance computer message: alert log";
CM_ SG_ 1465 DAS_alertID "Driver assistance computer: alert ID";
CM_ SG_ 1465 DAS_alertState "Driver assistance computer: alert state";
CM_ SG_ 1465 DAS_sw073_escalateLDWs "Driver assistance computer: sw073 escalate LD ws";
CM_ SG_ 1465 DAS_sw073_silentEscalatedLDW "Driver assistance computer: sw073 silent escalated LDW";
CM_ SG_ 1465 DAS_sw073_escalateLDWreason "Driver assistance computer: sw073 escalate LD wreason";
CM_ SG_ 1465 DAS_sw073_rawMobileyeLDW "Driver assistance computer: sw073 raw mobileye LDW";
CM_ SG_ 1465 DAS_sw073_freespaceLDW "Driver assistance computer: sw073 freespace LDW";
CM_ SG_ 1465 DAS_sw073_freespaceLeftC0 "Driver assistance computer: sw073 freespace left C0";
CM_ SG_ 1465 DAS_sw073_freespaceRightC0 "Driver assistance computer: sw073 freespace right C0";
CM_ SG_ 1465 DAS_sw073_freespaceLeftC1 "Driver assistance computer: sw073 freespace left C1";
CM_ SG_ 1465 DAS_sw073_freespaceRightC1 "Driver assistance computer: sw073 freespace right C1";
CM_ SG_ 1465 DAS_sw073_freespaceLeftFarZ "Driver assistance computer: sw073 freespace left far z";
CM_ SG_ 1465 DAS_sw073_freespaceRightFarZ "Driver assistance computer: sw073 freespace right far z";
CM_ SG_ 1465 DAS_sw230_sensor1Blocked "Driver assistance computer: sw230 sensor1 blocked";
CM_ SG_ 1465 DAS_sw230_sensor2Blocked "Driver assistance computer: sw230 sensor2 blocked";
CM_ SG_ 1465 DAS_sw230_sensor3Blocked "Driver assistance computer: sw230 sensor3 blocked";
CM_ SG_ 1465 DAS_sw230_sensor4Blocked "Driver assistance computer: sw230 sensor4 blocked";
CM_ SG_ 1465 DAS_sw230_sensor5Blocked "Driver assistance computer: sw230 sensor5 blocked";
CM_ SG_ 1465 DAS_sw230_sensor6Blocked "Driver assistance computer: sw230 sensor6 blocked";
CM_ SG_ 1465 DAS_sw230_sensor7Blocked "Driver assistance computer: sw230 sensor7 blocked";
CM_ SG_ 1465 DAS_sw230_sensor8Blocked "Driver assistance computer: sw230 sensor8 blocked";
CM_ SG_ 1465 DAS_sw230_sensor9Blocked "Driver assistance computer: sw230 sensor9 blocked";
CM_ SG_ 1465 DAS_sw230_sensor10Blocked "Driver assistance computer: sw230 sensor10 blocked";
CM_ SG_ 1465 DAS_sw230_sensor11Blocked "Driver assistance computer: sw230 sensor11 blocked";
CM_ SG_ 1465 DAS_sw230_sensor12Blocked "Driver assistance computer: sw230 sensor12 blocked";
CM_ BO_ 583 "Driver assistance computer message: autopilot debug";
CM_ SG_ 583 DAS_roadEstimator "Driver assistance computer: road estimator";
CM_ SG_ 583 DAS_arbiterBehavior "Which behavior task the arbiter has selected and sent to the controller";
CM_ SG_ 583 DAS_mapAvailability "Driver assistance computer: map availability";
CM_ SG_ 583 DAS_controllerRef "Driver assistance computer: controller ref";
CM_ SG_ 583 DAS_alcInternalState "Reports the internal state of the Automatic Lane Change (ALC) machine.";
CM_ SG_ 583 DAS_behaviorReport "Which target source are we controlling for longitudinally.";
CM_ SG_ 583 DAS_constructionZone "Driver assistance computer: construction zone";
CM_ SG_ 583 DAS_controllerHealth "Driver assistance computer: controller health";
CM_ SG_ 583 DAS_controlDistance "Driver assistance computer: control distance";
CM_ SG_ 583 DAS_autopilotAbortReason "Driver assistance computer: autopilot abort reason";
CM_ SG_ 583 DAS_rqstedBehaviorStatus "Indicates the autopilot behavior state with respect to automatic lane change.";
CM_ SG_ 583 DAS_forkState "Reports the internal state of the mission planner fork state machine.";
CM_ SG_ 583 DAS_laneChangeState "Indicates the state of the lane change state machine.";
CM_ SG_ 583 DAS_lastWatchdogCode "Tracks the last APP task to have triggered a Watchdog reset.";
CM_ BO_ 1001 "Driver assistance computer message: body controls";
CM_ SG_ 1001 DAS_headlightRequest "The DAS request to the body controls ecu to turn on headlights.";
CM_ SG_ 1001 DAS_hazardLightRequest "The command from DAS to body controls to turn on the hazard lights.";
CM_ SG_ 1001 DAS_wiperSpeed "The auto wiper algorithm speed request to the body controller.";
CM_ SG_ 1001 DAS_turnIndicatorRequest "Reports Driver Assistance System (DAS) request to body controls to turn on/off the left or right turn indicator.";
CM_ SG_ 1001 DAS_highLowBeamDecision "The output of the automatic high beam algorithm, to turn the highbeams on or off.";
CM_ SG_ 1001 DAS_heaterRequest "The DAS request to the body controller to turn on the front glass heater in front of the triple camera.";
CM_ SG_ 1001 DAS_highLowBeamOffReason "The reason why automatic high beams are surpressed.";
CM_ SG_ 1001 DAS_forwardCamHeaterDutyCycle "Supplies the requested duty cycle of the front windshield camera heater";
CM_ SG_ 1001 DAS_dynamicBrakeLightRequest "Indicates if the dynamic brake light alogirthm is requesting pulsing brake lights.";
CM_ SG_ 1001 DAS_radarHeaterRequest "Reports the request from Driver Assistance System (DAS) to body controls to turn on heater to clear out fascia in front of the radar.";
CM_ SG_ 1001 DAS_ahlbOverride "Indicates if body controller should override UI switch and stalk state to allow auto high beam functionality";
CM_ SG_ 1001 DAS_mirrorFoldRequest "DAS request to fold or present mirrors.";
CM_ SG_ 1001 DAS_wiperWashRequest "Autowiper requests that the windshield be washed";
CM_ SG_ 1001 DAS_ulcConfirmationRequestActive "Driver assistance computer: ulc confirmation request active";
CM_ SG_ 1001 DAS_overrideWiperSetting "Autopilot wants to override the user's wiper setting to enable auto-wiper";
CM_ SG_ 1001 DAS_autoWiperState "DAS auto wiper internal state";
CM_ SG_ 1001 DAS_turnIndicatorRequestReason "Reports the reason that Driver Assistance System (DAS) is requesting a change to the turn indicator state from body controls.";
CM_ SG_ 1001 DAS_forwardRadarPowerRequest "Driver assistance computer: forward radar power request";
CM_ SG_ 1001 DAS_driverDomeLightRequest "DAS requests that driver side dome light be illuminated";
CM_ SG_ 1001 DAS_drivePowerStateRequest "Reports DAS request for vehicle power state Drive.";
CM_ SG_ 1001 DAS_enableIcrDataCollection "Driver assistance computer: enable icr data collection";
CM_ SG_ 1001 DAS_rPillarCamHeaterDutyCycle "Supplies the requested duty cycle of the right pillar camera heater";
CM_ SG_ 1001 DAS_adaptiveHighBeamIsFaulted "Indicates malfunctioning or unavailable input to the Adaptive High Beam system.";
CM_ SG_ 1001 DAS_restrictDoorReleaseLeft "Reports requests to inhibit left doors from being released.";
CM_ SG_ 1001 DAS_restrictDoorReleaseRight "Reports requests to inhibit right doors from being released.";
CM_ SG_ 1001 DAS_bodyControlsCounter "Driver assistance computer: body controls counter";
CM_ SG_ 1001 DAS_bodyControlsChecksum "Driver assistance computer: body controls checksum";
CM_ BO_ 1497 "Driver assistance computer message: car log";
CM_ SG_ 1497 DAS_carLogMultiplexer "Driver assistance computer: car log multiplexer";
CM_ SG_ 1497 DAS_radarTarget5_dx "Measures the longitudinal distance from the radar to the nearest in-path stationary radar target.";
CM_ SG_ 1497 DAS_radarTarget1_dx "The longitudinal distance from the radar to radar target 1 (closest in-path vehicle)";
CM_ SG_ 1497 DAS_radarTarget1_VxRel "Measures the relative longitudinal velocity to the Adaptive Cruise Control (ACC) radar target 1.";
CM_ SG_ 1497 DAS_mobileyeVehAebFlag "Driver assistance computer: mobileye veh aeb flag";
CM_ SG_ 1497 DAS_mobileyePedAebFlag "Driver assistance computer: mobileye ped aeb flag";
CM_ SG_ 1497 DAS_mobileyeIPSOapproved "Driver assistance computer: mobileye IPS oapproved";
CM_ SG_ 1497 DAS_fcmSteeringOverride "Driver assistance computer: fcm steering override";
CM_ SG_ 1497 DAS_fcmCollisionStage3Checks "Reports the cross checks in the forward collision monitor.";
CM_ SG_ 1497 DAS_fcmThreatAssesmentMode "Driver assistance computer: fcm threat assesment mode";
CM_ SG_ 1497 DAS_constructionArea "Identifies construction area using the output of the 'scene tag' neural net.";
CM_ SG_ 1497 DAS_restrictionLowSpeedTraffic "Reports lane change restriction for low speed traffic.";
CM_ SG_ 1497 DAS_associated_rad_object "Indicates which radar target is associated with the vision object for Forward Collision Mitigation (FCM).";
CM_ SG_ 1497 DAS_LC_handsOnReason "Detects which hands on reason triggered the visual or audible hands-on-warning.";
CM_ SG_ 1497 DAS_ACC_camStatus "Driver assistance computer: ACC cam status";
CM_ SG_ 1497 DAS_aeb_not_activating_reason "Indicates the underlying reason why the next gen LCM AEB did not activate (not yet relevant)";
CM_ SG_ 1497 DAS_handsOnDetected "Driver assistance computer: hands on detected";
CM_ SG_ 1497 DAS_driveOnNavUnavailableReason "The high level reason why Navigate on Autopilot is not available.";
CM_ SG_ 1497 DAS_accUnavailableReason "The high level reason why ACC is not available.";
CM_ SG_ 1497 DAS_pmmNotActivatingReason "The high level reason why PMM v2 is not activating.";
CM_ SG_ 1497 DAS_desiredTarget_dx "Measures the distance to lead vehicle, or vehicle in the ego lane.";
CM_ SG_ 1497 DAS_radarTarget2_dx "Measures the longitudinal distance from the radar to radar target 2, the 2nd closest in-path vehicle.";
CM_ SG_ 1497 DAS_radarTarget3_dx "Measures the longitudinal distance from the radar to the nearest vehicle in the right lane.";
CM_ SG_ 1497 DAS_radarTarget4_dx "Measures the longitudinal distance from the radar to the nearest vehicle in the left lane.";
CM_ SG_ 1497 DAS_closestInLaneTargetDx "Measures the longitudinal distance from front fascia to closest in-path object.";
CM_ SG_ 1497 DAS_secondInLaneTargetDx "Measures the longitudinal distance from front fascia to 2nd closest in-path object.";
CM_ SG_ 1497 DAS_closestLeftLaneTargetDx "Measures the longitudinal distance from front fascia to closest object in the left lane.";
CM_ SG_ 1497 DAS_closestRightLaneTargetDx "Measures the longitudinal distance from front fascia to closest object in the right lane.";
CM_ SG_ 1497 DAS_closestInLaneTargetVxRel "Measures the relative longitudinal velocity of closest in-path object.";
CM_ BO_ 697 "Driver assistance computer message: control";
CM_ SG_ 697 DAS_setSpeed "Detects the commanded Traffic Aware Cruise Control (TACC) or Autopilot set speed for the Drive Inverter (DI).";
CM_ SG_ 697 DAS_accState "Reports the state of Adaptive Cruise Control (ACC), Traffic-Aware Cruise Control (TACC), and Autopark / Summon.";
CM_ SG_ 697 DAS_aebEvent "Driver assistance computer: aeb event";
CM_ SG_ 697 DAS_jerkMin "Reports the minimum allowed jerk the Drive Inverter (DI) can generate to reach the commanded set speed.";
CM_ SG_ 697 DAS_jerkMax "Reports the maximum allowed jerk the Drive Inverter (DI) can generate to reach the commanded set speed.";
CM_ SG_ 697 DAS_accelMin "Reports the minimum acceleration the drive inverter can apply to reach the commanded set speed.";
CM_ SG_ 697 DAS_accelMax "Reports the maximum acceleration the drive inverter can apply to reach the commanded set speed.";
CM_ SG_ 697 DAS_controlCounter "Driver assistance computer: control counter";
CM_ SG_ 697 DAS_controlChecksum "Driver assistance computer: control checksum";
CM_ BO_ 2041 "Driver assistance computer message: gps status";
CM_ SG_ 2041 DAS_gpsStatusMultiplexer "Driver assistance computer: gps status multiplexer";
CM_ SG_ 2041 DAS_gpsTransportModeState "Indicates if the transport mode algorithm detects the car is in transport mode.";
CM_ SG_ 2041 DAS_gpsSatsInUseHardware "The number of GPS satellites currently in use by hardware solution.";
CM_ SG_ 2041 DAS_gpsWheeltickCounter "Driver assistance computer: gps wheeltick counter";
CM_ SG_ 2041 DAS_gpsWheeltickPulsePeriod "Driver assistance computer: gps wheeltick pulse period";
CM_ SG_ 2041 DAS_gpsRejectingSatData "Indicates whether or not the GPS is rejecting satellites due to poor signal.";
CM_ SG_ 2041 DAS_gpsWheelsOffMotionDetected "Indicates that wheels-off acceleration detected";
CM_ SG_ 2041 DAS_gpsFixTypeHardware "The fix type of the GPS receiver, see u-blox M8 spec, section 33.13.1.1";
CM_ SG_ 2041 DAS_gpsRawxEnabled "GPS receiver has raw messages enabled";
CM_ SG_ 2041 DAS_gpsRxmRawxMia "Driver assistance computer: gps rxm rawx mia";
CM_ SG_ 2041 DAS_gpsRxmSfrbxMia "Driver assistance computer: gps rxm sfrbx mia";
CM_ SG_ 2041 DAS_gpsEsfMeasMia "AP is not receiving EsfMeas message from GPS receiver";
CM_ SG_ 2041 DAS_gpsEsfRawMia "AP is not receiving EsfRaw message from GPS receiver";
CM_ SG_ 2041 DAS_gpsNavStatusMia "AP is not receiving NavStatus message from GPS receiver";
CM_ SG_ 2041 DAS_gpsSoftwareConfigured "Software GPS solution is allowed";
CM_ SG_ 2041 DAS_gpsSoftwareUsed "Software GPS solution is actively used";
CM_ SG_ 2041 DAS_gpsSoftwareFastStartReady "Software GPS solution could use fast start mechanism at boot-up";
CM_ SG_ 2041 DAS_gpsSatsInUseSoftware "The number of GPS satellites currently in use by software solution on SOC-A.";
CM_ SG_ 2041 DAS_gpsFixTypeSoftware "The fix type of the GPS software solution on SOC-A.";
CM_ SG_ 2041 DAS_gpsCWJammingInidcator "Level of continuous wave jamming detected by GPS hardware";
CM_ SG_ 2041 DAS_gpsJammingState "State of GPS jamming monitor";
CM_ SG_ 2041 DAS_gpsSpoofDetectorState "Instantaneous state of GPS spoofing detector. Detection only triggers at the transition from real to suspected spoof signal.";
CM_ SG_ 2041 DAS_gpsInvalidMsgPercentage "Percentage of messages received by AP from GPS receiver that were invalid. Calculated over up-to 10s window.";
CM_ SG_ 2041 DAS_gnssConstellationsState "Indicates if GNSS constellations match expected configuration.";
CM_ SG_ 2041 DAS_gpsReceiverNoiseLevel "General noise level of GPS receiver.";
CM_ SG_ 2041 DAS_gpsAutomaticGainControl "Automatic Gain Control of GPS receiver.";
CM_ SG_ 2041 DAS_gpsPreviousPositionDeltaHw "Change in position of two consecutive location outputs from GPS hardware solution.";
CM_ SG_ 2041 DAS_gpsPreviousPositionDeltaSw "Change in position of two consecutive location outputs from GPS software solution.";
CM_ SG_ 2041 DAS_gpsNmeaDispatchFailureCount "Number of GPS messages dropped by AP without sending over to UI. Calculated over up-to 10s window.";
CM_ SG_ 2041 DAS_gnssMaxInstantaneousCnorGps "Maximum carrier-to-noise ratio among all satellites from GPS constellation.";
CM_ SG_ 2041 DAS_gnssMaxInstantaneousCnorGal "Maximum carrier-to-noise ratio among all satellites from GALILEO constellation.";
CM_ SG_ 2041 DAS_gnssMaxInstantaneousCnorBds "Maximum carrier-to-noise ratio among all satellites from BEIDOU constellation.";
CM_ SG_ 2041 DAS_gpsResetReason "When AP resets GPS receiver, this signal indicates the reason why";
CM_ SG_ 2041 DAS_gpsAccuracyHorizontal "Self-reported horizontal GPS accuracy";
CM_ SG_ 2041 DAS_gpsAccuracyVertical "Self-reported vertical GPS accuracy";
CM_ SG_ 2041 DAS_gpsSolutionFallback "GPS solution falling back from software to hardware";
CM_ SG_ 2041 DAS_gpsToMcuSource "This signal exposes which localization solution is being sent to the MCU.";
CM_ SG_ 2041 DAS_gpsSolutionSoc "Reports which System on Chip (SOC) is producing the GPS localization solution.";
CM_ SG_ 2041 DAS_gpsRedundancyActive "Reports whether the GPS Redundancy feature is active on the Autopilot (AP) board. This feature enables either System on Chip (SOC) to publish the Global Navigation Satellite System (GNSS) solution.";
CM_ SG_ 2041 DAS_gpsFixTypeSoftwareSocB "Reports the fix type of the GPS software solution on System on Chip B (SOC-B).";
CM_ SG_ 2041 DAS_gpsSatsInUseSoftwareSocB "Reports the number of GPS satellites currently in use by software solution on System on Chip B (SOC-B).";
CM_ SG_ 2041 DAS_gnssNumSatsGps "Number of satellites visible from GPS constellation.";
CM_ SG_ 2041 DAS_gnssNumSatsGal "Number of satellites visible from GALILEO constellation.";
CM_ SG_ 2041 DAS_gnssNumSatsBds "Number of satellites visible from BEIDOU constellation.";
CM_ SG_ 2041 DAS_gnssAvgInstantaneousCnorGps "Average carrier-to-noise ratio among all satellites from GPS constellation on the high band as reported by the Positioning Engine on SOC-A.";
CM_ SG_ 2041 DAS_gnssAvgInstantaneousCnorGal "Average carrier-to-noise ratio among all satellites from GALILEO constellation on the high band.";
CM_ SG_ 2041 DAS_gnssAvgInstantaneousCnorBds "Average carrier-to-noise ratio among all satellites from BEIDOU constellation on the high band as reported by the Positioning Engine on SOC-A.";
CM_ SG_ 2041 DAS_gnssAvgInstantCnorGpsSocB "Driver assistance computer: gnss avg instant cnor gps soc b";
CM_ SG_ 2041 DAS_gnssAvgInstantCnorBdsSocB "Driver assistance computer: gnss avg instant cnor bds soc b";
CM_ SG_ 2041 DAS_gnssAvgInstantaneousCnorGpsL "Measures the average carrier-to-noise ratio among all satellites from GPS constellation on the low band as reported by the Positioning Engine on System on Chip A (SOC-A).";
CM_ SG_ 2041 DAS_gnssAvgInstantaneousCnorGalL "Measures the average carrier-to-noise ratio among all satellites from GALILEO constellation on the low band.";
CM_ SG_ 2041 DAS_gnssAvgInstantaneousCnorBdsL "Measures the average carrier-to-noise ratio among all satellites from BEIDOU constellation on the low band as reported by the Positioning Engine on System on Chip A (SOC-A).";
CM_ BO_ 1337 "Driver assistance computer message: info";
CM_ SG_ 1337 DAS_infoIndex "Driver assistance computer: info index";
CM_ SG_ 1337 DAS_infoBuildType "Driver assistance computer: info build type";
CM_ SG_ 1337 DAS_infoBuildConfigID "Driver assistance computer: info build config ID";
CM_ SG_ 1337 DAS_infoHardwareID "Driver assistance computer: info hardware ID";
CM_ SG_ 1337 DAS_infoComponentID "Driver assistance computer: info component ID";
CM_ SG_ 1337 DAS_infoPcbaID "Driver assistance computer: info pcba ID";
CM_ SG_ 1337 DAS_infoAssemblyID "Driver assistance computer: info assembly ID";
CM_ SG_ 1337 DAS_infoUsageID "Driver assistance computer: info usage ID";
CM_ SG_ 1337 DAS_infoSubUsageID "Driver assistance computer: info sub usage ID";
CM_ SG_ 1337 DAS_infoApplicationCRC "Driver assistance computer: info application CRC";
CM_ SG_ 1337 DAS_infoAppGitHashBytes "Driver assistance computer: info app git hash bytes";
CM_ SG_ 1337 DAS_infoBootGitHashBytes "Driver assistance computer: info boot git hash bytes";
CM_ BO_ 569 "Driver assistance computer message: lanes";
CM_ SG_ 569 DAS_leftLaneExists "Driver assistance computer: left lane exists";
CM_ SG_ 569 DAS_rightLaneExists "Driver assistance computer: right lane exists";
CM_ SG_ 569 DAS_virtualLaneWidth "Driver assistance computer: virtual lane width";
CM_ SG_ 569 DAS_virtualLaneViewRange "Driver assistance computer: virtual lane view range";
CM_ SG_ 569 DAS_virtualLaneC0 "Driver assistance computer: virtual lane C0";
CM_ SG_ 569 DAS_virtualLaneC1 "Driver assistance computer: virtual lane C1";
CM_ SG_ 569 DAS_virtualLaneC2 "Driver assistance computer: virtual lane C2";
CM_ SG_ 569 DAS_virtualLaneC3 "Driver assistance computer: virtual lane C3";
CM_ SG_ 569 DAS_leftLineUsage "Driver assistance computer: left line usage";
CM_ SG_ 569 DAS_rightLineUsage "Driver assistance computer: right line usage";
CM_ SG_ 569 DAS_leftFork "Driver assistance computer: left fork";
CM_ SG_ 569 DAS_rightFork "Driver assistance computer: right fork";
CM_ SG_ 569 DAS_lanesCounter "Driver assistance computer: lanes counter";
CM_ BO_ 777 "Driver assistance computer message: object";
CM_ SG_ 777 DAS_objectId "Driver assistance computer: object id";
CM_ SG_ 777 DAS_leadVehType "Driver assistance computer: lead veh type";
CM_ SG_ 777 DAS_leadVehRelevantForControl "Driver assistance computer: lead veh relevant for control";
CM_ SG_ 777 DAS_leadVehDx "Measures the distance to lead vehicle, or vehicle in the ego lane.";
CM_ SG_ 777 DAS_leadVehVxRel "Driver assistance computer: lead veh vx rel";
CM_ SG_ 777 DAS_leadVehDy "Driver assistance computer: lead veh dy";
CM_ SG_ 777 DAS_leadVehId "Driver assistance computer: lead veh id";
CM_ SG_ 777 DAS_leadVeh2Type "Driver assistance computer: lead veh2 type";
CM_ SG_ 777 DAS_leadVeh2RelevantForControl "Driver assistance computer: lead veh2 relevant for control";
CM_ SG_ 777 DAS_leadVeh2Dx "Driver assistance computer: lead veh2 dx";
CM_ SG_ 777 DAS_leadVeh2VxRel "Driver assistance computer: lead veh2 vx rel";
CM_ SG_ 777 DAS_leadVeh2Dy "Driver assistance computer: lead veh2 dy";
CM_ SG_ 777 DAS_leadVeh2Id "Driver assistance computer: lead veh2 id";
CM_ SG_ 777 DAS_leftVehType "Driver assistance computer: left veh type";
CM_ SG_ 777 DAS_leftVehRelevantForControl "Driver assistance computer: left veh relevant for control";
CM_ SG_ 777 DAS_leftVehDx "Driver assistance computer: left veh dx";
CM_ SG_ 777 DAS_leftVehVxRel "Driver assistance computer: left veh vx rel";
CM_ SG_ 777 DAS_leftVehDy "Driver assistance computer: left veh dy";
CM_ SG_ 777 DAS_leftVehId "Driver assistance computer: left veh id";
CM_ SG_ 777 DAS_leftVeh2Type "Driver assistance computer: left veh2 type";
CM_ SG_ 777 DAS_leftVeh2RelevantForControl "Driver assistance computer: left veh2 relevant for control";
CM_ SG_ 777 DAS_leftVeh2Dx "Driver assistance computer: left veh2 dx";
CM_ SG_ 777 DAS_leftVeh2VxRel "Driver assistance computer: left veh2 vx rel";
CM_ SG_ 777 DAS_leftVeh2Dy "Driver assistance computer: left veh2 dy";
CM_ SG_ 777 DAS_leftVeh2Id "Driver assistance computer: left veh2 id";
CM_ SG_ 777 DAS_rightVehType "Driver assistance computer: right veh type";
CM_ SG_ 777 DAS_rightVehRelevantForControl "Driver assistance computer: right veh relevant for control";
CM_ SG_ 777 DAS_rightVehDx "Driver assistance computer: right veh dx";
CM_ SG_ 777 DAS_rightVehVxRel "Driver assistance computer: right veh vx rel";
CM_ SG_ 777 DAS_rightVehDy "Driver assistance computer: right veh dy";
CM_ SG_ 777 DAS_rightVehId "Driver assistance computer: right veh id";
CM_ SG_ 777 DAS_rightVeh2Type "Driver assistance computer: right veh2 type";
CM_ SG_ 777 DAS_rightVeh2RelevantForControl "Driver assistance computer: right veh2 relevant for control";
CM_ SG_ 777 DAS_rightVeh2Dx "Driver assistance computer: right veh2 dx";
CM_ SG_ 777 DAS_rightVeh2VxRel "Driver assistance computer: right veh2 vx rel";
CM_ SG_ 777 DAS_rightVeh2Dy "Driver assistance computer: right veh2 dy";
CM_ SG_ 777 DAS_rightVeh2Id "Driver assistance computer: right veh2 id";
CM_ SG_ 777 DAS_cutinVehType "Driver assistance computer: cutin veh type";
CM_ SG_ 777 DAS_cutinVehRelevantForControl "Driver assistance computer: cutin veh relevant for control";
CM_ SG_ 777 DAS_cutinVehDx "Driver assistance computer: cutin veh dx";
CM_ SG_ 777 DAS_cutinVehVxRel "Driver assistance computer: cutin veh vx rel";
CM_ SG_ 777 DAS_cutinVehDy "Driver assistance computer: cutin veh dy";
CM_ SG_ 777 DAS_cutinVehId "Driver assistance computer: cutin veh id";
CM_ SG_ 777 DAS_roadSignColor "Driver assistance computer: road sign color";
CM_ SG_ 777 DAS_roadSignId "Driver assistance computer: road sign id";
CM_ SG_ 777 DAS_roadSignStopLineDist "Driver assistance computer: road sign stop line dist";
CM_ SG_ 777 DAS_roadSignControlActive "Driver assistance computer: road sign control active";
CM_ SG_ 777 DAS_roadSignSource "Driver assistance computer: road sign source";
CM_ SG_ 777 DAS_roadSignArrow "Driver assistance computer: road sign arrow";
CM_ SG_ 777 DAS_roadSignOrientation "Driver assistance computer: road sign orientation";
BA_DEF_ BO_ "GenMsgCycleTime" INT 0 3600000;
BA_DEF_ BO_ "GenMsgSendType" ENUM "Cyclic","NotUsed","NotUsed","NotUsed","NotUsed","NotUsed","NotUsed","IfActive","NoMsgSendType","NotUsed";
BA_DEF_ BO_ "VFrameFormat" ENUM "StandardCAN","ExtendedCAN","reserved","J1939PG","reserved","reserved","reserved","reserved","reserved","reserved","reserved","reserved","reserved","reserved","StandardCAN_FD","ExtendedCAN_FD";
BA_DEF_ BO_ "CANFD_BRS" ENUM "0","1";
BA_DEF_ SG_ "SystemSignalLongSymbol" STRING;
BA_DEF_ SG_ "Confidence" ENUM "layout-only","plausible","validated";
BA_DEF_DEF_ "GenMsgCycleTime" 0;
BA_DEF_DEF_ "GenMsgSendType" "NoMsgSendType";
BA_DEF_DEF_ "VFrameFormat" "StandardCAN";
BA_DEF_DEF_ "CANFD_BRS" "1";
BA_DEF_DEF_ "SystemSignalLongSymbol" "";
BA_DEF_DEF_ "Confidence" "layout-only";
BA_ "SystemSignalLongSymbol" SG_ 1294 CP_a116_temperatureSensorMismatc "CP_a116_temperatureSensorMismatch";
BA_ "SystemSignalLongSymbol" SG_ 798 CP_a112_inletHeaterIrrationalTem "CP_a112_inletHeaterIrrationalTemperature";
BA_ "SystemSignalLongSymbol" SG_ 798 CP_a117_inletHeaterUnableToRegul "CP_a117_inletHeaterUnableToRegulate";
BA_ "SystemSignalLongSymbol" SG_ 798 CP_a162_pilotEdgeDetectionFailed "CP_a162_pilotEdgeDetectionFailedCN";
BA_ "SystemSignalLongSymbol" SG_ 798 CP_a164_latchRedisengageRequeste "CP_a164_latchRedisengageRequested";
BA_ "SystemSignalLongSymbol" SG_ 798 CP_a166_faultLineMismatchDetecte "CP_a166_faultLineMismatchDetected";
BA_ "SystemSignalLongSymbol" SG_ 798 CP_a177_incompatibleV2lDeviceDet "CP_a177_incompatibleV2lDeviceDetected";
BA_ "Confidence" SG_ 669 CP_evseOutputDcCurrent 1;
BA_ "Confidence" SG_ 669 CP_evseOutputDcVoltage 1;
BA_ "Confidence" SG_ 669 CP_evseOutputDcCurrentStale 1;
BA_ "Confidence" SG_ 541 CP_evseAccept 1;
BA_ "Confidence" SG_ 541 CP_evseRequest 1;
BA_ "Confidence" SG_ 541 CP_proximity 1;
BA_ "Confidence" SG_ 541 CP_pilot 1;
BA_ "Confidence" SG_ 541 CP_digitalCommsEstablished 1;
BA_ "Confidence" SG_ 541 CP_pilotCurrent 1;
BA_ "Confidence" SG_ 541 CP_cableType 1;
BA_ "Confidence" SG_ 541 CP_iecPilotState 1;
BA_ "Confidence" SG_ 541 CP_plcSupported 1;
BA_ "Confidence" SG_ 541 CP_cableCurrentLimit 1;
BA_ "Confidence" SG_ 541 CP_teslaSwcanState 1;
BA_ "Confidence" SG_ 541 CP_evseChargeType_UI 1;
BA_ "Confidence" SG_ 541 CP_gbState 1;
BA_ "Confidence" SG_ 541 CP_gbdcStopChargeReason 1;
BA_ "Confidence" SG_ 541 CP_gbdcFailureReason 1;
BA_ "Confidence" SG_ 541 CP_gbdcChargeAttempts 1;
BA_ "Confidence" SG_ 541 CP_acChargeState 1;
BA_ "Confidence" SG_ 541 CP_teslaDcState 1;
BA_ "Confidence" SG_ 1342 CP_buildType 1;
BA_ "Confidence" SG_ 1885 CP_doorOpenActuationTime 1;
BA_ "Confidence" SG_ 1885 CP_doorCloseActuationTime 1;
BA_ "Confidence" SG_ 1885 CP_chargeCableSecured 1;
BA_ "Confidence" SG_ 1885 CP_chargeCablePresent 1;
BA_ "Confidence" SG_ 1885 CP_UHF_controlState 1;
BA_ "Confidence" SG_ 1885 CP_proximityV 1;
BA_ "Confidence" SG_ 1885 CP_proximityV_GBCC1 1;
BA_ "Confidence" SG_ 1885 CP_proximityV_GBCC2 1;
BA_ "Confidence" SG_ 1885 CP_doorPot 1;
BA_ "Confidence" SG_ 1885 CP_doorOpenRequest 1;
BA_ "Confidence" SG_ 1885 CP_doorOpenEndOfDriveReason 1;
BA_ "Confidence" SG_ 1885 CP_doorCloseEndOfDriveReason 1;
BA_ "Confidence" SG_ 1885 CP_doorCloseRequest 1;
BA_ "Confidence" SG_ 1885 CP_latchDisengagingTime 1;
BA_ "Confidence" SG_ 1885 CP_latchEngagingTime 1;
BA_ "Confidence" SG_ 1885 CP_latchDisengagingStopReason 1;
BA_ "Confidence" SG_ 1885 CP_latchEngagingStopReason 1;
BA_ "Confidence" SG_ 1885 CP_doorIdDetectionState 1;
BA_ "Confidence" SG_ 1885 CP_doorIdDetectedBin 1;
BA_ "Confidence" SG_ 2042 CP_UHF_rssi 1;
BA_ "Confidence" SG_ 2042 CP_UHF_selfTestRssi 1;
BA_ "Confidence" SG_ 2042 CP_latchI 1;
BA_ "Confidence" SG_ 2042 CP_inlet1HarnessIdState 1;
BA_ "Confidence" SG_ 2042 CP_inlet1HarnessIdValue 1;
BA_ "Confidence" SG_ 2042 CP_inlet2HarnessIdState 1;
BA_ "Confidence" SG_ 2042 CP_inlet2HarnessIdValue 1;
BA_ "Confidence" SG_ 2042 CP_inletHeaterState 1;
BA_ "Confidence" SG_ 2042 CP_inletHeaterDuty 1;
BA_ "Confidence" SG_ 2042 CP_doorOpenLimiterMaxCount 1;
BA_ "Confidence" SG_ 2042 CP_doorOpenLimiterMaxRequestType 1;
BA_ "Confidence" SG_ 2042 CP_doorCloseLimiterMaxCount 1;
BA_ "Confidence" SG_ 2042 CP_doorCloseLimiterMaxRequestTyp 1;
BA_ "SystemSignalLongSymbol" SG_ 2042 CP_doorCloseLimiterMaxRequestTyp "CP_doorCloseLimiterMaxRequestType";
BA_ "Confidence" SG_ 528 CP_type 1;
BA_ "Confidence" SG_ 528 CP_insertEnableLine 1;
BA_ "Confidence" SG_ 528 CP_latchState 1;
BA_ "Confidence" SG_ 528 CP_chargeDoorOpen 1;
BA_ "Confidence" SG_ 528 CP_doorControlState 1;
BA_ "Confidence" SG_ 528 CP_doorButtonPressed 1;
BA_ "Confidence" SG_ 528 CP_swcanRelayClosed 1;
BA_ "Confidence" SG_ 528 CP_inhibitOta 1;
BA_ "Confidence" SG_ 528 CP_chargeCableState 1;
BA_ "Confidence" SG_ 528 CP_latchControlState 1;
BA_ "Confidence" SG_ 528 CP_ledColor 1;
BA_ "Confidence" SG_ 528 CP_UHF_handleFound 1;
BA_ "Confidence" SG_ 528 CP_faultLineSensed 1;
BA_ "Confidence" SG_ 528 CP_doorPresenceState 1;
BA_ "Confidence" SG_ 528 CP_inductiveSensorState 1;
BA_ "Confidence" SG_ 528 CP_chargeDoorOpenUI 1;
BA_ "Confidence" SG_ 528 CP_vehicleUnlockRequest 1;
BA_ "Confidence" SG_ 528 CP_coldWeatherMode 1;
BA_ "Confidence" SG_ 528 CP_inletHeaterUiState 1;
BA_ "Confidence" SG_ 893 CP_pinTemperature1 1;
BA_ "Confidence" SG_ 893 CP_pinTemperature2 1;
BA_ "Confidence" SG_ 893 CP_pinTemperature3 1;
BA_ "Confidence" SG_ 583 DAS_roadEstimator 1;
BA_ "Confidence" SG_ 583 DAS_arbiterBehavior 1;
BA_ "Confidence" SG_ 583 DAS_mapAvailability 1;
BA_ "Confidence" SG_ 583 DAS_controllerRef 1;
BA_ "Confidence" SG_ 583 DAS_alcInternalState 1;
BA_ "Confidence" SG_ 583 DAS_behaviorReport 1;
BA_ "Confidence" SG_ 583 DAS_controllerHealth 1;
BA_ "Confidence" SG_ 583 DAS_controlDistance 1;
BA_ "Confidence" SG_ 583 DAS_autopilotAbortReason 1;
BA_ "Confidence" SG_ 583 DAS_rqstedBehaviorStatus 1;
BA_ "Confidence" SG_ 583 DAS_forkState 1;
BA_ "Confidence" SG_ 583 DAS_laneChangeState 1;
BA_ "Confidence" SG_ 583 DAS_lastWatchdogCode 1;
BA_ "Confidence" SG_ 1001 DAS_headlightRequest 1;
BA_ "Confidence" SG_ 1001 DAS_hazardLightRequest 1;
BA_ "Confidence" SG_ 1001 DAS_wiperSpeed 1;
BA_ "Confidence" SG_ 1001 DAS_turnIndicatorRequest 1;
BA_ "Confidence" SG_ 1001 DAS_highLowBeamDecision 1;
BA_ "Confidence" SG_ 1001 DAS_heaterRequest 1;
BA_ "Confidence" SG_ 1001 DAS_highLowBeamOffReason 1;
BA_ "Confidence" SG_ 1001 DAS_forwardCamHeaterDutyCycle 1;
BA_ "Confidence" SG_ 1001 DAS_dynamicBrakeLightRequest 1;
BA_ "Confidence" SG_ 1001 DAS_radarHeaterRequest 1;
BA_ "Confidence" SG_ 1001 DAS_ahlbOverride 1;
BA_ "Confidence" SG_ 1001 DAS_mirrorFoldRequest 1;
BA_ "Confidence" SG_ 1001 DAS_wiperWashRequest 1;
BA_ "Confidence" SG_ 1001 DAS_overrideWiperSetting 1;
BA_ "Confidence" SG_ 1001 DAS_autoWiperState 1;
BA_ "Confidence" SG_ 1001 DAS_turnIndicatorRequestReason 1;
BA_ "Confidence" SG_ 1001 DAS_driverDomeLightRequest 1;
BA_ "Confidence" SG_ 1001 DAS_drivePowerStateRequest 1;
BA_ "Confidence" SG_ 1001 DAS_rPillarCamHeaterDutyCycle 1;
BA_ "Confidence" SG_ 1001 DAS_adaptiveHighBeamIsFaulted 1;
BA_ "Confidence" SG_ 1001 DAS_restrictDoorReleaseLeft 1;
BA_ "Confidence" SG_ 1001 DAS_restrictDoorReleaseRight 1;
BA_ "Confidence" SG_ 1497 DAS_radarTarget5_dx 1;
BA_ "Confidence" SG_ 1497 DAS_radarTarget1_dx 1;
BA_ "Confidence" SG_ 1497 DAS_radarTarget1_VxRel 1;
BA_ "Confidence" SG_ 1497 DAS_fcmCollisionStage3Checks 1;
BA_ "Confidence" SG_ 1497 DAS_constructionArea 1;
BA_ "Confidence" SG_ 1497 DAS_restrictionLowSpeedTraffic 1;
BA_ "Confidence" SG_ 1497 DAS_associated_rad_object 1;
BA_ "Confidence" SG_ 1497 DAS_LC_handsOnReason 1;
BA_ "Confidence" SG_ 1497 DAS_ACC_camStatus 1;
BA_ "Confidence" SG_ 1497 DAS_aeb_not_activating_reason 1;
BA_ "Confidence" SG_ 1497 DAS_handsOnDetected 1;
BA_ "Confidence" SG_ 1497 DAS_driveOnNavUnavailableReason 1;
BA_ "Confidence" SG_ 1497 DAS_accUnavailableReason 1;
BA_ "Confidence" SG_ 1497 DAS_pmmNotActivatingReason 1;
BA_ "Confidence" SG_ 1497 DAS_desiredTarget_dx 1;
BA_ "Confidence" SG_ 1497 DAS_radarTarget2_dx 1;
BA_ "Confidence" SG_ 1497 DAS_radarTarget3_dx 1;
BA_ "Confidence" SG_ 1497 DAS_radarTarget4_dx 1;
BA_ "Confidence" SG_ 1497 DAS_closestInLaneTargetDx 1;
BA_ "Confidence" SG_ 1497 DAS_secondInLaneTargetDx 1;
BA_ "Confidence" SG_ 1497 DAS_closestLeftLaneTargetDx 1;
BA_ "Confidence" SG_ 1497 DAS_closestRightLaneTargetDx 1;
BA_ "Confidence" SG_ 1497 DAS_closestInLaneTargetVxRel 1;
BA_ "Confidence" SG_ 697 DAS_setSpeed 1;
BA_ "Confidence" SG_ 697 DAS_accState 1;
BA_ "Confidence" SG_ 697 DAS_aebEvent 1;
BA_ "Confidence" SG_ 697 DAS_jerkMin 1;
BA_ "Confidence" SG_ 697 DAS_jerkMax 1;
BA_ "Confidence" SG_ 697 DAS_accelMin 1;
BA_ "Confidence" SG_ 697 DAS_accelMax 1;
BA_ "Confidence" SG_ 2041 DAS_gpsTransportModeState 1;
BA_ "Confidence" SG_ 2041 DAS_gpsSatsInUseHardware 1;
BA_ "Confidence" SG_ 2041 DAS_gpsRejectingSatData 1;
BA_ "Confidence" SG_ 2041 DAS_gpsWheelsOffMotionDetected 1;
BA_ "Confidence" SG_ 2041 DAS_gpsFixTypeHardware 1;
BA_ "Confidence" SG_ 2041 DAS_gpsRawxEnabled 1;
BA_ "Confidence" SG_ 2041 DAS_gpsEsfMeasMia 1;
BA_ "Confidence" SG_ 2041 DAS_gpsEsfRawMia 1;
BA_ "Confidence" SG_ 2041 DAS_gpsNavStatusMia 1;
BA_ "Confidence" SG_ 2041 DAS_gpsSoftwareConfigured 1;
BA_ "Confidence" SG_ 2041 DAS_gpsSoftwareUsed 1;
BA_ "Confidence" SG_ 2041 DAS_gpsSoftwareFastStartReady 1;
BA_ "Confidence" SG_ 2041 DAS_gpsSatsInUseSoftware 1;
BA_ "Confidence" SG_ 2041 DAS_gpsFixTypeSoftware 1;
BA_ "Confidence" SG_ 2041 DAS_gpsCWJammingInidcator 1;
BA_ "Confidence" SG_ 2041 DAS_gpsJammingState 1;
BA_ "Confidence" SG_ 2041 DAS_gpsSpoofDetectorState 1;
BA_ "Confidence" SG_ 2041 DAS_gpsInvalidMsgPercentage 1;
BA_ "Confidence" SG_ 2041 DAS_gnssConstellationsState 1;
BA_ "Confidence" SG_ 2041 DAS_gpsReceiverNoiseLevel 1;
BA_ "Confidence" SG_ 2041 DAS_gpsAutomaticGainControl 1;
BA_ "Confidence" SG_ 2041 DAS_gpsPreviousPositionDeltaHw 1;
BA_ "Confidence" SG_ 2041 DAS_gpsPreviousPositionDeltaSw 1;
BA_ "Confidence" SG_ 2041 DAS_gpsNmeaDispatchFailureCount 1;
BA_ "Confidence" SG_ 2041 DAS_gnssMaxInstantaneousCnorGps 1;
BA_ "Confidence" SG_ 2041 DAS_gnssMaxInstantaneousCnorGal 1;
BA_ "Confidence" SG_ 2041 DAS_gnssMaxInstantaneousCnorBds 1;
BA_ "Confidence" SG_ 2041 DAS_gpsResetReason 1;
BA_ "Confidence" SG_ 2041 DAS_gpsAccuracyHorizontal 1;
BA_ "Confidence" SG_ 2041 DAS_gpsAccuracyVertical 1;
BA_ "Confidence" SG_ 2041 DAS_gpsSolutionFallback 1;
BA_ "Confidence" SG_ 2041 DAS_gpsToMcuSource 1;
BA_ "Confidence" SG_ 2041 DAS_gpsSolutionSoc 1;
BA_ "Confidence" SG_ 2041 DAS_gpsRedundancyActive 1;
BA_ "Confidence" SG_ 2041 DAS_gpsFixTypeSoftwareSocB 1;
BA_ "Confidence" SG_ 2041 DAS_gpsSatsInUseSoftwareSocB 1;
BA_ "Confidence" SG_ 2041 DAS_gnssNumSatsGps 1;
BA_ "Confidence" SG_ 2041 DAS_gnssNumSatsGal 1;
BA_ "Confidence" SG_ 2041 DAS_gnssNumSatsBds 1;
BA_ "Confidence" SG_ 2041 DAS_gnssAvgInstantaneousCnorGps 1;
BA_ "Confidence" SG_ 2041 DAS_gnssAvgInstantaneousCnorGal 1;
BA_ "Confidence" SG_ 2041 DAS_gnssAvgInstantaneousCnorBds 1;
BA_ "Confidence" SG_ 2041 DAS_gnssAvgInstantaneousCnorGpsL 1;
BA_ "SystemSignalLongSymbol" SG_ 2041 DAS_gnssAvgInstantaneousCnorGpsL "DAS_gnssAvgInstantaneousCnorGpsLowBand";
BA_ "Confidence" SG_ 2041 DAS_gnssAvgInstantaneousCnorGalL 1;
BA_ "SystemSignalLongSymbol" SG_ 2041 DAS_gnssAvgInstantaneousCnorGalL "DAS_gnssAvgInstantaneousCnorGalLowBand";
BA_ "Confidence" SG_ 2041 DAS_gnssAvgInstantaneousCnorBdsL 1;
BA_ "SystemSignalLongSymbol" SG_ 2041 DAS_gnssAvgInstantaneousCnorBdsL "DAS_gnssAvgInstantaneousCnorBdsLowBand";
BA_ "Confidence" SG_ 1337 DAS_infoBuildType 1;
BA_ "Confidence" SG_ 569 DAS_virtualLaneWidth 1;
BA_ "Confidence" SG_ 569 DAS_virtualLaneViewRange 1;
BA_ "Confidence" SG_ 569 DAS_virtualLaneC0 1;
BA_ "Confidence" SG_ 569 DAS_virtualLaneC1 1;
BA_ "Confidence" SG_ 569 DAS_virtualLaneC2 1;
BA_ "Confidence" SG_ 569 DAS_virtualLaneC3 1;
BA_ "Confidence" SG_ 569 DAS_leftLineUsage 1;
BA_ "Confidence" SG_ 569 DAS_rightLineUsage 1;
BA_ "Confidence" SG_ 569 DAS_leftFork 1;
BA_ "Confidence" SG_ 569 DAS_rightFork 1;
BA_ "Confidence" SG_ 777 DAS_leadVehType 1;
BA_ "Confidence" SG_ 777 DAS_leadVehDx 1;
BA_ "Confidence" SG_ 777 DAS_leadVehVxRel 1;
BA_ "Confidence" SG_ 777 DAS_leadVehDy 1;
BA_ "Confidence" SG_ 777 DAS_leadVeh2Type 1;
BA_ "Confidence" SG_ 777 DAS_leadVeh2Dx 1;
BA_ "Confidence" SG_ 777 DAS_leadVeh2VxRel 1;
BA_ "Confidence" SG_ 777 DAS_leadVeh2Dy 1;
BA_ "Confidence" SG_ 777 DAS_leftVehType 1;
BA_ "Confidence" SG_ 777 DAS_leftVehDx 1;
BA_ "Confidence" SG_ 777 DAS_leftVehVxRel 1;
BA_ "Confidence" SG_ 777 DAS_leftVehDy 1;
BA_ "Confidence" SG_ 777 DAS_leftVeh2Type 1;
BA_ "Confidence" SG_ 777 DAS_leftVeh2Dx 1;
BA_ "Confidence" SG_ 777 DAS_leftVeh2VxRel 1;
BA_ "Confidence" SG_ 777 DAS_leftVeh2Dy 1;
BA_ "Confidence" SG_ 777 DAS_rightVehType 1;
BA_ "Confidence" SG_ 777 DAS_rightVehDx 1;
BA_ "Confidence" SG_ 777 DAS_rightVehVxRel 1;
BA_ "Confidence" SG_ 777 DAS_rightVehDy 1;
BA_ "Confidence" SG_ 777 DAS_rightVeh2Type 1;
BA_ "Confidence" SG_ 777 DAS_rightVeh2Dx 1;
BA_ "Confidence" SG_ 777 DAS_rightVeh2VxRel 1;
BA_ "Confidence" SG_ 777 DAS_rightVeh2Dy 1;
BA_ "Confidence" SG_ 777 DAS_cutinVehType 1;
BA_ "Confidence" SG_ 777 DAS_cutinVehDx 1;
BA_ "Confidence" SG_ 777 DAS_cutinVehVxRel 1;
BA_ "Confidence" SG_ 777 DAS_cutinVehDy 1;
BA_ "Confidence" SG_ 777 DAS_roadSignColor 1;
BA_ "Confidence" SG_ 777 DAS_roadSignId 1;
BA_ "Confidence" SG_ 777 DAS_roadSignStopLineDist 1;
BA_ "Confidence" SG_ 777 DAS_roadSignSource 1;
BA_ "Confidence" SG_ 777 DAS_roadSignArrow 1;
BA_ "Confidence" SG_ 777 DAS_roadSignOrientation 1;
VAL_ 541 CP_proximity 3 "CHG_PROXIMITY_LATCHED" 2 "CHG_PROXIMITY_UNLATCHED" 1 "CHG_PROXIMITY_DISCONNECTED" 0 "CHG_PROXIMITY_SNA" ;
VAL_ 541 CP_pilot 7 "CHG_PILOT_SNA" 6 "CHG_PILOT_UNUSED_6" 5 "CHG_PILOT_INVALID" 4 "CHG_PILOT_IDLE" 3 "CHG_PILOT_FAST_CHARGE" 2 "CHG_PILOT_LINE_CHARGE" 1 "CHG_PILOT_FAULTED" 0 "CHG_PILOT_NONE" ;
VAL_ 541 CP_cableType 5 "CHG_CABLE_TYPE_SNA" 4 "CHG_CABLE_TYPE_MCS" 3 "CHG_CABLE_TYPE_GB_DC" 2 "CHG_CABLE_TYPE_GB_AC" 1 "CHG_CABLE_TYPE_SAE" 0 "CHG_CABLE_TYPE_IEC" ;
VAL_ 541 CP_iecPilotState 9 "IEC_PILOT_SNA" 8 "IEC_PILOT_NUM" 7 "IEC_PILOT_F" 6 "IEC_PILOT_E" 5 "IEC_PILOT_C3" 4 "IEC_PILOT_C2" 3 "IEC_PILOT_C1" 2 "IEC_PILOT_B3" 1 "IEC_PILOT_B2" 0 "IEC_PILOT_B1" ;
VAL_ 541 CP_teslaSwcanState 8 "TESLA_SWCAN_V2L_ESTABLISHED" 7 "TESLA_SWCAN_V2L_RECEIVE" 6 "TESLA_SWCAN_OFFBOARD_UPDATE_IN_PROGRESS" 5 "TESLA_SWCAN_GO_TO_SLEEP" 4 "TESLA_SWCAN_FAULT" 3 "TESLA_SWCAN_ESTABLISHED" 2 "TESLA_SWCAN_RECEIVE" 1 "TESLA_SWCAN_ACCEPT" 0 "TESLA_SWCAN_INACTIVE" ;
VAL_ 541 CP_evseChargeType_UI 2 "AC_CHARGER_PRESENT" 1 "DC_CHARGER_PRESENT" 0 "NO_CHARGER_PRESENT" ;
VAL_ 541 CP_gbState 15 "GBDC_TESTER_PRESENT" 14 "GBDC_FAULTED" 13 "GBDC_RETRY_CHARGE" 12 "GBDC_ERROR_HANDLING" 11 "GBDC_END_OF_CHARGE" 10 "GBDC_CHARGE_DISABLING" 9 "GBDC_STOP_CHARGE_REQUESTED" 8 "GBDC_CHARGING" 7 "GBDC_READY_TO_CHARGE" 6 "GBDC_VEH_PACK_PRECHARGE" 5 "GBDC_CHARGE_PARAM_CONFIG" 4 "GBDC_RECOGNITION" 3 "GBDC_HANDSHAKING_EXT_ISO" 2 "GBDC_COMMS_RECEIVED" 1 "GBDC_WAIT_FOR_COMMS" 0 "GBDC_INACTIVE" ;
VAL_ 541 CP_gbdcStopChargeReason 8 "GBDC_PARAM_MISMATCH" 7 "GBDC_SUPERCHARGER_COMMS_TIMEOUT" 6 "GBDC_LIVE_DISCONNECT" 5 "GBDC_EVSE_CRITICAL_FAULT" 4 "GBDC_EVSE_FAULT" 3 "GBDC_COMMS_TIMEOUT" 2 "GBDC_EVSE_REQUESTED" 1 "GBDC_VEH_REQUESTED" 0 "GBDC_STOP_REASON_NONE" ;
VAL_ 541 CP_gbdcFailureReason 3 "GBDC_CRITICAL_FAILURE" 2 "GBDC_SHUTDOWN_FAILURE" 1 "GBDC_ATTEMPTS_EXPIRED" 0 "GBDC_FAILURE_NONE" ;
VAL_ 541 CP_acChargeState 6 "AC_CHARGE_FAULT" 5 "AC_CHARGE_VEH_SHUTDOWN" 4 "AC_CHARGE_ONBOARD_CHARGER_SHUTDOWN" 3 "AC_CHARGE_ENABLED" 2 "AC_CHARGE_STANDBY" 1 "AC_CHARGE_CONNECTED_CHARGE_BLOCKED" 0 "AC_CHARGE_INACTIVE" ;
VAL_ 541 CP_teslaDcState 10 "TESLA_DC_FAULT" 9 "TESLA_DC_EMERGENCY_SHUTDOWN" 8 "TESLA_DC_VEH_SHUTDOWN" 7 "TESLA_DC_EVSE_SHUTDOWN" 6 "TESLA_DC_ENABLED" 5 "TESLA_DC_EXT_PRECHARGE_ACTIVE" 4 "TESLA_DC_EXT_TEST_ACTIVE" 3 "TESLA_DC_EXT_TESTS_ENABLED" 2 "TESLA_DC_STANDBY" 1 "TESLA_DC_CONNECTED_CHARGE_BLOCKED" 0 "TESLA_DC_INACTIVE" ;
VAL_ 1342 CP_buildType 4 "INFO_MFG_BUILD" 3 "INFO_TRACEABLE_CI_BUILD" 2 "INFO_LOCAL_BUILD" 1 "INFO_PLATFORM_BUILD" 0 "INFO_UNKNOWN_BUILD" ;
VAL_ 1885 CP_chargeCablePresent 1 "CABLE_PRESENT" 0 "CABLE_NOT_PRESENT" ;
VAL_ 1885 CP_UHF_controlState 10 "CP_UHF_FAULT" 9 "CP_UHF_SLEEP" 8 "CP_UHF_HANDLE_FOUND" 7 "CP_UHF_READ_RXFIFO" 6 "CP_UHF_CHECK_RX" 5 "CP_UHF_RX" 4 "CP_UHF_PREPARE_RX" 3 "CP_UHF_CALIBRATE" 2 "CP_UHF_IDLE" 1 "CP_UHF_CONFIG" 0 "CP_UHF_INIT" ;
VAL_ 1885 CP_doorOpenRequest 8 "CPD_OPEN_REQ_NUM" 7 "CPD_OPEN_REQ_CABLE_RECONNECTED" 6 "CPD_OPEN_REQ_VCFRONT" 5 "CPD_OPEN_REQ_CLOSING_FAILED" 4 "CPD_OPEN_REQ_PUSH_TO_OPEN" 3 "CPD_OPEN_REQ_UHF" 2 "CPD_OPEN_REQ_SEC" 1 "CPD_OPEN_REQ_UI" 0 "CPD_OPEN_REQ_NONE" ;
VAL_ 1885 CP_doorOpenEndOfDriveReason 7 "CP_STOP_DRIVE_REASON_OVERCURRENT" 6 "CP_STOP_DRIVE_REASON_REQ_OVERRIDE" 5 "CP_STOP_DRIVE_REASON_ABSOLUTE_TIMEOUT" 4 "CP_STOP_DRIVE_REASON_MAX_TARGET_V" 3 "CP_STOP_DRIVE_REASON_REACHED_STOP" 2 "CP_STOP_DRIVE_REASON_STOPPED_MOVING_TIMEOUT" 1 "CP_STOP_DRIVE_REASON_STALLED" 0 "CP_STOP_DRIVE_REASON_NONE" ;
VAL_ 1885 CP_doorCloseEndOfDriveReason 7 "CP_STOP_DRIVE_REASON_OVERCURRENT" 6 "CP_STOP_DRIVE_REASON_REQ_OVERRIDE" 5 "CP_STOP_DRIVE_REASON_ABSOLUTE_TIMEOUT" 4 "CP_STOP_DRIVE_REASON_MAX_TARGET_V" 3 "CP_STOP_DRIVE_REASON_REACHED_STOP" 2 "CP_STOP_DRIVE_REASON_STOPPED_MOVING_TIMEOUT" 1 "CP_STOP_DRIVE_REASON_STALLED" 0 "CP_STOP_DRIVE_REASON_NONE" ;
VAL_ 1885 CP_doorCloseRequest 16 "CPD_CLOSE_REQ_NUM" 15 "CPD_CLOSE_REQ_COVER_OPEN" 14 "CPD_CLOSE_REQ_VCFRONT" 13 "CPD_CLOSE_REQ_OPEN_ON_WAKE" 12 "CPD_CLOSE_REQ_SENSOR_COMMS_RECOVERED" 11 "CPD_CLOSE_REQ_SENSOR_MISMATCH" 10 "CPD_CLOSE_REQ_INITIAL_CINCH" 9 "CPD_CLOSE_REQ_OPENED_IN_DRIVE_STATE" 8 "CPD_CLOSE_REQ_ENTER_DRIVE" 7 "CPD_CLOSE_REQ_FAULT_LINE" 6 "CPD_CLOSE_REQ_CAR_WASH" 5 "CPD_CLOSE_REQ_PUSH_TO_CLOSE" 4 "CPD_CLOSE_REQ_SEC" 3 "CPD_CLOSE_REQ_UI" 2 "CPD_CLOSE_REQ_DOOR_OPEN_TIMEOUT" 1 "CPD_CLOSE_REQ_CABLE_UNPLUGGED" 0 "CPD_CLOSE_REQ_NONE" ;
VAL_ 1885 CP_latchDisengagingStopReason 7 "CP_STOP_DRIVE_REASON_OVERCURRENT" 6 "CP_STOP_DRIVE_REASON_REQ_OVERRIDE" 5 "CP_STOP_DRIVE_REASON_ABSOLUTE_TIMEOUT" 4 "CP_STOP_DRIVE_REASON_MAX_TARGET_V" 3 "CP_STOP_DRIVE_REASON_REACHED_STOP" 2 "CP_STOP_DRIVE_REASON_STOPPED_MOVING_TIMEOUT" 1 "CP_STOP_DRIVE_REASON_STALLED" 0 "CP_STOP_DRIVE_REASON_NONE" ;
VAL_ 1885 CP_latchEngagingStopReason 7 "CP_STOP_DRIVE_REASON_OVERCURRENT" 6 "CP_STOP_DRIVE_REASON_REQ_OVERRIDE" 5 "CP_STOP_DRIVE_REASON_ABSOLUTE_TIMEOUT" 4 "CP_STOP_DRIVE_REASON_MAX_TARGET_V" 3 "CP_STOP_DRIVE_REASON_REACHED_STOP" 2 "CP_STOP_DRIVE_REASON_STOPPED_MOVING_TIMEOUT" 1 "CP_STOP_DRIVE_REASON_STALLED" 0 "CP_STOP_DRIVE_REASON_NONE" ;
VAL_ 1885 CP_doorIdDetectionState 2 "DOOR_ID_VALID" 1 "DOOR_ID_INVALID" 0 "DOOR_ID_UNKNOWN_SNA" ;
VAL_ 1885 CP_doorIdDetectedBin 3 "DOOR_ID_BIN_OPAL" 2 "DOOR_ID_BIN_HMC" 1 "DOOR_ID_BIN_NMB" 0 "DOOR_ID_BIN_UNKNOWN" ;
VAL_ 2042 CP_inlet1HarnessIdState 2 "HARNESS_PEDIGREE_VALID" 1 "HARNESS_PEDIGREE_INVALID" 0 "HARNESS_PEDIGREE_UNKNOWN_SNA" ;
VAL_ 2042 CP_inlet2HarnessIdState 2 "HARNESS_PEDIGREE_VALID" 1 "HARNESS_PEDIGREE_INVALID" 0 "HARNESS_PEDIGREE_UNKNOWN_SNA" ;
VAL_ 2042 CP_inletHeaterState 3 "INLET_HEATER_FAULTED" 2 "INLET_HEATER_ENABLED_LOWTEMP" 1 "INLET_HEATER_ENABLED_HIGHTEMP" 0 "INLET_HEATER_DISABLED" ;
VAL_ 2042 CP_doorOpenLimiterMaxRequestType 8 "CPD_OPEN_REQ_NUM" 7 "CPD_OPEN_REQ_CABLE_RECONNECTED" 6 "CPD_OPEN_REQ_VCFRONT" 5 "CPD_OPEN_REQ_CLOSING_FAILED" 4 "CPD_OPEN_REQ_PUSH_TO_OPEN" 3 "CPD_OPEN_REQ_UHF" 2 "CPD_OPEN_REQ_SEC" 1 "CPD_OPEN_REQ_UI" 0 "CPD_OPEN_REQ_NONE" ;
VAL_ 2042 CP_doorCloseLimiterMaxRequestTyp 16 "CPD_CLOSE_REQ_NUM" 15 "CPD_CLOSE_REQ_COVER_OPEN" 14 "CPD_CLOSE_REQ_VCFRONT" 13 "CPD_CLOSE_REQ_OPEN_ON_WAKE" 12 "CPD_CLOSE_REQ_SENSOR_COMMS_RECOVERED" 11 "CPD_CLOSE_REQ_SENSOR_MISMATCH" 10 "CPD_CLOSE_REQ_INITIAL_CINCH" 9 "CPD_CLOSE_REQ_OPENED_IN_DRIVE_STATE" 8 "CPD_CLOSE_REQ_ENTER_DRIVE" 7 "CPD_CLOSE_REQ_FAULT_LINE" 6 "CPD_CLOSE_REQ_CAR_WASH" 5 "CPD_CLOSE_REQ_PUSH_TO_CLOSE" 4 "CPD_CLOSE_REQ_SEC" 3 "CPD_CLOSE_REQ_UI" 2 "CPD_CLOSE_REQ_DOOR_OPEN_TIMEOUT" 1 "CPD_CLOSE_REQ_CABLE_UNPLUGGED" 0 "CPD_CLOSE_REQ_NONE" ;
VAL_ 528 CP_type 3 "CP_TYPE_IEC_CCS" 2 "CP_TYPE_GB" 1 "CP_TYPE_EURO_IEC" 0 "CP_TYPE_US_TESLA" ;
VAL_ 528 CP_latchState 3 "CP_LATCH_BLOCKING" 2 "CP_LATCH_ENGAGED" 1 "CP_LATCH_DISENGAGED" 0 "CP_LATCH_SNA" ;
VAL_ 528 CP_doorControlState 6 "CP_doorSenseClosed" 5 "CP_doorClosing" 4 "CP_doorSenseOpen" 3 "CP_doorOpening" 2 "CP_doorOpenRequested" 1 "CP_doorIdle" 0 "CP_doorInit" ;
VAL_ 528 CP_chargeCableState 2 "CHARGE_CABLE_CONNECTED" 1 "CHARGE_CABLE_NOT_CONNECTED" 0 "CHARGE_CABLE_UNKNOWN_SNA" ;
VAL_ 528 CP_latchControlState 5 "CP_latchEngaging" 4 "CP_latchDisengaged" 3 "CP_latchDisengaging" 2 "CP_latchDisengageRequested" 1 "CP_latchIdle" 0 "CP_latchInit" ;
VAL_ 528 CP_ledColor 13 "CP_LEDS_FLASHING_WHITE" 12 "CP_LEDS_FADING_OUT" 11 "CP_LEDS_FLASHING_PURPLE" 10 "CP_LEDS_FLASHING_BLUE" 9 "CP_LEDS_DEBUG" 8 "CP_LEDS_RAVE" 7 "CP_LEDS_AMBER" 6 "CP_LEDS_FLASHING_AMBER" 5 "CP_LEDS_FLASHING_GREEN" 4 "CP_LEDS_WHITE" 3 "CP_LEDS_BLUE" 2 "CP_LEDS_GREEN" 1 "CP_LEDS_RED" 0 "CP_LEDS_OFF" ;
VAL_ 528 CP_faultLineSensed 1 "FAULT_LINE_SET" 0 "FAULT_LINE_CLEARED" ;
VAL_ 528 CP_doorPresenceState 7 "CP_DOOR_PRESENCE_STATE_FAULT" 6 "CP_DOOR_PRESENCE_STATE_OFF_CHARGE" 5 "CP_DOOR_PRESENCE_STATE_OFF_DRIVE" 4 "CP_DOOR_PRESENCE_STATE_NOT_PRESENT" 3 "CP_DOOR_PRESENCE_STATE_PRESENT" 2 "CP_DOOR_PRESENCE_STATE_INIT_FROM_DRIVE" 1 "CP_DOOR_PRESENCE_STATE_INIT_FROM_CHARGE" 0 "CP_DOOR_PRESENCE_STATE_INIT" ;
VAL_ 528 CP_inductiveSensorState 7 "CP_INDUCTIVE_SENSOR_CONFIG" 6 "CP_INDUCTIVE_SENSOR_RESET" 5 "CP_INDUCTIVE_SENSOR_FAULT" 4 "CP_INDUCTIVE_SENSOR_WAIT_FOR_INIT" 3 "CP_INDUCTIVE_SENSOR_PAUSE" 2 "CP_INDUCTIVE_SENSOR_SHUTDOWN" 1 "CP_INDUCTIVE_SENSOR_POLL" 0 "CP_INDUCTIVE_SENSOR_INIT" ;
VAL_ 528 CP_coldWeatherMode 1 "CP_COLD_WEATHER_LATCH_MITIGATION" 0 "CP_COLD_WEATHER_NONE" ;
VAL_ 528 CP_inletHeaterUiState 4 "CP_HEATER_FAULTED" 3 "CP_HEATER_ENABLED" 2 "CP_HEATER_AVAILABLE" 1 "CP_HEATER_NOT_AVAILABLE" 0 "CP_HEATER_NOT_SUPPORTED" ;
VAL_ 583 DAS_roadEstimator 3 "ROAD_ESTIMATOR_CRITICAL" 2 "ROAD_ESTIMATOR_DEGRADED" 1 "ROAD_ESTIMATOR_UNSTABLE_MEASUREMENTS" 0 "ROAD_ESTIMATOR_HEALTHY" ;
VAL_ 583 DAS_arbiterBehavior 4 "ARBITER_CITY_STREETS" 3 "ARBITER_LANE_CHANGE_RIGHT" 2 "ARBITER_LANE_CHANGE_LEFT" 1 "ARBITER_IN_LANE" 0 "ARBITER_INVALID" ;
VAL_ 583 DAS_mapAvailability 1 "APM_MAP_AVAILABLE" 0 "APM_MAP_NOT_AVAILABLE" ;
VAL_ 583 DAS_controllerRef 6 "CONTROLLER_REFERENCE_INDETERMINATE" 5 "CONTROLLER_REFERENCE_REF_TOO_SHORT" 4 "CONTROLLER_REFERENCE_BAD_REF_UPDATE" 3 "CONTROLLER_REFERENCE_STALE_LOCALIZATION" 2 "CONTROLLER_REFERENCE_STALE_REFERENCE" 1 "CONTROLLER_REFERENCE_UNHEALTHY" 0 "CONTROLLER_REFERENCE_HEALTHY" ;
VAL_ 583 DAS_alcInternalState 12 "ALC_RETRY" 11 "ALC_SOFT_ABORTING_RIGHT" 10 "ALC_SOFT_ABORTING_LEFT" 9 "ALC_ACTIVE_ACC_RIGHT" 8 "ALC_ACTIVE_ACC_LEFT" 7 "ALC_ACTIVE_RIGHT" 6 "ALC_ACTIVE_LEFT" 5 "ALC_PRE_ACTIVE_RIGHT" 4 "ALC_PRE_ACTIVE_LEFT" 3 "ALC_BEHAVIOR_CHECK" 2 "ALC_ABORTING" 1 "ALC_IDLE" 0 "ALC_DISABLED" ;
VAL_ 583 DAS_behaviorReport 71 "BEHAVIOR_MAX_SPEED_IN_REVERSE" 70 "BEHAVIOR_STOPPING_FOR_GEAR_CHANGE" 69 "BEHAVIOR_ROAD_SPEED" 68 "BEHAVIOR_CAMERA_FAILSAFES" 67 "BEHAVIOR_CAUTION_LIGHTS" 66 "BEHAVIOR_DRY_STEERING" 65 "BEHAVIOR_CREEP_FOR_SHORT_REF" 64 "BEHAVIOR_FAILED_LANE_CHANGE" 63 "BEHAVIOR_AHB_MANUAL_OVERRIDE" 62 "BEHAVIOR_FORWARD_LATERAL_OBJECT" 61 "BEHAVIOR_POOR_VISIBILITY" 60 "BEHAVIOR_MAIN_CAMERA_SUN_GLARE" 59 "BEHAVIOR_CITY_MERGE_OBJECT" 58 "BEHAVIOR_TRAJECTORY_OUTLIER_PRESSURE" 57 "BEHAVIOR_REFERENCE_LENGTH" 56 "BEHAVIOR_PATH_BLOCKED_BEYOND_TRAJ" 55 "BEHAVIOR_PATH_BLOCKED" 54 "BEHAVIOR_UNSUPPORTED_MANEUVER" 53 "BEHAVIOR_CROSSING_OBJECT" 52 "BEHAVIOR_CLEAR_TO_GO" 51 "BEHAVIOR_APPROACHING_TURN" 50 "BEHAVIOR_DYNAMIC_PINCH_POINT" 49 "BEHAVIOR_VANISHING_CIPV_KEEP_CALM" 48 "BEHAVIOR_ONRAMP_BOOST" 47 "BEHAVIOR_TRAFFIC_CONTROL_LAUNCH" 46 "BEHAVIOR_NARROW_CORRIDOR" 45 "BEHAVIOR_SPEED_BUMP" 44 "BEHAVIOR_SUGGESTED_VISION_SPEED" 43 "BEHAVIOR_ROUNDABOUT" 42 "BEHAVIOR_TOLLBOOTH" 41 "BEHAVIOR_CROSS_TRAFFIC_AVOIDANCE" 40 "BEHAVIOR_CROSSWALK" 39 "BEHAVIOR_RELEVANT_VRU" 38 "BEHAVIOR_RISK_MANAGER" 37 "BEHAVIOR_STATIC_OBJECT_MERGE_RIGHT" 36 "BEHAVIOR_STATIC_OBJECT_MERGE_LEFT" 35 "BEHAVIOR_CUTIN_VEHICLE" 34 "BEHAVIOR_STATIC_OBJECT" 33 "BEHAVIOR_LANE_SPEED_DIFF" 32 "BEHAVIOR_END_OF_NAV_ROUTE" 31 "BEHAVIOR_STEERING_SATURATED" 30 "BEHAVIOR_ACTIVE_SAFETY_SLOWDOWN" 29 "BEHAVIOR_MP_AP_INACTIVE" 28 "BEHAVIOR_MP_ULC" 27 "BEHAVIOR_MP_DI_CRUISE" 26 "BEHAVIOR_MP_AP_STATE_MACHINE" 25 "BEHAVIOR_MP_DRIVER_MONITOR" 24 "BEHAVIOR_MP_NOT_BUCKLED" 23 "BEHAVIOR_MP_AP_RESTRICTION" 22 "BEHAVIOR_CUTIN_VEHICLE_RIGHT" 21 "BEHAVIOR_CUTIN_VEHICLE_LEFT" 20 "BEHAVIOR_MERGE_VEHICLE_RIGHT" 19 "BEHAVIOR_MERGE_VEHICLE_LEFT" 18 "BEHAVIOR_NAV_PATH_CSA" 17 "BEHAVIOR_NAV_FLEET_SPEEDS" 16 "BEHAVIOR_VISION_SPEEDS" 15 "BEHAVIOR_SLOWING_FOR_TARGET_LANE" 14 "BEHAVIOR_DRIVABLE_SPACE_VIOLATION" 13 "BEHAVIOR_MAP_LANE_GEOMETRY" 12 "BEHAVIOR_VISION_LANE_GEOMETRY" 11 "BEHAVIOR_TRAFFIC_CONTROL" 10 "BEHAVIOR_UNDERTAKE_VEHICLE" 9 "BEHAVIOR_TARGET_LANE_VEHICLE" 8 "BEHAVIOR_IN_LANE_VEHICLE" 7 "BEHAVIOR_UNDERTAKE_ASSIST_KEEP_CALM" 6 "BEHAVIOR_TRAFFIC_CONTROL_STOPPED_STATE" 5 "BEHAVIOR_FLEET_SPEEDS" 4 "BEHAVIOR_KEEP_CALM" 3 "BEHAVIOR_RADAR_ONLY_BRAKING" 2 "BEHAVIOR_CURVE_SPEED_ADAPTATION" 1 "BEHAVIOR_VIEW_RANGE" ;
VAL_ 583 DAS_controllerHealth 3 "CONTROLLER_SOLVER_FAILURE" 2 "CONTROLLER_CRITICAL" 1 "CONTROLLER_DEGRADED" 0 "CONTROLLER_HEALTHY" ;
VAL_ 583 DAS_autopilotAbortReason 255 "ABORT_REASON_MAX" 80 "ABORT_DRIVER_SEAT_TRAVEL" 79 "ABORT_DRIVER_OCCLUDED_DISTRACTED" 78 "ABORT_DRIVER_REACHING_DISTRACTED" 77 "ABORT_LOW_CABIN_ILLUMINANCE" 76 "ABORT_CABIN_CAM_OCCLUSION_DNP" 75 "ABORT_DRIVER_OCCLUDED" 74 "ABORT_DRIVER_NOT_DETECTED_SELFIE" 73 "ABORT_DRIVER_E2E_UNKNOWN" 72 "ABORT_DRIVER_EMPTY_SEAT" 71 "ABORT_DRIVER_SEAT_RECLINED" 70 "ABORT_FSD_REGION_NOT_ALLOWED" 69 "ABORT_FERRY_CROSSING" 68 "ABORT_DOOR_OPEN" 67 "ABORT_FRUNK_OPEN" 66 "ABORT_TRUNK_OPEN" 65 "ABORT_CABIN_CAM_ISSUE" 64 "ABORT_TASK_FLOW_TRACE_TIMEOUT" 63 "ABORT_SEALED_MERGE_CROSSING" 62 "ABORT_FSD_GEOFENCE_DISABLED" 61 "ABORT_EXTENDED_COMPUTE_INACTIVE_PCIE_LINK_HEALTH" 60 "ABORT_EXTENDED_COMPUTE_INACTIVE_ETHERNET_LINK_HEALTH" 59 "ABORT_EXTENDED_COMPUTE_INACTIVE_OTHER_SOC_HEALTH_CRITICAL" 58 "ABORT_EXTENDED_COMPUTE_INACTIVE_OTHER_SOC_HEALTH_UNKNOWN" 57 "ABORT_CABIN_CAM_BLIND" 56 "ABORT_AHB_MANUAL_OVERRIDE" 55 "ABORT_DRIVER_NOT_PRESENT" 54 "ABORT_PERCEPTION_HEALTH_STALE" 53 "ABORT_PERCEPTION_HEALTH_POST_PROCESSING" 52 "ABORT_EXTENDED_COMPUTE_INACTIVE" 51 "ABORT_CITY_STREETS_REF_TOO_SHORT" 50 "ABORT_INVALID_BEHAVIOR" 49 "ABORT_ONCOMING_LANE" 48 "ABORT_HEADLIGHT_OFF_AT_NIGHT" 47 "ABORT_IBOOSTER_MIA" 46 "ABORT_INTEGRATOR_HEALTH_CRITICAL" 45 "ABORT_USER_OVERRIDE_STRIKEOUT" 44 "ABORT_SEATBELT_UNBUCKLED" 43 "ABORT_PERCEPTION_HEALTH_VISION" 42 "ABORT_INVALID_VEHICLE_SPEED" 41 "ABORT_INVALID_DI_PEDAL_POS" 40 "ABORT_W048_FEATURES_DISABLED" 39 "ABORT_EPAS_STEERING_ANGLE_INVALID" 38 "ABORT_STEERING_SATURATED_LANE_DEPARTURE" 37 "ABORT_REACHED_END_OF_NAV_STOP" 36 "ABORT_GORE_INCURSION" 35 "ABORT_MISSION_PLANNER_NO_VISION_LANES_FOUND" 34 "ABORT_CONTROLLER_REF_TOO_SHORT" 33 "ABORT_AEB" 32 "ABORT_CONTROLLER_BAD_REF_UPDATE" 31 "ABORT_CONTROLLER_STALE_LOCALIZATION" 30 "ABORT_CONTROLLER_STALE_REFERENCE" 29 "ABORT_MAP_HEALTH" 28 "ABORT_THERMAL_ISSUE" 27 "ABORT_CONTROLLER_NOT_ALLOWED" 26 "ABORT_CONTROLLER_SOLVER" 25 "ABORT_CONTROLLER_REFERENCE" 24 "ABORT_ROAD_ESTIMATOR_HEALTH" 23 "ABORT_ACC_FAULT" 22 "ABORT_ACC_CANCEL_SILENT" 21 "ABORT_ACC_CANCEL_GENERIC" 20 "ABORT_RADAR_FAULT" 19 "ABORT_RADAR_BLIND" 18 "ABORT_CAMERA_CALIBRATION" 17 "ABORT_CAMERA_FAILSAFES" 16 "ABORT_EPAS_EAC_ERROR" 15 "ABORT_EPAS_EAC_NOT_ACTIVE" 14 "ABORT_VEHICLE_SPEED_ABOVE_MAX" 13 "ABORT_TRAILER_MODE_ACTIVE" 12 "ABORT_USER_DISABLED" 11 "ABORT_CRUISE_NOT_ACTIVE" 10 "ABORT_CRUISE_FAULT" 9 "ABORT_VCRIGHT_MIA" 8 "ABORT_VCFRONT_MIA" 7 "ABORT_RADAR_MIA" 6 "ABORT_SCCM_MIA" 5 "ABORT_GTW_MIA" 4 "ABORT_EPAS_MIA" 3 "ABORT_ESP_MIA" 2 "ABORT_DI_MIA" 1 "ABORT_WATCHDOG_HEALTH" 0 "ABORT_NONE" ;
VAL_ 583 DAS_rqstedBehaviorStatus 22 "RQST_BEHAVIOR_INVALID_PLAN" 21 "RQST_BEHAVIOR_BLOCKED_BY_SLOW_TARGET_R" 20 "RQST_BEHAVIOR_BLOCKED_BY_SLOW_TARGET_L" 19 "RQST_BEHAVIOR_BAD_ORIGIN_UPDATE" 18 "RQST_BEHAVIOR_OUT_OF_DATE" 17 "RQST_BEHAVIOR_ROAD_NOT_APPROPRIATE" 16 "RQST_BEHAVIOR_BLOCKED_BY_LANE_TYPE_R" 15 "RQST_BEHAVIOR_BLOCKED_BY_ULTRASOUND_AND_CAMERA_R" 14 "RQST_BEHAVIOR_BLOCKED_BY_BLINDSPOT_CAMERA_INVALID_R" 13 "RQST_BEHAVIOR_BLOCKED_BY_BLINDSPOT_CAMERA_R" 12 "RQST_BEHAVIOR_BLOCKED_BY_ULTRASOUND_R" 11 "RQST_BEHAVIOR_BLOCKED_BY_LANE_TYPE_L" 10 "RQST_BEHAVIOR_BLOCKED_BY_ULTRASOUND_AND_CAMERA_L" 9 "RQST_BEHAVIOR_BLOCKED_BY_BLINDSPOT_CAMERA_INVALID_L" 8 "RQST_BEHAVIOR_BLOCKED_BY_BLINDSPOT_CAMERA_L" 7 "RQST_BEHAVIOR_BLOCKED_BY_ULTRASOUND_L" 6 "RQST_BEHAVIOR_BUILD_ARGUMENT_FAIL" 5 "RQST_BEHAVIOR_NO_TARGET_LANE_ON_MAP" 4 "RQST_BEHAVIOR_NO_SOURCE_LANE_ON_MAP" 3 "RQST_BEHAVIOR_MAP_NOT_INITIALIZED" 2 "RQST_BEHAVIOR_NO_DEST_POLYLANE" 1 "RQST_BEHAVIOR_NO_SRC_POLYLANE" 0 "RQST_BEHAVIOR_VALID" ;
VAL_ 583 DAS_forkState 29 "FORK_AWAITING_CONFIRMATION_RIGHT" 28 "FORK_AWAITING_CONFIRMATION_LEFT" 27 "FORK_UNAVAILABLE_INTERSECTION_ACTIVE" 26 "FORK_PRE_ACTIVE_RIGHT_NAV" 25 "FORK_PRE_ACTIVE_LEFT_NAV" 24 "FORK_UNAVAILABLE_WEATHER" 23 "FORK_UNAVAILABLE_TIGHT_TURN_RADIUS" 22 "FORK_ABORT_OTHER" 21 "FORK_ABORT_DISALLOW" 20 "FORK_ABORT_NOT_RIGHT_LANE" 19 "FORK_ABORT_NOT_LEFT_LANE" 18 "FORK_ABORT_BLINKER_CHANGE" 17 "FORK_ABORT_CONTROL_INACTIVE" 16 "FORK_FORK_COMPLETE" 15 "FORK_ACTIVE_RIGHT_USER" 14 "FORK_ACTIVE_RIGHT_NAV" 13 "FORK_ACTIVE_LEFT_USER" 12 "FORK_ACTIVE_LEFT_NAV" 11 "FORK_IDLE_NO_FORKS_AVAILABLE" 10 "FORK_IDLE_RIGHT_FORK_AVAILABLE" 9 "FORK_IDLE_LEFT_FORK_AVAILABLE" 8 "FORK_IDLE_BOTH_FORKS_AVAILABLE" 7 "FORK_UNAVAILABLE_OTHER" 6 "FORK_UNAVAILABLE_TOLL_BOOTH" 5 "FORK_UNAVAILABLE_DON_INACTIVE" 4 "FORK_UNAVAILABLE_CONTROLLED_ACCESS_TOO_FAR" 3 "FORK_UNAVAILABLE_CONSTRUCTION" 2 "FORK_UNAVAILABLE_AP_INACTIVE" 1 "FORK_UNAVAILABLE_DISABLED" 0 "FORK_INVALID" ;
VAL_ 583 DAS_laneChangeState 63 "LANE_CHANGE_UNKNOWN" 43 "LANE_CHANGE_ABORTING_DESTINATION_LANE_UNSTABLE" 42 "LANE_CHANGE_UNAVAILABLE_AUTOPILOT_ABORTING" 41 "LANE_CHANGE_UNAVAILABLE_BLINKER_LATCHED" 40 "LANE_CHANGE_ABORTING_SNOOZED" 39 "LANE_CHANGE_ABORTING_SOURCE_AND_TARGET_LANES_MERGED" 38 "LANE_CHANGE_UNAVAILABLE_NO_REAR_OBJECT" 37 "LANE_CHANGE_ABORTING_NO_HANDS_ON" 36 "LANE_CHANGE_UNAVAILABLE_BLINDSPOT_RESTRICTED" 35 "LANE_CHANGE_ABORTING_WEATHER" 34 "LANE_CHANGE_ABORTING_TIGHT_TURN_RADIUS" 33 "LANE_CHANGE_ABORTING_TOLL_BOOTH_DETECTED" 32 "LANE_CHANGE_ABORTING_CONSTRUCTION_DETECTED" 31 "LANE_CHANGE_ABORTING_GORE_POINT" 30 "LANE_CHANGE_BLOCKED_RIGHT" 29 "LANE_CHANGE_BLOCKED_LEFT" 28 "LANE_CHANGE_IN_PROGRESS_RIGHT" 27 "LANE_CHANGE_IN_PROGRESS_LEFT" 26 "LANE_CHANGE_ABORTING_ALC_REQUEST_BEFORE_ULC_CONFIRM" 25 "LANE_CHANGE_ABORTING_ULC_CONFIRMATION_TIMEOUT" 24 "LANE_CHANGE_ABORTING_HIGH_ALC_PROGRESS_ERROR" 23 "LANE_CHANGE_ABORTING_BEHAVIOR_CHANGED" 22 "LANE_CHANGE_ABORTING_BELOW_MIN_SPEED" 21 "LANE_CHANGE_ABORTING_INVALID_BEHAVIOR" 20 "LANE_CHANGE_ABORTING_ULC_BLINKER_TIMEOUT" 19 "LANE_CHANGE_ABORTING_ACC_AUTOSTEER_ACTIVATED" 18 "LANE_CHANGE_ABORTING_LOST_VISION_POSE" 17 "LANE_CHANGE_ABORTING_FORK_AVAILABLE" 16 "LANE_CHANGE_ABORTING_LINE_TYPE" 15 "LANE_CHANGE_ABORTING_INVALID_MODE" 14 "LANE_CHANGE_ABORTING_BLIND_SPOT_OCCUPIED" 13 "LANE_CHANGE_ABORTING_TIMEOUT" 12 "LANE_CHANGE_ABORTING_BLINKER" 11 "LANE_CHANGE_ABORTING_INACTIVE" 10 "LANE_CHANGE_AVAILABLE_BOTH" 9 "LANE_CHANGE_AVAILABLE_RIGHT_ONLY" 8 "LANE_CHANGE_AVAILABLE_LEFT_ONLY" 7 "LANE_CHANGE_UNAVAILABLE_INVALID_MODE" 6 "LANE_CHANGE_UNAVAILABLE_ULTRASONICS_NOT_READY" 5 "LANE_CHANGE_UNAVAILABLE_FORK_MODE" 4 "LANE_CHANGE_UNAVAILABLE_INACTIVE" 3 "LANE_CHANGE_UNAVAILABLE_NO_LANES" 2 "LANE_CHANGE_UNAVAILABLE_SPEED" 1 "LANE_CHANGE_UNAVAILABLE_ROAD_NOT_APPROPRIATE" 0 "LANE_CHANGE_UNAVAILABLE_DISABLED" ;
VAL_ 583 DAS_lastWatchdogCode 127 "TRIP_HISTORY_FAILED" 126 "TEXT_LOG_FAILED" 125 "AUTOPILOT_OBJECT_POSE_FAILED" 124 "RELOCALIZATION_FAILED" 123 "SLAM_MAPPING_FAILED" 122 "SLAM_BATCH_CALIB_FAILED" 121 "SLAM_BA_FAILED" 120 "SLAM_FAILED" 119 "RTDV_STREAMER_FAILED" 118 "RTDV_COMPRESSOR_FAILED" 117 "REPLAY_FAILED" 116 "REMOTE_ACCESS_FAILED" 115 "PT_TRACKER_FAILED" 114 "PERFORMANCE_COUNTER_MONITOR_FAILED" 113 "METRICS_DEV_FAILED" 112 "METRICS_API_FAILED" 111 "METRICS_FAILED" 110 "LOGGING_LOAD_GENERATOR_FAILED" 109 "LIDAR_FAILED" 108 "HTTP_SERVER_FAILED" 107 "FRAME_DECODER_FAILED" 106 "INFERENCE_ENGINE_FAILED" 105 "FACTORY_CAMERA_CALIBRATION_FAILED" 104 "DV_INSPECTOR_FAILED" 103 "DETERMINATOR_FAILED" 102 "DASH_CAM_FAILED" 101 "CLIP_REMOTE_WRITER_FAILED" 100 "COMPRESSOR_FAILED" 99 "FTRACE_SNAPSHOT_FAILED" 98 "SWITCH_MONITOR_FAILED" 97 "BLUEFIN_FAILED" 96 "BACKUP_CAMERA_FAILED" 95 "AUTONOMOUS_BEHAVIORS_FAILED" 94 "AUDIO_PROCESSOR_FAILED" 93 "CAMERA_HEALTH_FAILED" 92 "POSITIONING_ENGINE_FAILED" 91 "AUDIO_FAILED" 90 "IMU_CALIBRATION_FAILED" 89 "RADAR_EXTENDED_FAILED" 88 "TILE_PROVIDER_FAILED" 87 "RADAR_RECEIVER_FAILED" 86 "TELEMETRY_COMPLIANCE_FAILED" 85 "GEO_REGION_FAILED" 84 "FLEET_CONFIG_FAILED" 83 "X1_CLIENT_FAILED" 82 "SYNC_PIPELINE_FAILED" 81 "RADAR_FAILED" 80 "ULTRASONICS_FAILED" 79 "BEV_GRAPH_FAILED" 78 "CITY_STREETS_BEHAVIOR_FAILED" 77 "BRIDGE_FAILED" 76 "SCHEDULER_FAILED" 75 "DRIVABLE_SPACE_TRACKER_FAILED" 74 "CLIP_LOGGER_FAILED" 73 "HW_MONITOR_FAILED" 72 "PARKING_BEHAVIOR_FAILED" 71 "FIELD_CALIBRATION_FAILED" 70 "DYNAMICS_FAILED" 69 "UI_SERVER_FAILED" 68 "ACTIVE_SAFETY_FAILED" 67 "CAMERA_FAILED" 66 "MAP_MANAGER_FAILED" 65 "DRIVER_MONITOR_FAILED" 64 "MODEL_TOOLS_FAILED" 63 "LANE_CHANGE_BEHAVIOR_FAILED" 62 "UBX_LOG_FAILED" 61 "IMU_FAILED" 60 "RAIN_LIGHT_SENSING_FAILED" 59 "SNAPSHOT_TRIGGER_CLIENT_FAILED" 58 "STAY_IN_LANE_BEHAVIOR_FAILED" 57 "ATLAS_FAILED" 56 "ROAD_ESTIMATOR_FAILED" 55 "PERCEPTION_FAILED" 54 "MISSION_PLANNER_FAILED" 53 "LOCALIZER_FAILED" 52 "CONTROLLER_FAILED" 51 "AP_STATE_MACHINE_FAILED" 50 "ARBITER_FAILED" 49 "GPS_FAILED" 48 "INERTIATOR_FAILED" 47 "TEMPERATURE_MONITOR_FAILED" 46 "CAN_TX_FAILED" 45 "CAN_RX_FAILED" 44 "WATCHDOG_FAILED" 43 "LEGACY_FAILED" 42 "VISION_FAILED" 41 "SNAPSHOT_FAILED" 40 "TELEMETRY_FAILED" 39 "TELEMETRY_PACKAGER_FAILED" 30 "UNKNOWN_TASK_FAILED" 0 "NO_TASK_FAILED" ;
VAL_ 1001 DAS_headlightRequest 3 "DAS_HEADLIGHT_REQUEST_INVALID" 2 "DAS_HEADLIGHT_REQUEST_TAIL_LIGHTS_ONLY" 1 "DAS_HEADLIGHT_REQUEST_ON" 0 "DAS_HEADLIGHT_REQUEST_OFF" ;
VAL_ 1001 DAS_hazardLightRequest 3 "DAS_REQUEST_HAZARDS_SNA" 2 "DAS_REQUEST_HAZARDS_ON_FAST" 1 "DAS_REQUEST_HAZARDS_ON" 0 "DAS_REQUEST_HAZARDS_OFF" ;
VAL_ 1001 DAS_wiperSpeed 15 "DAS_WIPER_SPEED_INVALID" 14 "DAS_WIPER_SPEED_14" 13 "DAS_WIPER_SPEED_13" 12 "DAS_WIPER_SPEED_12" 11 "DAS_WIPER_SPEED_11" 10 "DAS_WIPER_SPEED_10" 9 "DAS_WIPER_SPEED_9" 8 "DAS_WIPER_SPEED_8" 7 "DAS_WIPER_SPEED_7" 6 "DAS_WIPER_SPEED_6" 5 "DAS_WIPER_SPEED_5" 4 "DAS_WIPER_SPEED_4" 3 "DAS_WIPER_SPEED_3" 2 "DAS_WIPER_SPEED_2" 1 "DAS_WIPER_SPEED_1" 0 "DAS_WIPER_SPEED_OFF" ;
VAL_ 1001 DAS_turnIndicatorRequest 4 "DAS_TURN_INDICATOR_DEFER" 3 "DAS_TURN_INDICATOR_CANCEL" 2 "DAS_TURN_INDICATOR_RIGHT" 1 "DAS_TURN_INDICATOR_LEFT" 0 "DAS_TURN_INDICATOR_NONE" ;
VAL_ 1001 DAS_highLowBeamDecision 3 "DAS_HIGH_BEAM_SNA" 2 "DAS_HIGH_BEAM_ON" 1 "DAS_HIGH_BEAM_OFF" 0 "DAS_HIGH_BEAM_UNDECIDED" ;
VAL_ 1001 DAS_heaterRequest 2 "DAS_HEATER_ON" 1 "DAS_HEATER_OFF" 0 "DAS_HEATER_SNA" ;
VAL_ 1001 DAS_highLowBeamOffReason 5 "HIGH_BEAM_OFF_REASON_SNA" 4 "HIGH_BEAM_OFF_REASON_HEAD_LIGHT" 3 "HIGH_BEAM_OFF_REASON_AMBIENT_LIGHT" 2 "HIGH_BEAM_OFF_REASON_MOVING_RADAR_TARGET" 1 "HIGH_BEAM_OFF_REASON_MOVING_VISION_TARGET" 0 "HIGH_BEAM_ON" ;
VAL_ 1001 DAS_mirrorFoldRequest 3 "DAS_MIRROR_REQUEST_SNA" 2 "DAS_MIRROR_REQUEST_UNFOLD" 1 "DAS_MIRROR_REQUEST_FOLD" 0 "DAS_MIRROR_REQUEST_NONE" ;
VAL_ 1001 DAS_autoWiperState 5 "DAS_AUTO_WIPER_STATE_SNA" 4 "DAS_AUTO_WIPER_STATE_FAST_CONTINUOUS" 3 "DAS_AUTO_WIPER_STATE_SLOW_CONTINUOUS" 2 "DAS_AUTO_WIPER_STATE_FAST_INTERMITTENT" 1 "DAS_AUTO_WIPER_STATE_SLOW_INTERMITTENT" 0 "DAS_AUTO_WIPER_STATE_OFF" ;
VAL_ 1001 DAS_turnIndicatorRequestReason 24 "DAS_ACTIVE_SIMULTANEOUS_LANE_CHANGE_AVOIDANCE" 23 "DAS_ACTIVE_INFEASIBLE_KINEMATICS_LANE_CHANGE" 22 "DAS_ACTIVE_STAY_OUT_OF_RIGHTMOST_LANE_LANE_CHANGE" 21 "DAS_ACTIVE_AWAY_FROM_MERGE_LANE_CHANGE" 20 "DAS_ACTIVE_EXIT_RIGHT_LANE_LANE_CHANGE" 19 "DAS_ACTIVE_EXIT_PASSING_LANE_LANE_CHANGE" 18 "DAS_ACTIVE_INCORRECT_ROAD_SIDE_LANE_CHANGE" 17 "DAS_ACTIVE_STATIC_OBJECT_LANE_CHANGE" 15 "DAS_CANCEL_MANUAL_BLINKER" 14 "DAS_CANCEL_AUTO_PARK" 13 "DAS_ACTIVE_AUTO_PARK" 12 "DAS_CANCEL_SUMMMON" 11 "DAS_ACTIVE_SUMMMON" 10 "DAS_CANCEL_INTERSECTION" 9 "DAS_ACTIVE_INTERSECTION" 8 "DAS_ACTIVE_COMMANDED_LANE_CHANGE" 7 "DAS_CANCEL_MERGE" 6 "DAS_ACTIVE_MERGE" 5 "DAS_CANCEL_FORK" 4 "DAS_CANCEL_LANE_CHANGE" 3 "DAS_ACTIVE_FORK" 2 "DAS_ACTIVE_SPEED_LANE_CHANGE" 1 "DAS_ACTIVE_NAV_LANE_CHANGE" 0 "DAS_NONE" ;
VAL_ 1001 DAS_restrictDoorReleaseLeft 1 "RESTRICT_DOOR_RELEASE_ACTIVE" 0 "RESTRICT_DOOR_RELEASE_INACTIVE" ;
VAL_ 1001 DAS_restrictDoorReleaseRight 1 "RESTRICT_DOOR_RELEASE_ACTIVE" 0 "RESTRICT_DOOR_RELEASE_INACTIVE" ;
VAL_ 1497 DAS_associated_rad_object 3 "ACC1" 2 "ACC5" 1 "OTHER" 0 "NONE" ;
VAL_ 1497 DAS_LC_handsOnReason 63 "VISUAL_DCAS_BOUNDARY_CONDITION" 62 "VISUAL_DCAS_STRICT_PHONE_USE" 61 "VISUAL_DCAS_EYES_ON_REQUEST_FAST" 60 "VISUAL_EYE_GAZE_AVERSION" 59 "VISUAL_NO_EYE_GAZE_DEVIATION" 58 "CHIME1_DCAS_STRICT_PHONE_USE" 57 "VISUAL_DCAS_EYES_ON_REQUEST" 56 "CHIME1_DCAS_EYES_ON_REQUEST_FAST" 55 "CHIME1_DCAS_EYES_ON_REQUEST" 54 "CHIME1_NO_EYE_GAZE_DEVIATION" 53 "VISUAL_ATTN_MONITORING_UNAVAILABLE" 52 "VISUAL_DRIVER_HANDS_NOT_READY" 51 "VISUAL_TIMEOUT_SUNGLASSES" 50 "CHIME1_REACHING_AFTER_AP_ACTIVATION" 49 "VISUAL_DRIVER_POSSIBLY_DISTRACTED" 48 "VISUAL_DRIVER_LOW_ATTENTION_SCORE" 47 "VISUAL_DRIVER_LOSS_OF_ATTENTION" 46 "VISUAL_VRU_FAILSAFE" 45 "VISUAL_VRU_IN_DRIVE_SPACE" 44 "CHIME1_UPCOMING_TRAFFIC_CONTROL" 43 "CHIME1_HANDS_OFF_AFTER_AP_ACTIVATION" 42 "VISUAL_UPCOMING_TRAFFIC_CONTROL" 41 "CHIME1_DISTRACTED_AFTER_AP_ACTIVATION" 40 "VISUAL_DRIVER_STATE_UNKNOWN" 39 "VISUAL_TIMEOUT_DRIVER_NOT_LIVELY" 38 "VISUAL_TIMEOUT_TORQUE_OFFSET_UNCALIBRATED" 37 "CHIME1_REFERENCE_LATERAL_ERROR" 36 "CHIME1_STREET_CAR" 35 "CHIME1_SEALED_MERGE_WARNING" 34 "CHIME1_CAUTION_LIGHTS" 33 "CHIME1_CAPTIVE_EXIT" 32 "CHIME1_CRITICAL_TRAFFIC_CONTROL" 31 "VISUAL_POOR_VISIBILITY" 30 "CHIME1_DRIVER_DISTRACTED" 29 "DEFEAT_DEVICE_DETECTED" 28 "VISUAL_TRAFFIC_CONTROLS" 27 "CHIME1_EXTREME_WEATHER" 26 "VISUAL_POOR_WEATHER" 25 "VISUAL_STOP_AND_GO" 24 "VISUAL_TIMEOUT_HOMOLOGATION" 23 "VISUAL_ULC_REQUEST" 22 "CHIME1_TOLL_BOOTH" 21 "CHIME1_STATIONARY_RADAR" 20 "CHIME1_DRIVABLE_SPACE_VIOLATION" 19 "CHIME1_RE_DEGRADED_MEASUREMENTS" 18 "CHIME1_NO_LINES" 17 "VISUAL_ALC" 16 "VISUAL_LATERAL_ACCELERATION" 15 "VISUAL_TIMEOUT_ACCELERATOR" 14 "VISUAL_TIMEOUT_RESTRICTED" 13 "VISUAL_TIMEOUT_NO_CIPV" 12 "VISUAL_TIMEOUT_CIPV" 11 "VISUAL_TIMEOUT_CUTOUT_CIPV" 10 "VISUAL_TIMEOUT_CONSTRUCTION" 9 "VISUAL_TIMEOUT_LOW_SPEED" 8 "VISUAL_TIMEOUT_MED_SPEED" 7 "VISUAL_TIMEOUT_HI_SPEED" 6 "VISUAL_TIMEOUT_LONG_TERM" 5 "VISUAL_DRIVER_NOT_PRESENT" 4 "VISUAL_FUSION_MODEL" 3 "VISUAL_FUSION_NAV" 2 "CHIME1_CONSTRUCTION" 1 "CHIME1_ANGLE_SATURATION" 0 "LC_HANDS_ON_REASON_NONE" ;
VAL_ 1497 DAS_ACC_camStatus 3 "ACC_CAM_STATUS_FAULT" 2 "ACC_CAM_STATUS_SQUINTING" 1 "ACC_CAM_STATUS_BLIND" 0 "ACC_CAM_STATUS_HEALTHY" ;
VAL_ 1497 DAS_aeb_not_activating_reason 22 "LCM_AEB_SENSORS_DO_NOT_AGREE" 21 "LCM_AEB_NOT_RADAR_CIPV" 20 "LCM_AEB_LANE_ASSIGNMENT_AGE" 19 "LCM_AEB_COLLISION_COURSE_TIME" 18 "LCM_AEB_TRACK_CONSISTENCY" 17 "LCM_AEB_DRIVABLE_SPACE" 16 "LCM_AEB_PATH_OVERLAP" 15 "LCM_AEB_RAD_NOT_ASSOCIATED" 14 "LCM_AEB_CAM_NOT_ASSOCIATED" 13 "LCM_AEB_CAMERA_CROSS_CHECK" 12 "LCM_AEB_YOUNG_TRACK" 11 "LCM_AEB_OTHER" 10 "LCM_AEB_ACTIVE" 9 "LCM_AEB_OVERRIDE" 8 "LCM_AEB_DELAYED_EVADING_DISTANCE" 7 "LCM_AEB_DELAYED_REQUIRED_ACCELERATION" 6 "LCM_AEB_CURRENT_REQUIRED_ACCELERATION" 5 "LCM_AEB_COLLISION_OVERLAP_RATIO" 4 "LCM_AEB_RELATIVE_VELOCITY" 3 "LCM_AEB_ABSOLUTE_ACCELERATION" 2 "LCM_AEB_NO_COLLISION_OBJECT" 1 "LCM_AEB_UNAVAILABLE" 0 "LCM_AEB_FAULT" ;
VAL_ 1497 DAS_handsOnDetected 2 "HANDS_ON_DETECTED" 1 "HANDS_ON_NOT_DETECTED" 0 "HANDS_ON_SNA" ;
VAL_ 1497 DAS_driveOnNavUnavailableReason 25 "DON_BLINKER_FAULTED" 24 "DON_UNAVAILABLE_AUDIO" 23 "DON_SCENE_TAG_SUN_GLARE" 22 "DON_SCENE_TAG_SEVERE_WEATHER" 21 "DON_SCENE_TAG_LENS_FLARE" 20 "DON_SCENE_TAG_FULLY_BLOCKED" 19 "DON_SCENE_TAG_FOG" 18 "DON_SCENE_TAG_BLURRY" 17 "DON_SCENE_TAG_BAD_CAMERA" 16 "DON_NAV_ROUTE_NOT_ACTIVE" 15 "DON_FEATURE_NOT_ENABLED" 14 "DON_AUTOPILOT_UNAVAILABLE" 13 "DON_INCOMPATIBLE_WAY" 12 "DON_HIGH_CURVATURE" 11 "DON_TOLLBOOTH_DETECTED" 10 "DON_CONSTRUCTION_DETECTED" 9 "DON_AUTO_WIPER_ACTIVE" 8 "DON_IMPLAUSIBLE_MAP_DATA" 7 "DON_GPS_DEGRADED" 6 "DON_ULTRASONICS_INVALID" 5 "DON_EDGE_LOCALIZATION_FAILED" 4 "DON_ROUTE_DOWNLOAD_FAILED" 3 "DON_UNAVAILABLE_CAMERA_BLOCKED" 2 "DON_CAMERA_UNAVAILABLE" 1 "DON_INVALID_NAV_GOAL" 0 "DON_UNAVAILABLE_NONE" ;
VAL_ 1497 DAS_accUnavailableReason 76 "ACC_UNAVAILABLE_REASON_SEATBELT_UNBUCKLED" 75 "ACC_UNAVAILABLE_REASON_DOOR_OPEN" 74 "ACC_UNAVAILABLE_REASON_FRUNK_OPEN" 73 "ACC_UNAVAILABLE_REASON_TRUNK_OPEN" 72 "ACC_UNAVAILABLE_REASON_OFF_ROAD_MODE_ACTIVE" 71 "ACC_UNAVAILABLE_REASON_SUPPRESS_FOR_RECENT_SCROLL_WHEEL_INTERACTION" 70 "ACC_UNAVAILABLE_REASON_SUPPRESS_FOR_RECENT_AUTOPARK_ACTIVATION" 69 "ACC_UNAVAILABLE_REASON_USER_SETTINGS_NOT_SUPPORTED" 68 "ACC_UNAVAILABLE_REASON_AUTOSTEER_INACTIVE_FOR_SINGLE_CLICK" 67 "ACC_UNAVAILABLE_REASON_AUTOSTEER_UNAVAILABLE_FOR_SINGLE_CLICK" 66 "ACC_UNAVAILABLE_REASON_TASK_FLOW_TRACE_TIMEOUT_SLAM" 65 "ACC_UNAVAILABLE_REASON_TASK_FLOW_TRACE_TIMEOUT_LOCALIZATION" 64 "ACC_UNAVAILABLE_REASON_TASK_FLOW_TRACE_TIMEOUT_STATIC_WORLD" 63 "ACC_UNAVAILABLE_REASON_TASK_FLOW_TRACE_TIMEOUT_DYNAMIC_WORLD" 62 "ACC_UNAVAILABLE_REASON_TASK_FLOW_TRACE_TIMEOUT_UNKNOWN" 61 "ACC_UNAVAILABLE_REASON_EXTENDED_COMPUTE_INACTIVE_PCIE_LINK_HEALTH" 60 "ACC_UNAVAILABLE_REASON_EXTENDED_COMPUTE_INACTIVE_ETHERNET_LINK_HEALTH" 59 "ACC_UNAVAILABLE_REASON_EXTENDED_COMPUTE_INACTIVE_OTHER_SOC_HEALTH_CRITICAL" 58 "ACC_UNAVAILABLE_REASON_EXTENDED_COMPUTE_INACTIVE_OTHER_SOC_HEALTH_UNKNOWN" 57 "ACC_UNAVAILABLE_REASON_AHB_MANUAL_OVERRIDE" 56 "ACC_UNAVAILABLE_REASON_EXTENDED_COMPUTE_INACTIVE" 55 "ACC_UNAVAILABLE_REASON_DRIVER_NOT_PRESENT" 54 "ACC_UNAVAILABLE_REASON_LOW_ODOMETRY" 53 "ACC_UNAVAILABLE_REASON_PERCEPTION_HEALTH_STALE" 52 "ACC_UNAVAILABLE_REASON_PERCEPTION_HEALTH_POST_PROCESSING" 51 "ACC_UNAVAILABLE_REASON_RECENT_USER_CANCELLATION" 50 "ACC_UNAVAILABLE_REASON_CITY_STREETS_REF_TOO_SHORT" 49 "ACC_UNAVAILABLE_REASON_INVALID_BEHAVIOR" 48 "ACC_UNAVAILABLE_REASON_RECENT_GEAR_SHIFT" 47 "ACC_UNAVAILABLE_REASON_IBOOSTER_MIA" 46 "ACC_UNAVAILABLE_INTEGRATOR_HEALTH_CRITICAL" 45 "ACC_UNAVAILABLE_REASON_UNKNOWN" 44 "ACC_UNAVAILABLE_REASON_RADAR_VERSION_MISMATCH" 43 "ACC_UNAVAILABLE_REASON_AP_NOT_CONFIGURED" 42 "ACC_UNAVAILABLE_REASON_INVALID_VEHICLE_SPEED" 41 "ACC_UNAVAILABLE_REASON_INVALID_DI_PEDAL_POS" 40 "ACC_UNAVAILABLE_REASON_W048_FEATURES_DISABLED" 39 "ACC_UNAVAILABLE_REASON_FAILED_AUTOSTEER_ACTIVATION" 38 "ACC_UNAVAILABLE_REASON_AEB_ACTIVE" 37 "ACC_UNAVAILABLE_REASON_AVAILABILITY_CHECK_HYSTERESIS" 36 "ACC_UNAVAILABLE_REASON_SONIC_OBSTACLE_DETECTED" 35 "ACC_UNAVAILABLE_REASON_TRACKED_OBSTACLE_DETECTED" 34 "ACC_UNAVAILABLE_REASON_STEERING_WHEEL_ANGLE" 33 "ACC_UNAVAILABLE_REASON_ROAD_CLASS" 32 "ACC_UNAVAILABLE_REASON_BELOW_MIN_SPEED" 31 "ACC_UNAVAILABLE_REASON_PEDESTRIAN_PRESENT_OR_NO_VEHICLE" 30 "ACC_UNAVAILABLE_REASON_BELOW_MAX_UNAVAILABLE_SPEED" 29 "ACC_UNAVAILABLE_REASON_ESP_PARTY_MIA" 28 "ACC_UNAVAILABLE_REASON_EPAS_PARTY_MIA" 27 "ACC_UNAVAILABLE_REASON_DI_PARTY_MIA" 26 "ACC_UNAVAILABLE_REASON_ECU_THERMAL_ISSUE" 25 "ACC_UNAVAILABLE_REASON_CAMERA_FAILSAFES" 24 "ACC_UNAVAILABLE_REASON_ESP_MIA" 23 "ACC_UNAVAILABLE_REASON_EPAS_MIA" 22 "ACC_UNAVAILABLE_REASON_GTW_MIA" 21 "ACC_UNAVAILABLE_REASON_DI_MIA" 20 "ACC_UNAVAILABLE_REASON_NOT_IN_DRIVE" 19 "ACC_UNAVAILABLE_REASON_CONTROLLER_INDETERMINATE" 18 "ACC_UNAVAILABLE_REASON_CONTROLLER_REFERENCE_TOO_SHORT" 17 "ACC_UNAVAILABLE_REASON_CONTROLLER_BAD_UPDATE" 16 "ACC_UNAVAILABLE_REASON_CONTROLLER_STALE_LOCALIZATION" 15 "ACC_UNAVAILABLE_REASON_CONTROLLER_STALE_REFERENCE" 14 "ACC_UNAVAILABLE_REASON_CONTROLLER_REFERENCE_UNHEALTHY" 13 "ACC_UNAVAILABLE_REASON_CONTROLLER_SOLVER_UNHEALTHY" 12 "ACC_UNAVAILABLE_REASON_CONTROLLER_NOT_ALLOWED" 11 "ACC_UNAVAILABLE_REASON_CAMERA_CALIBRATION" 10 "ACC_UNAVAILABLE_REASON_CAMERA_PITCH" 9 "ACC_UNAVAILABLE_REASON_CAMERA_BLOCKED" 8 "ACC_UNAVAILABLE_REASON_RADAR_MIA" 7 "ACC_UNAVAILABLE_REASON_RADAR_FAULT" 6 "ACC_UNAVAILABLE_REASON_RADAR_BLIND" 5 "ACC_UNAVAILABLE_REASON_PERCEPTION_HEALTH_VISION" 4 "ACC_UNAVAILABLE_REASON_PERCEPTION_HEALTH_RADAR" 3 "ACC_UNAVAILABLE_REASON_DI_CRUISE_STATE_CRITICAL" 2 "ACC_UNAVAILABLE_REASON_AUTOPARK_STATE" 1 "ACC_UNAVAILABLE_REASON_SYSTEM_HEALTH_CRITICAL" 0 "ACC_UNAVAILABLE_REASON_NONE" ;
VAL_ 1497 DAS_pmmNotActivatingReason 24 "PMM_NOT_ACTIVATING_OTHER" 23 "PMM_NOT_ACTIVATING_DI_STATUS" 22 "PMM_NOT_ACTIVATING_HARDWARE_NOT_SUPPORTED" 21 "PMM_NOT_ACTIVATING_DYNAMIC_BARRIER" 20 "PMM_NOT_ACTIVATING_TRAILER_MODE" 19 "PMM_NOT_ACTIVATING_DROPPED_CIPV" 18 "PMM_NOT_ACTIVATING_SPEED_DERIVATIVE" 17 "PMM_NOT_ACTIVATING_SCENE_TAG" 16 "PMM_NOT_ACTIVATING_MODE" 15 "PMM_NOT_ACTIVATING_SPEED_PROFILE" 14 "PMM_NOT_ACTIVATING_INSEVERE_CIPV" 13 "PMM_NOT_ACTIVATING_WHEEL_ACCELERATION" 12 "PMM_NOT_ACTIVATING_ULTRASONIC_VELOCITY" 11 "PMM_NOT_ACTIVATING_ULTRASONIC_DISTANCE" 10 "PMM_NOT_ACTIVATING_USER_DISABLED" 9 "PMM_NOT_ACTIVATING_ROAD" 8 "PMM_NOT_ACTIVATING_SDI_HEALTH" 7 "PMM_NOT_ACTIVATING_VEHICLE_SPEED" 6 "PMM_NOT_ACTIVATING_TRACK_MODE" 5 "PMM_NOT_ACTIVATING_GEAR" 4 "PMM_NOT_ACTIVATING_PEDAL_RATE" 3 "PMM_NOT_ACTIVATING_PEDAL_POS" 2 "PMM_NOT_ACTIVATING_OBSTACLE_GRID" 1 "PMM_NOT_ACTIVATING_APP_FEATURES_NOT_AVAILABLE" 0 "PMM_NOT_ACTIVATING_NONE" ;
VAL_ 697 DAS_accState 15 "FAULT_SNA" 13 "ACC_CANCEL_GENERIC_SILENT" 12 "ACC_PARK" 11 "APC_SELFPARK_START" 10 "APC_UNPARK_COMPLETE" 9 "APC_PAUSE" 8 "APC_ABORT" 7 "APC_COMPLETE" 6 "APC_FORWARD" 5 "APC_BACKWARD" 4 "ACC_ON" 3 "ACC_HOLD" 2 "ACC_FORWARD" 1 "ACC_BACKWARD" 0 "ACC_CANCEL_GENERIC" ;
VAL_ 697 DAS_aebEvent 3 "AEB_SNA" 2 "AEB_FAULT" 1 "AEB_ACTIVE" 0 "AEB_NOT_ACTIVE" ;
VAL_ 2041 DAS_gpsTransportModeState 1 "DAS_GPS_TRANSPORT_MODE_ON" 0 "DAS_GPS_TRANSPORT_MODE_OFF" ;
VAL_ 2041 DAS_gpsWheelsOffMotionDetected 1 "DAS_GPS_MOTION_DETECTED_ON" 0 "DAS_GPS_MOTION_DETECTED_OFF" ;
VAL_ 2041 DAS_gpsFixTypeHardware 6 "DEAD_RECOCKONING_FIX" 5 "FLOAT_RTK_FIX" 4 "REAL_TIME_KINEMATICS_FIX" 3 "PPS_FIX" 2 "DGPS_FIX" 1 "GPS_FIX" 0 "INVALID_FIX" ;
VAL_ 2041 DAS_gpsFixTypeSoftware 6 "DEAD_RECOCKONING_FIX" 5 "FLOAT_RTK_FIX" 4 "REAL_TIME_KINEMATICS_FIX" 3 "PPS_FIX" 2 "DGPS_FIX" 1 "GPS_FIX" 0 "INVALID_FIX" ;
VAL_ 2041 DAS_gpsJammingState 3 "GPS_JAMMING_STATE_CRITICAL" 2 "GPS_JAMMING_STATE_WARNING" 1 "GPS_JAMMING_STATE_NOMINAL" 0 "GPS_JAMMING_STATE_UNKNOWN" ;
VAL_ 2041 DAS_gpsSpoofDetectorState 3 "GPS_SPOOFING_MULTIPLE_INDICATIONS" 2 "GPS_SPOOFING_INDICATION_PRESENT" 1 "GPS_SPOOFING_NO_ACTIVE_INDICATION" 0 "GPS_SPOOFING_UNKNOWN" ;
VAL_ 2041 DAS_gnssConstellationsState 2 "CONSTELLATIONS_STATE_VALID" 1 "CONSTELLATIONS_STATE_INVALID" 0 "CONSTELLATIONS_STATE_UNKNOWN" ;
VAL_ 2041 DAS_gpsResetReason 13 "GPS_RESET_PPS_MISSING" 12 "GPS_RESET_SOLUTION_INCONSISTENCY" 11 "GPS_RESET_MANUAL_COLD_RESET" 10 "GPS_RESET_GNSS_CFG_CHANGE" 9 "GPS_RESET_RESUME_CONFIGURATION_FAULT" 8 "GPS_RESET_SUSPEND_CONFIGURATION_FAULT" 7 "GPS_RESET_SATELLITE_REJECTION_TIMEOUT" 6 "GPS_RESET_ENTER_TRANSPORT_MODE" 5 "GPS_RESET_EXIT_TRANSPORT_MODE" 4 "GPS_RESET_GNSS_DATA_MISSING" 3 "GPS_RESET_UBX_MISSING" 2 "GPS_RESET_DATA_CORRUPTED" 1 "GPS_RESET_DATA_MISSING" 0 "GPS_RESET_NONE" ;
VAL_ 2041 DAS_gpsToMcuSource 4 "GPS_TO_MCU_SOURCE_BLUEFIN_SOLUTION" 3 "GPS_TO_MCU_SOURCE_TESLA_VIO_SOLUTION" 2 "GPS_TO_MCU_SOURCE_SOFTWARE_SOLUTION" 1 "GPS_TO_MCU_SOURCE_HARDWARE_SOLUTION" 0 "GPS_TO_MCU_SOURCE_UNKNOWN" ;
VAL_ 2041 DAS_gpsSolutionSoc 2 "GPS_SOLUTION_SOC_B" 1 "GPS_SOLUTION_SOC_A" 0 "GPS_SOLUTION_SOC_UNKNOWN" ;
VAL_ 2041 DAS_gpsFixTypeSoftwareSocB 6 "DEAD_RECOCKONING_FIX" 5 "FLOAT_RTK_FIX" 4 "REAL_TIME_KINEMATICS_FIX" 3 "PPS_FIX" 2 "DGPS_FIX" 1 "GPS_FIX" 0 "INVALID_FIX" ;
VAL_ 1337 DAS_infoBuildType 4 "INFO_MFG_BUILD" 3 "INFO_TRACEABLE_CI_BUILD" 2 "INFO_LOCAL_BUILD" 1 "INFO_PLATFORM_BUILD" 0 "INFO_UNKNOWN_BUILD" ;
VAL_ 569 DAS_leftLineUsage 3 "BLACKLISTED" 2 "FUSED" 1 "AVAILABLE" 0 "REJECTED_UNAVAILABLE" ;
VAL_ 569 DAS_rightLineUsage 3 "BLACKLISTED" 2 "FUSED" 1 "AVAILABLE" 0 "REJECTED_UNAVAILABLE" ;
VAL_ 569 DAS_leftFork 3 "FORK_UNAVAILABLE" 2 "FORK_SELECTED" 1 "FORK_AVAILABLE" 0 "FORK_NONE" ;
VAL_ 569 DAS_rightFork 3 "FORK_UNAVAILABLE" 2 "FORK_SELECTED" 1 "FORK_AVAILABLE" 0 "FORK_NONE" ;
VAL_ 777 DAS_leadVehType 6 "IPSO" 5 "PEDESTRIAN" 4 "BICYCLE" 3 "MOTORCYCLE" 2 "CAR" 1 "TRUCK" 0 "UNKNOWN" ;
VAL_ 777 DAS_leadVeh2Type 5 "PEDESTRIAN" 4 "BICYCLE" 3 "MOTORCYCLE" 2 "CAR" 1 "TRUCK" 0 "UNKNOWN" ;
VAL_ 777 DAS_leftVehType 5 "PEDESTRIAN" 4 "BICYCLE" 3 "MOTORCYCLE" 2 "CAR" 1 "TRUCK" 0 "UNKNOWN" ;
VAL_ 777 DAS_leftVeh2Type 5 "PEDESTRIAN" 4 "BICYCLE" 3 "MOTORCYCLE" 2 "CAR" 1 "TRUCK" 0 "UNKNOWN" ;
VAL_ 777 DAS_rightVehType 5 "PEDESTRIAN" 4 "BICYCLE" 3 "MOTORCYCLE" 2 "CAR" 1 "TRUCK" 0 "UNKNOWN" ;
VAL_ 777 DAS_rightVeh2Type 5 "PEDESTRIAN" 4 "BICYCLE" 3 "MOTORCYCLE" 2 "CAR" 1 "TRUCK" 0 "UNKNOWN" ;
VAL_ 777 DAS_cutinVehType 5 "PEDESTRIAN" 4 "BICYCLE" 3 "MOTORCYCLE" 2 "CAR" 1 "TRUCK" 0 "UNKNOWN" ;
VAL_ 777 DAS_roadSignColor 4 "RED_YELLOW" 3 "GREEN" 2 "YELLOW" 1 "RED" 0 "NONE" ;
VAL_ 777 DAS_roadSignId 1 "TRAFFIC_LIGHT" 0 "STOP_SIGN" ;
VAL_ 777 DAS_roadSignSource 2 "VISION" 1 "NAV" 0 "NONE" ;
VAL_ 777 DAS_roadSignArrow 4 "UNKNOWN" 3 "STRAIGHT" 2 "RIGHT" 1 "LEFT" 0 "CIRCLE" ;
VAL_ 777 DAS_roadSignOrientation 2 "HORIZONTAL_3_LIGHT" 1 "VERTICAL_3_LIGHT" 0 "UNKNOWN" ;
